VERSION "HINBNNNYNNNNNNNNNNNNNNNNNNNNNNNNNNNYYNNNNN/4>%%%/4/'%**4NNN///"

NS_ :

BS_:

BU_: Traffic Tester RCM FSC EPAS ECB DSC CGW

BO_ 2041 RCM_ISO_SCRAP_Tx: 8 RCM
 SG_ RCM_SCRAP_Diag_Sig_Tx : 7|64@0+ (1,0) [0|0] ""  Tester

BO_ 2033 RCM_ISO_SCRAP_Rx: 8 Tester
 SG_ RCM_SCRAP_Diag_Sig_Rx : 7|64@0+ (1,0) [0|0] ""  RCM

BO_ 2028 BSCM_Diag_Tx: 8 DSC
 SG_ BSCM_Diag_Tx : 7|64@0+ (1,0) [0|0] ""  Tester

BO_ 2020 BSCM_Diag_Rx: 8 Tester
 SG_ BSCM_Diag_Rx : 7|64@0+ (1,0) [0|0] ""  DSC

BO_ 2015 Functional_Diag_Request: 8 Tester
 SG_ OBD_II_Broadcast_Info : 7|64@0+ (1,0) [0|0] ""  RCM,EPAS

BO_ 1896 ABS_Diag_Tx: 8 ECB
 SG_ ABS_Diag_Sig_Tx : 7|64@0+ (1,0) [0|0] ""  Tester

BO_ 1888 ABS_Diag_Rx: 8 Tester
 SG_ ABS_Diag_Sig_Rx : 7|64@0+ (1,0) [0|0] ""  ECB

BO_ 1855 RCM_Diag_Tx: 8 RCM
 SG_ RCM_Diag_Sig_Tx : 7|64@0+ (1,0) [0|0] ""  Tester

BO_ 1848 EPAS_Diag_Tx: 8 EPAS
 SG_ EPAS_Diag_Sig_Tx : 7|64@0+ (1,0) [0|0] ""  Tester

BO_ 1847 RCM_Diag_Rx: 8 Tester
 SG_ RCM_Diag_Sig_Rx : 7|64@0+ (1,0) [0|0] ""  RCM

BO_ 1840 EPAS_Diag_Rx: 8 Tester
 SG_ EPAS_Diag_Sig_Rx : 7|64@0+ (1,0) [0|0] ""  EPAS

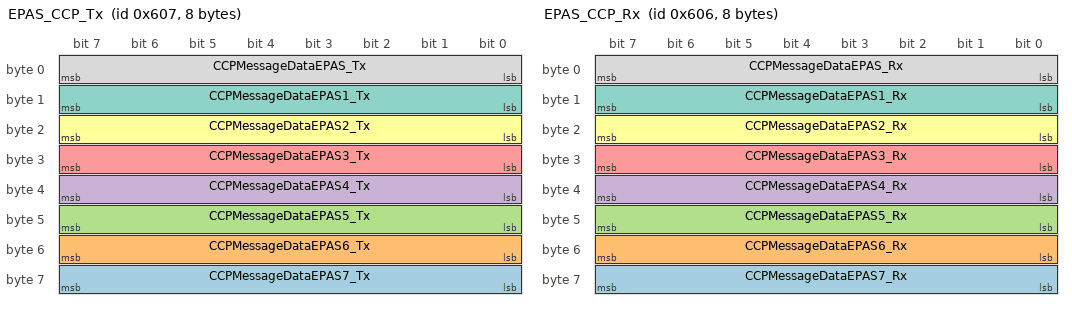
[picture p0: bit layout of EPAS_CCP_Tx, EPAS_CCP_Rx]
BO_ 1543 EPAS_CCP_Tx: 8 EPAS
 SG_ CCPMessageDataEPAS7_Tx : 63|8@0+ (1,0) [0|255] ""  Tester
 SG_ CCPMessageDataEPAS6_Tx : 55|8@0+ (1,0) [0|255] ""  Tester
 SG_ CCPMessageDataEPAS5_Tx : 47|8@0+ (1,0) [0|255] ""  Tester
 SG_ CCPMessageDataEPAS4_Tx : 39|8@0+ (1,0) [0|255] ""  Tester
 SG_ CCPMessageDataEPAS3_Tx : 31|8@0+ (1,0) [0|255] ""  Tester
 SG_ CCPMessageDataEPAS2_Tx : 23|8@0+ (1,0) [0|255] ""  Tester
 SG_ CCPMessageDataEPAS1_Tx : 15|8@0+ (1,0) [0|255] ""  Tester
 SG_ CCPMessageDataEPAS_Tx : 7|8@0+ (1,0) [0|255] ""  Tester

BO_ 1542 EPAS_CCP_Rx: 8 Tester
 SG_ CCPMessageDataEPAS7_Rx : 63|8@0+ (1,0) [0|255] ""  EPAS
 SG_ CCPMessageDataEPAS6_Rx : 55|8@0+ (1,0) [0|255] ""  EPAS
 SG_ CCPMessageDataEPAS5_Rx : 47|8@0+ (1,0) [0|255] ""  EPAS
 SG_ CCPMessageDataEPAS4_Rx : 39|8@0+ (1,0) [0|255] ""  EPAS
 SG_ CCPMessageDataEPAS3_Rx : 31|8@0+ (1,0) [0|255] ""  EPAS
 SG_ CCPMessageDataEPAS2_Rx : 23|8@0+ (1,0) [0|255] ""  EPAS
 SG_ CCPMessageDataEPAS1_Rx : 15|8@0+ (1,0) [0|255] ""  EPAS
 SG_ CCPMessageDataEPAS_Rx : 7|8@0+ (1,0) [0|255] ""  EPAS

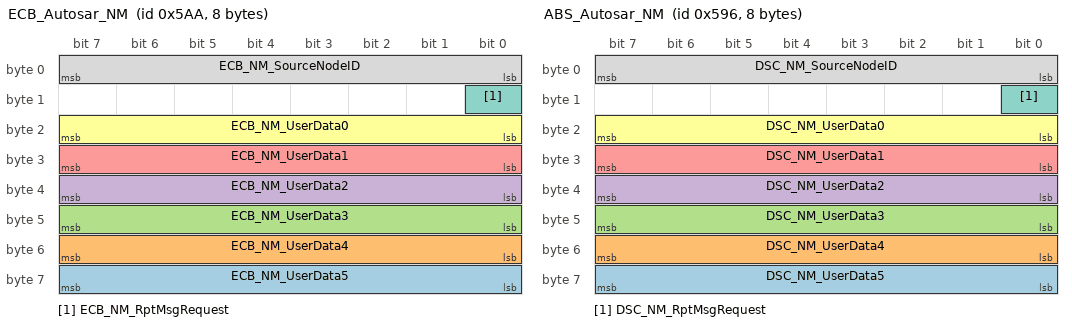
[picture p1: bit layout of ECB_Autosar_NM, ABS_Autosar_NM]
BO_ 1450 ECB_Autosar_NM: 8 ECB
 SG_ ECB_NM_UserData5 : 63|8@0+ (1,0) [0|255] "" Vector__XXX
 SG_ ECB_NM_UserData4 : 55|8@0+ (1,0) [0|255] "" Vector__XXX
 SG_ ECB_NM_UserData3 : 47|8@0+ (1,0) [0|255] "" Vector__XXX
 SG_ ECB_NM_UserData2 : 39|8@0+ (1,0) [0|255] "" Vector__XXX
 SG_ ECB_NM_UserData1 : 31|8@0+ (1,0) [0|255] "" Vector__XXX
 SG_ ECB_NM_UserData0 : 23|8@0+ (1,0) [0|255] "" Vector__XXX
 SG_ ECB_NM_RptMsgRequest : 8|1@0+ (1,0) [0|1] ""  CGW,DSC
 SG_ ECB_NM_SourceNodeID : 7|8@0+ (1,0) [0|255] ""  CGW,DSC

BO_ 1430 ABS_Autosar_NM: 8 DSC
 SG_ DSC_NM_UserData5 : 63|8@0+ (1,0) [0|255] "" Vector__XXX
 SG_ DSC_NM_UserData4 : 55|8@0+ (1,0) [0|255] "" Vector__XXX
 SG_ DSC_NM_UserData3 : 47|8@0+ (1,0) [0|255] "" Vector__XXX
 SG_ DSC_NM_UserData2 : 39|8@0+ (1,0) [0|255] "" Vector__XXX
 SG_ DSC_NM_UserData1 : 31|8@0+ (1,0) [0|255] "" Vector__XXX
 SG_ DSC_NM_UserData0 : 23|8@0+ (1,0) [0|255] "" Vector__XXX
 SG_ DSC_NM_RptMsgRequest : 8|1@0+ (1,0) [0|1] ""  CGW,ECB
 SG_ DSC_NM_SourceNodeID : 7|8@0+ (1,0) [0|255] ""  CGW,ECB

BO_ 1417 ENG1S60: 8 CGW
 SG_ SFTWNG : 19|3@0+ (1,0) [0|7] ""  RCM
 SG_ CDTHVANS : 12|1@0+ (1,0) [0|1] ""  RCM

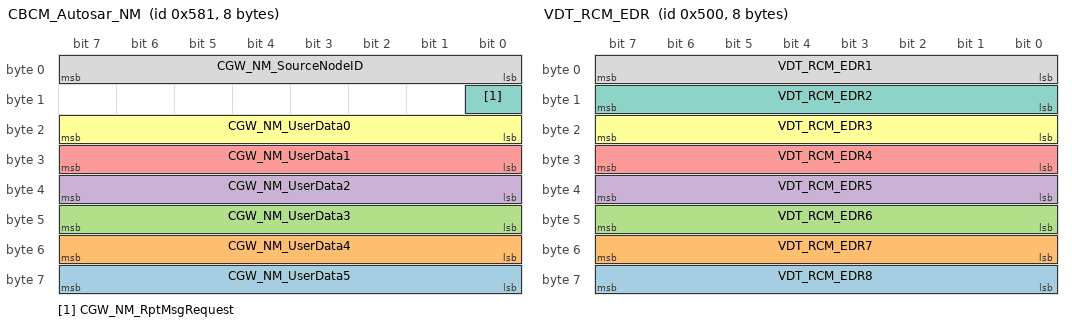
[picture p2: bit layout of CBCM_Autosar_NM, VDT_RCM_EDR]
BO_ 1409 CBCM_Autosar_NM: 8 CGW
 SG_ CGW_NM_UserData5 : 63|8@0+ (1,0) [0|255] "" Vector__XXX
 SG_ CGW_NM_UserData4 : 55|8@0+ (1,0) [0|255] "" Vector__XXX
 SG_ CGW_NM_UserData3 : 47|8@0+ (1,0) [0|255] "" Vector__XXX
 SG_ CGW_NM_UserData2 : 39|8@0+ (1,0) [0|255] "" Vector__XXX
 SG_ CGW_NM_UserData1 : 31|8@0+ (1,0) [0|255] "" Vector__XXX
 SG_ CGW_NM_UserData0 : 23|8@0+ (1,0) [0|255] "" Vector__XXX
 SG_ CGW_NM_RptMsgRequest : 8|1@0+ (1,0) [0|1] ""  DSC
 SG_ CGW_NM_SourceNodeID : 7|8@0+ (1,0) [0|255] ""  DSC

BO_ 1329 ECB_Bus_Status: 8 ECB
 SG_ DiagSupt_Status_ECB m1 : 62|1@0+ (1,0) [0|0] ""  CGW
 SG_ TrigPriority_ECB m1 : 54|8@0+ (1,0) [0|255] "HEX"  CGW
 SG_ TrigReq_ECB m1 : 55|1@0+ (1,0) [0|0] ""  CGW
 SG_ DTC3_Sts_ECB m1 : 47|8@0+ (1,0) [0|255] "HEX"  CGW
 SG_ DTC3_Nbr_ECB m1 : 23|24@0+ (1,0) [0|16777215] "HEX"  CGW
 SG_ DTC2_Sts_ECB m1 : 15|8@0+ (1,0) [0|255] "HEX"  CGW
 SG_ DTC2_Nbr_ECB m0 : 47|24@0+ (1,0) [0|16777215] "HEX"  CGW
 SG_ DTC1_Sts_ECB m0 : 39|8@0+ (1,0) [0|255] "HEX"  CGW
 SG_ DTC1_Nbr_ECB m0 : 15|24@0+ (1,0) [0|16777215] "HEX"  CGW
 SG_ DataNumber_ECB M : 7|8@0+ (1,0) [0|0] ""  CGW

BO_ 1325 RCM_Bus_Status: 8 RCM
 SG_ DiagSupt_Status_RCM m1 : 62|1@0+ (1,0) [0|0] ""  CGW
 SG_ TrigPriority_RCM m1 : 54|8@0+ (1,0) [0|255] "HEX"  CGW
 SG_ TrigReq_RCM m1 : 55|1@0+ (1,0) [0|0] ""  CGW
 SG_ DTC3_Sts_RCM m1 : 47|8@0+ (1,0) [0|255] "HEX"  CGW
 SG_ DTC3_Nbr_RCM m1 : 23|24@0+ (1,0) [0|16777215] "HEX"  CGW
 SG_ DTC2_Sts_RCM m1 : 15|8@0+ (1,0) [0|255] "HEX"  CGW
 SG_ DTC2_Nbr_RCM m0 : 47|24@0+ (1,0) [0|16777215] "HEX"  CGW
 SG_ DTC1_Sts_RCM m0 : 39|8@0+ (1,0) [0|255] "HEX"  CGW
 SG_ DTC1_Nbr_RCM m0 : 15|24@0+ (1,0) [0|16777215] "HEX"  CGW
 SG_ DataNumber_RCM M : 7|8@0+ (1,0) [0|0] ""  CGW

BO_ 1324 EPAS_Bus_Status: 8 EPAS
 SG_ DiagSupt_Status_EPAS m1 : 62|1@0+ (1,0) [0|0] ""  CGW
 SG_ TrigPriority_EPAS m1 : 54|8@0+ (1,0) [0|255] "HEX"  CGW
 SG_ TrigReq_EPAS m1 : 55|1@0+ (1,0) [0|0] ""  CGW
 SG_ DTC3_Sts_EPAS m1 : 47|8@0+ (1,0) [0|255] "HEX"  CGW
 SG_ DTC3_Nbr_EPAS m1 : 23|24@0+ (1,0) [0|16777215] "HEX"  CGW
 SG_ DTC2_Sts_EPAS m1 : 15|8@0+ (1,0) [0|255] "HEX"  CGW
 SG_ DTC2_Nbr_EPAS m0 : 47|24@0+ (1,0) [0|16777215] "HEX"  CGW
 SG_ DTC1_Sts_EPAS m0 : 39|8@0+ (1,0) [0|255] "HEX"  CGW
 SG_ DTC1_Nbr_EPAS m0 : 15|24@0+ (1,0) [0|16777215] "HEX"  CGW
 SG_ DataNumber_EPAS M : 7|8@0+ (1,0) [0|0] ""  CGW

BO_ 1307 DSC_Bus_Status: 8 DSC
 SG_ DiagSupt_Status_DSC m1 : 62|1@0+ (1,0) [0|0] ""  CGW
 SG_ TrigPriority_DSC m1 : 54|8@0+ (1,0) [0|255] "HEX"  CGW
 SG_ TrigReq_DSC m1 : 55|1@0+ (1,0) [0|0] ""  CGW
 SG_ DTC3_Sts_DSC m1 : 47|8@0+ (1,0) [0|255] "HEX"  CGW
 SG_ DTC3_Nbr_DSC m1 : 23|24@0+ (1,0) [0|16777215] "HEX"  CGW
 SG_ DTC2_Sts_DSC m1 : 15|8@0+ (1,0) [0|255] "HEX"  CGW
 SG_ DTC2_Nbr_DSC m0 : 47|24@0+ (1,0) [0|16777215] "HEX"  CGW
 SG_ DTC1_Sts_DSC m0 : 39|8@0+ (1,0) [0|255] "HEX"  CGW
 SG_ DTC1_Nbr_DSC m0 : 15|24@0+ (1,0) [0|16777215] "HEX"  CGW
 SG_ DataNumber_DSC M : 7|8@0+ (1,0) [0|0] ""  CGW

BO_ 1280 VDT_RCM_EDR: 8 RCM
 SG_ VDT_RCM_EDR8 : 63|8@0+ (1,0) [0|255] ""  CGW
 SG_ VDT_RCM_EDR7 : 55|8@0+ (1,0) [0|255] ""  CGW
 SG_ VDT_RCM_EDR6 : 47|8@0+ (1,0) [0|255] ""  CGW
 SG_ VDT_RCM_EDR5 : 39|8@0+ (1,0) [0|255] ""  CGW
 SG_ VDT_RCM_EDR4 : 31|8@0+ (1,0) [0|255] ""  CGW
 SG_ VDT_RCM_EDR3 : 23|8@0+ (1,0) [0|255] ""  CGW
 SG_ VDT_RCM_EDR2 : 15|8@0+ (1,0) [0|255] ""  CGW
 SG_ VDT_RCM_EDR1 : 7|8@0+ (1,0) [0|255] ""  CGW

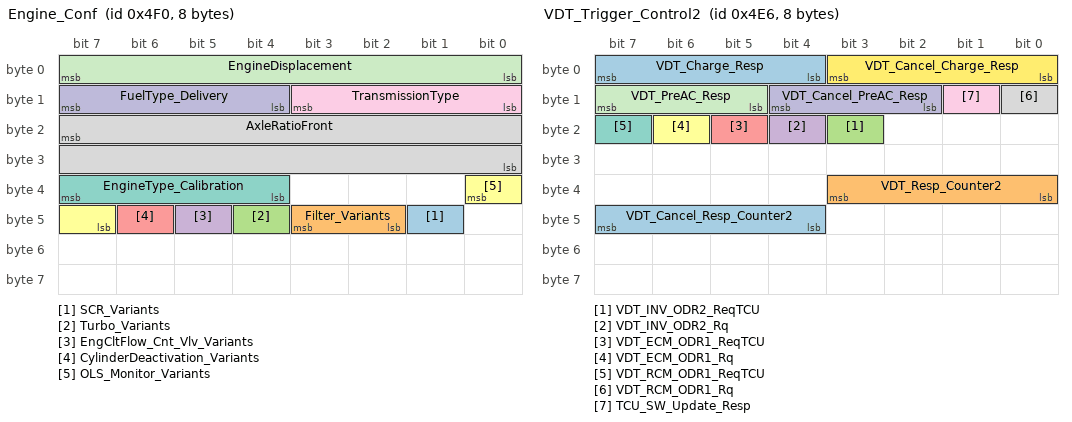
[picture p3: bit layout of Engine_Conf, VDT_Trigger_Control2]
BO_ 1264 Engine_Conf: 8 CGW
 SG_ SCR_Variants : 41|1@0+ (1,0) [0|0] "" Vector__XXX
 SG_ Filter_Variants : 43|2@0+ (1,0) [0|0] "" Vector__XXX
 SG_ Turbo_Variants : 44|1@0+ (1,0) [0|0] "" Vector__XXX
 SG_ EngCltFlow_Cnt_Vlv_Variants : 45|1@0+ (1,0) [0|0] "" Vector__XXX
 SG_ CylinderDeactivation_Variants : 46|1@0+ (1,0) [0|0] "" Vector__XXX
 SG_ OLS_Monitor_Variants : 32|2@0+ (1,0) [0|0] "" Vector__XXX
 SG_ EngineType_Calibration : 39|4@0+ (1,0) [0|0] "" Vector__XXX
 SG_ AxleRatioFront : 23|16@0+ (0.01,0) [0|15] "" Vector__XXX
 SG_ TransmissionType : 11|4@0+ (1,0) [0|0] ""  RCM
 SG_ FuelType_Delivery : 15|4@0+ (1,0) [0|0] "" Vector__XXX
 SG_ EngineDisplacement : 7|8@0+ (0.1,0) [0|25.5] "Litres" Vector__XXX

BO_ 1254 VDT_Trigger_Control2: 8 CGW
 SG_ VDT_Cancel_Resp_Counter2 : 47|4@0+ (1,0) [0|15] "" Vector__XXX
 SG_ VDT_Resp_Counter2 : 35|4@0+ (1,0) [0|15] "" Vector__XXX
 SG_ VDT_INV_ODR2_ReqTCU : 19|1@0+ (1,0) [0|0] "" Vector__XXX
 SG_ VDT_INV_ODR2_Rq : 20|1@0+ (1,0) [0|0] "" Vector__XXX
 SG_ VDT_ECM_ODR1_ReqTCU : 21|1@0+ (1,0) [0|0] "" Vector__XXX
 SG_ VDT_ECM_ODR1_Rq : 22|1@0+ (1,0) [0|0] "" Vector__XXX
 SG_ VDT_RCM_ODR1_ReqTCU : 23|1@0+ (1,0) [0|0] "" Vector__XXX
 SG_ VDT_RCM_ODR1_Rq : 8|1@0+ (1,0) [0|0] ""  RCM
 SG_ TCU_SW_Update_Resp : 9|1@0+ (1,0) [0|0] "" Vector__XXX
 SG_ VDT_Cancel_PreAC_Resp : 12|3@0+ (1,0) [0|0] "" Vector__XXX
 SG_ VDT_PreAC_Resp : 15|3@0+ (1,0) [0|0] "" Vector__XXX
 SG_ VDT_Cancel_Charge_Resp : 3|4@0+ (1,0) [0|0] "" Vector__XXX
 SG_ VDT_Charge_Resp : 7|4@0+ (1,0) [0|0] "" Vector__XXX

BO_ 1170 VCM_Customize_Status_01: 8 CGW
 SG_ CstmzStat_CTS_HighWay : 59|2@0+ (1,0) [0|0] "" Vector__XXX
 SG_ CstmzStat_FCTA_ONOFF : 61|2@0+ (1,0) [0|0] "" Vector__XXX
 SG_ CstmzStat_FCTA_Sens : 63|2@0+ (1,0) [0|0] "" Vector__XXX
 SG_ CstmzStat_TAP_ONOFF : 49|2@0+ (1,0) [0|0] "" Vector__XXX
 SG_ CstmzStat_ELK_ONOFF : 51|2@0+ (1,0) [0|0] "" Vector__XXX
 SG_ CstmzStat_RAEB_ONOFF : 53|2@0+ (1,0) [0|0] "" Vector__XXX
 SG_ CstmzStat_FAEB_Sens : 55|2@0+ (1,0) [0|0] "" Vector__XXX
 SG_ CstmzStat_FAEB_ONOFF : 41|2@0+ (1,0) [0|0] ""  RCM
 SG_ CstmzStat_CTB_ONOFF : 43|2@0+ (1,0) [0|0] "" Vector__XXX
 SG_ CstmzStat_LDP_ONOFF : 45|2@0+ (1,0) [0|0] "" Vector__XXX
 SG_ CstmzStat_DAS_ONOFF : 47|2@0+ (1,0) [0|0] "" Vector__XXX
 SG_ CstmzStat_LDP_RDP_Warn : 33|2@0+ (1,0) [0|0] "" Vector__XXX
 SG_ CstmzStat_BSM_Sens : 35|2@0+ (1,0) [0|0] "" Vector__XXX
 SG_ CstmzStat_BSM_ONOFF : 37|2@0+ (1,0) [0|0] "" Vector__XXX
 SG_ CstmzStat_LDW_ONOFF : 39|2@0+ (1,0) [0|0] "" Vector__XXX
 SG_ CstmzStat_RCTB_ONOFF : 25|2@0+ (1,0) [0|0] "" Vector__XXX
 SG_ CstmzStat_FCTB_Disp_ONOFF : 27|2@0+ (1,0) [0|0] "" Vector__XXX
 SG_ CstmzStat_FCTB_ONOFF : 29|2@0+ (1,0) [0|0] "" Vector__XXX
 SG_ CstmzStat_SpLmt_Warn_Thres : 16|3@0+ (1,0) [0|0] "" Vector__XXX
 SG_ CstmzStat_SpLmt_Warn : 18|2@0+ (1,0) [0|0] "" Vector__XXX
 SG_ CstmzStat_TSR_Warn_Thres : 21|3@0+ (1,0) [0|0] "" Vector__XXX
 SG_ CstmzStat_TSR_Warn : 23|2@0+ (1,0) [0|0] "" Vector__XXX
 SG_ CstmzStat_MRCC_Bz_ONOFF : 9|2@0+ (1,0) [0|0] "" Vector__XXX
 SG_ CstmzStat_TSR_Mode : 11|2@0+ (1,0) [0|0] "" Vector__XXX
 SG_ CstmzStat_MRCC_ASC_Mode : 13|2@0+ (1,0) [0|0] "" Vector__XXX
 SG_ CstmzStat_TJA_Mode : 15|2@0+ (1,0) [0|0] "" Vector__XXX
 SG_ Target_ID_VStat01 : 7|4@0+ (1,0) [0|15] "" Vector__XXX

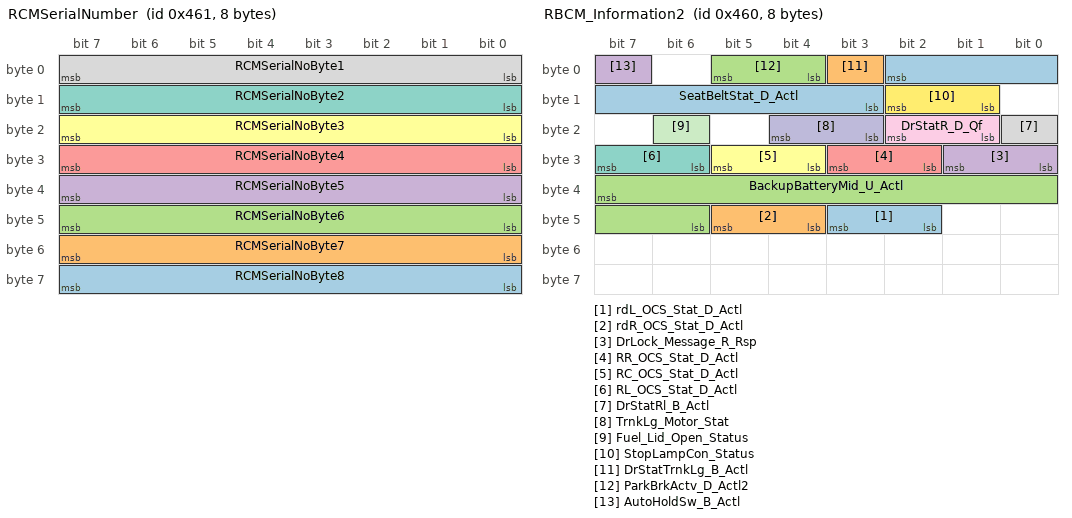
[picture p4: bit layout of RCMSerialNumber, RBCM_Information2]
BO_ 1121 RCMSerialNumber: 8 RCM
 SG_ RCMSerialNoByte8 : 63|8@0+ (1,0) [0|253] ""  CGW
 SG_ RCMSerialNoByte7 : 55|8@0+ (1,0) [0|253] ""  CGW
 SG_ RCMSerialNoByte6 : 47|8@0+ (1,0) [0|253] ""  CGW
 SG_ RCMSerialNoByte5 : 39|8@0+ (1,0) [0|253] ""  CGW
 SG_ RCMSerialNoByte4 : 31|8@0+ (1,0) [0|253] ""  CGW
 SG_ RCMSerialNoByte3 : 23|8@0+ (1,0) [0|253] ""  CGW
 SG_ RCMSerialNoByte2 : 15|8@0+ (1,0) [0|253] ""  CGW
 SG_ RCMSerialNoByte1 : 7|8@0+ (1,0) [0|253] ""  CGW

BO_ 1120 RBCM_Information2: 8 CGW
 SG_ rdL_OCS_Stat_D_Actl : 43|2@0+ (1,0) [0|0] "" Vector__XXX
 SG_ rdR_OCS_Stat_D_Actl : 45|2@0+ (1,0) [0|0] "" Vector__XXX
 SG_ BackupBatteryMid_U_Actl : 39|10@0+ (0.02,0) [0|20.44] "V" Vector__XXX
 SG_ DrLock_Message_R_Rsp : 25|2@0+ (1,0) [0|0] "" Vector__XXX
 SG_ RR_OCS_Stat_D_Actl : 27|2@0+ (1,0) [0|0] "" Vector__XXX
 SG_ RC_OCS_Stat_D_Actl : 29|2@0+ (1,0) [0|0] "" Vector__XXX
 SG_ RL_OCS_Stat_D_Actl : 31|2@0+ (1,0) [0|0] "" Vector__XXX
 SG_ DrStatRl_B_Actl : 16|1@0+ (1,0) [0|0] "" Vector__XXX
 SG_ DrStatR_D_Qf : 18|2@0+ (1,0) [0|0] "" Vector__XXX
 SG_ TrnkLg_Motor_Stat : 20|2@0+ (1,0) [0|0] "" Vector__XXX
 SG_ Fuel_Lid_Open_Status : 22|1@0+ (1,0) [0|0] "" Vector__XXX
 SG_ StopLampCon_Status : 10|2@0+ (1,0) [0|0] ""  DSC,ECB
 SG_ SeatBeltStat_D_Actl : 2|8@0+ (1,0) [0|255] ""  RCM
 SG_ DrStatTrnkLg_B_Actl : 3|1@0+ (1,0) [0|0] "" Vector__XXX
 SG_ ParkBrkActv_D_Actl2 : 5|2@0+ (1,0) [0|0] ""  DSC
 SG_ AutoHoldSw_B_Actl : 7|1@0+ (1,0) [0|0] ""  DSC

BO_ 1106 ADAS_HMI_Information12: 8 CGW
 SG_ CBDA_target_lh : 57|2@0+ (1,0) [0|0] "" Vector__XXX
 SG_ CBDA_target_rh : 59|2@0+ (1,0) [0|0] "" Vector__XXX
 SG_ CBDA_EV_failure : 60|1@0+ (1,0) [0|0] "" Vector__XXX
 SG_ CBDA_EV_tmp_failure : 61|1@0+ (1,0) [0|0] "" Vector__XXX
 SG_ CBDA_EV_fallback : 62|1@0+ (1,0) [0|0] "" Vector__XXX
 SG_ CBDA_fallback : 63|1@0+ (1,0) [0|0] "" Vector__XXX
 SG_ CBDA_state : 51|4@0+ (1,0) [0|0] "" Vector__XXX
 SG_ LDW_lane_lh : 55|2@0+ (1,0) [0|0] ""  RCM
 SG_ LDW_lane_rh : 41|2@0+ (1,0) [0|0] ""  RCM
 SG_ LDW_EV_failure : 42|1@0+ (1,0) [0|0] "" Vector__XXX
 SG_ LDW_EV_tmp_failure : 43|1@0+ (1,0) [0|0] "" Vector__XXX
 SG_ LDW_EV_warning_rh : 44|1@0+ (1,0) [0|0] "" Vector__XXX
 SG_ LDW_EV_warning_lh : 45|1@0+ (1,0) [0|0] "" Vector__XXX
 SG_ LDW_fallback : 46|1@0+ (1,0) [0|0] "" Vector__XXX
 SG_ LDW_state : 34|4@0+ (1,0) [0|0] ""  RCM
 SG_ OCP_opp_lh : 39|2@0+ (1,0) [0|0] "" Vector__XXX
 SG_ OCP_opp_rh : 25|2@0+ (1,0) [0|0] "" Vector__XXX
 SG_ OCP_lane_lh : 27|2@0+ (1,0) [0|0] "" Vector__XXX
 SG_ OCP_lane_rh : 29|2@0+ (1,0) [0|0] "" Vector__XXX
 SG_ OCP_EV_failure : 30|1@0+ (1,0) [0|0] "" Vector__XXX
 SG_ OCP_EV_tmp_failure : 31|1@0+ (1,0) [0|0] "" Vector__XXX
 SG_ OCP_alarm : 16|1@0+ (1,0) [0|0] "" Vector__XXX
 SG_ OCP_fallback : 17|1@0+ (1,0) [0|0] "" Vector__XXX
 SG_ OCP_state : 21|4@0+ (1,0) [0|0] ""  RCM
 SG_ BSP_alarm : 8|1@0+ (1,0) [0|0] "" Vector__XXX
 SG_ BSP_target_lh : 10|2@0+ (1,0) [0|0] "" Vector__XXX
 SG_ BSP_target_rh : 12|2@0+ (1,0) [0|0] "" Vector__XXX
 SG_ BSP_lane_lh : 14|2@0+ (1,0) [0|0] "" Vector__XXX
 SG_ BSP_lane_rh : 0|2@0+ (1,0) [0|0] "" Vector__XXX
 SG_ BSP_EV_failure : 1|1@0+ (1,0) [0|0] "" Vector__XXX
 SG_ BSP_EV_tmp_failure : 2|1@0+ (1,0) [0|0] "" Vector__XXX
 SG_ BSP_fallback : 3|1@0+ (1,0) [0|0] "" Vector__XXX
 SG_ BSP_state : 7|4@0+ (1,0) [0|0] ""  RCM

BO_ 1099 ADAS_HMI_Information5: 8 CGW
 SG_ REDKEY_EV_on : 56|1@0+ (1,0) [0|0] "" Vector__XXX
 SG_ REDKEY_state : 60|4@0+ (1,0) [0|0] "" Vector__XXX
 SG_ ISA_EV_failure : 33|1@0+ (1,0) [0|0] "" Vector__XXX
 SG_ ISA_EV_fallback : 34|1@0+ (1,0) [0|0] "" Vector__XXX
 SG_ ISA_EV_kickdown : 35|1@0+ (1,0) [0|0] "" Vector__XXX
 SG_ ISA_EV_reject : 38|1@0+ (1,0) [0|0] "" Vector__XXX
 SG_ ISA_EV_spd_autoset : 39|1@0+ (1,0) [0|0] "" Vector__XXX
 SG_ ISA_overspeed : 25|2@0+ (1,0) [0|0] "" Vector__XXX
 SG_ ISA_sign : 27|2@0+ (1,0) [0|0] "" Vector__XXX
 SG_ ISA_state : 31|4@0+ (1,0) [0|0] ""  DSC
 SG_ ISA_fallback : 17|2@0+ (1,0) [0|0] "" Vector__XXX
 SG_ ASC_EV_failure : 15|1@0+ (1,0) [0|0] "" Vector__XXX
 SG_ ASC_EV_fallback : 0|1@0+ (1,0) [0|0] "" Vector__XXX
 SG_ ASC_EV_suspended : 1|1@0+ (1,0) [0|0] "" Vector__XXX
 SG_ ASC_EV_reject : 2|1@0+ (1,0) [0|0] "" Vector__XXX
 SG_ ASC_EV_accept : 3|1@0+ (1,0) [0|0] "" Vector__XXX
 SG_ ASC_state : 7|4@0+ (1,0) [0|0] ""  DSC,RCM

BO_ 1098 ADAS_HMI_Information4: 8 CGW
 SG_ LKA_target : 60|3@0+ (1,0) [0|0] "" Vector__XXX
 SG_ LKA_EV_dassw_reject : 61|1@0+ (1,0) [0|0] "" Vector__XXX
 SG_ LKA_EV_failure : 62|1@0+ (1,0) [0|0] "" Vector__XXX
 SG_ LKA_EV_tmp_failure : 63|1@0+ (1,0) [0|0] "" Vector__XXX
 SG_ LKA_EV_fallback : 48|1@0+ (1,0) [0|0] "" Vector__XXX
 SG_ LKA_EV_suspended : 49|1@0+ (1,0) [0|0] "" Vector__XXX
 SG_ LKA_handsfree : 52|3@0+ (1,0) [0|0] "" Vector__XXX
 SG_ LKA_EV_reject : 53|1@0+ (1,0) [0|0] "" Vector__XXX
 SG_ LKA_control_limit_rh : 54|1@0+ (1,0) [0|0] "" Vector__XXX
 SG_ LKA_control_limit_lh : 55|1@0+ (1,0) [0|0] "" Vector__XXX
 SG_ LKA_fallback : 41|1@0+ (1,0) [0|0] "" Vector__XXX
 SG_ LKA_EV_inactive_handsfree : 42|1@0+ (1,0) [0|0] "" Vector__XXX
 SG_ LKA_EV_inactive_handson : 43|1@0+ (1,0) [0|0] "" Vector__XXX
 SG_ LKA_state : 47|4@0+ (1,0) [0|0] ""  RCM
 SG_ ACC_target_distance : 35|4@0+ (1,0) [0|0] "" Vector__XXX
 SG_ ACC_set_distance : 38|3@0+ (1,0) [0|0] "" Vector__XXX
 SG_ ACC_set_velocity : 30|8@0+ (1,0) [0|250] "Unitless" Vector__XXX
 SG_ ACC_EV_dassw_reject : 31|1@0+ (1,0) [0|0] "" Vector__XXX
 SG_ ACC_EV_set_dist : 16|1@0+ (1,0) [0|0] "" Vector__XXX
 SG_ ACC_EV_failure : 17|1@0+ (1,0) [0|0] "" Vector__XXX
 SG_ ACC_EV_tmp_failure : 18|1@0+ (1,0) [0|0] "" Vector__XXX
 SG_ ACC_EV_fallback2 : 19|1@0+ (1,0) [0|0] "" Vector__XXX
 SG_ ACC_EV_fallback1 : 20|1@0+ (1,0) [0|0] "" Vector__XXX
 SG_ ACC_EV_suspended : 21|1@0+ (1,0) [0|0] "" Vector__XXX
 SG_ ACC_EV_start : 22|1@0+ (1,0) [0|0] "" Vector__XXX
 SG_ ACC_shift_position : 8|2@0+ (1,0) [0|0] "" Vector__XXX
 SG_ ACC_warning : 9|1@0+ (1,0) [0|0] "" Vector__XXX
 SG_ ACC_EV_reject : 10|1@0+ (1,0) [0|0] "" Vector__XXX
 SG_ ACC_EV_accept : 11|1@0+ (1,0) [0|0] "" Vector__XXX
 SG_ ACC_fallback : 13|2@0+ (1,0) [0|0] "" Vector__XXX
 SG_ ACC_target : 15|2@0+ (1,0) [0|0] "" Vector__XXX
 SG_ ACC_stop : 0|1@0+ (1,0) [0|0] "" Vector__XXX
 SG_ ACC_sign : 3|3@0+ (1,0) [0|0] "" Vector__XXX
 SG_ ACC_state : 7|4@0+ (1,0) [0|0] ""  DSC,RCM

BO_ 1096 ADAS_HMI_Information2: 8 CGW
 SG_ LDP_alarm : 62|1@0+ (1,0) [0|0] "" Vector__XXX
 SG_ LDP_fallback : 48|1@0+ (1,0) [0|0] "" Vector__XXX
 SG_ LDP_EV_failure : 49|1@0+ (1,0) [0|0] "" Vector__XXX
 SG_ LDP_EV_tmp_failure : 50|1@0+ (1,0) [0|0] "" Vector__XXX
 SG_ LDP_EV_warning_rh : 53|1@0+ (1,0) [0|0] "" Vector__XXX
 SG_ LDP_EV_warning_lh : 54|1@0+ (1,0) [0|0] "" Vector__XXX
 SG_ LDP_lane_lh : 40|2@0+ (1,0) [0|0] "" Vector__XXX
 SG_ LDP_lane_rh : 42|2@0+ (1,0) [0|0] "" Vector__XXX
 SG_ LDP_state : 46|4@0+ (1,0) [0|0] ""  RCM
 SG_ BSM_EV_failure : 32|1@0+ (1,0) [0|0] "" Vector__XXX
 SG_ BSM_EV_tmp_failure : 33|1@0+ (1,0) [0|0] "" Vector__XXX
 SG_ BSM_EV_warning_rh : 37|1@0+ (1,0) [0|0] "" Vector__XXX
 SG_ BSM_EV_warning_lh : 38|1@0+ (1,0) [0|0] "" Vector__XXX
 SG_ BSM_fallback : 39|1@0+ (1,0) [0|0] "" Vector__XXX
 SG_ BSM_target_lh : 25|2@0+ (1,0) [0|0] "" Vector__XXX
 SG_ BSM_target_rh : 27|2@0+ (1,0) [0|0] "" Vector__XXX
 SG_ BSM_state : 31|4@0+ (1,0) [0|0] "" Vector__XXX
 SG_ RDP_alarm : 23|1@0+ (1,0) [0|0] "" Vector__XXX
 SG_ RDP_fallback : 9|1@0+ (1,0) [0|0] "" Vector__XXX
 SG_ RDP_EV_failure : 10|1@0+ (1,0) [0|0] "" Vector__XXX
 SG_ RDP_EV_tmp_failure : 11|1@0+ (1,0) [0|0] "" Vector__XXX
 SG_ RDP_roadedge_lh : 1|2@0+ (1,0) [0|0] "" Vector__XXX
 SG_ RDP_roadedge_rh : 3|2@0+ (1,0) [0|0] "" Vector__XXX
 SG_ RDP_state : 7|4@0+ (1,0) [0|0] ""  RCM

BO_ 1095 ADAS_HMI_Information1: 8 CGW
 SG_ ID447_No_Cs : 63|8@0+ (1,0) [0|255] "" Vector__XXX
 SG_ ID447_No_Cnt : 51|4@0+ (1,0) [0|15] "" Vector__XXX
 SG_ CTB_target_lh : 54|2@0+ (1,0) [0|0] "" Vector__XXX
 SG_ CTB_target_rh : 40|2@0+ (1,0) [0|0] "" Vector__XXX
 SG_ CTB_EV_failure : 41|1@0+ (1,0) [0|0] "" Vector__XXX
 SG_ CTB_EV_tmp_failure : 42|1@0+ (1,0) [0|0] "" Vector__XXX
 SG_ CTB_EV_fallback : 43|1@0+ (1,0) [0|0] "" Vector__XXX
 SG_ CTB_EV_notification : 44|1@0+ (1,0) [0|0] "" Vector__XXX
 SG_ CTB_EV_warning : 45|1@0+ (1,0) [0|0] "" Vector__XXX
 SG_ CTB_EV_off : 46|1@0+ (1,0) [0|0] "" Vector__XXX
 SG_ CTB_fallback : 32|2@0+ (1,0) [0|0] "" Vector__XXX
 SG_ CTB_state : 36|4@0+ (1,0) [0|0] "" Vector__XXX
 SG_ FCTA_target_lh : 24|2@0+ (1,0) [0|0] "" Vector__XXX
 SG_ FCTA_target_rh : 26|2@0+ (1,0) [0|0] "" Vector__XXX
 SG_ FCTA_EV_failure : 27|1@0+ (1,0) [0|0] "" Vector__XXX
 SG_ FCTA_EV_tmp_failure : 28|1@0+ (1,0) [0|0] "" Vector__XXX
 SG_ FCTA_EV_fallback : 29|1@0+ (1,0) [0|0] "" Vector__XXX
 SG_ FCTA_EV_warning2_rh : 30|1@0+ (1,0) [0|0] "" Vector__XXX
 SG_ FCTA_EV_warning2_lh : 31|1@0+ (1,0) [0|0] "" Vector__XXX
 SG_ FCTA_fallback : 16|1@0+ (1,0) [0|0] "" Vector__XXX
 SG_ FCTA_state : 20|4@0+ (1,0) [0|0] "" Vector__XXX
 SG_ PTC_EV_off : 23|1@0+ (1,0) [0|0] "" Vector__XXX
 SG_ PTC_EV_notification : 8|1@0+ (1,0) [0|0] "" Vector__XXX
 SG_ PTC_fallback : 10|2@0+ (1,0) [0|0] "" Vector__XXX
 SG_ PTC_state : 14|4@0+ (1,0) [0|0] "" Vector__XXX
 SG_ AEB_EV_notification : 0|1@0+ (1,0) [0|0] ""  RCM
 SG_ AEB_EV_off : 1|1@0+ (1,0) [0|0] ""  RCM
 SG_ AEB_fallback : 3|2@0+ (1,0) [0|0] ""  RCM
 SG_ AEB_state : 7|4@0+ (1,0) [0|0] ""  RCM

BO_ 1088 Door_D_Message: 8 CGW
 SG_ DOORDMSG_No_Cs : 63|8@0+ (1,0) [0|255] "" Vector__XXX
 SG_ DOORDMSG_No_Cnt : 51|4@0+ (1,0) [0|15] "" Vector__XXX
 SG_ Move_AutoDposMirror_Res : 53|2@0+ (1,0) [0|0] "" Vector__XXX
 SG_ BackupBatteryOut_Drv_U_Act : 47|10@0+ (0.02,0) [0|20.44] "V" Vector__XXX
 SG_ MirrorLED1_status : 32|1@0+ (1,0) [0|0] "" Vector__XXX
 SG_ DrLock_Message_D_Rsp : 34|2@0+ (1,0) [0|0] "" Vector__XXX
 SG_ DrivingPositionRequest : 36|2@0+ (1,0) [0|0] "" Vector__XXX
 SG_ Mirror_AjustSelSW_Status : 38|2@0+ (1,0) [0|0] "" Vector__XXX
 SG_ MirrorFoldRequest : 24|2@0+ (1,0) [0|0] "" Vector__XXX
 SG_ MirrorAdjustRequest : 27|3@0+ (1,0) [0|0] "" Vector__XXX
 SG_ MirrorAdjst_Manual_Status : 28|1@0+ (1,0) [0|0] "" Vector__XXX
 SG_ MirrorAdjst_Status : 29|1@0+ (1,0) [0|0] "" Vector__XXX
 SG_ Erase_MirrorMem_Res : 31|2@0+ (1,0) [0|0] "" Vector__XXX
 SG_ Recall_MirrorMem_Res : 17|2@0+ (1,0) [0|0] "" Vector__XXX
 SG_ Record_MirrorMem_Res : 19|2@0+ (1,0) [0|0] "" Vector__XXX
 SG_ PW_Move_R : 22|3@0+ (1,0) [0|0] "" Vector__XXX
 SG_ PW_Move_P : 9|3@0+ (1,0) [0|0] "" Vector__XXX
 SG_ PWcut_D_Actl : 11|2@0+ (1,0) [0|0] "" Vector__XXX
 SG_ DrvDLMotorDriveStat : 15|4@0+ (1,0) [0|0] "" Vector__XXX
 SG_ Ctrl_DLSw_Drv_Stat : 1|2@0+ (1,0) [0|0] "" Vector__XXX
 SG_ LockLinkSwDrv_D_Actl : 3|2@0+ (1,0) [0|0] "" Vector__XXX
 SG_ DrStatDrv_D_Qf : 6|2@0+ (1,0) [0|0] ""  DSC
 SG_ DrStatDrv_B_Actl : 7|1@0+ (1,0) [0|0] ""  DSC

BO_ 1081 LocateTime_Info: 8 CGW
 SG_ GMT_Second_ByGPS m3 : 55|8@0+ (1,0) [0|60] "Second" Vector__XXX
 SG_ GMT_Minutes_ByGPS m3 : 47|8@0+ (1,0) [0|60] "Minute" Vector__XXX
 SG_ GMT_Hour_ByGPS m3 : 39|8@0+ (1,0) [0|24] "Hour" Vector__XXX
 SG_ GMT_Date_ByGPS m3 : 31|8@0+ (1,0) [1|31] "day" Vector__XXX
 SG_ GMT_Month_ByGPS m3 : 23|8@0+ (1,0) [1|12] "month" Vector__XXX
 SG_ GMT_Year_ByGPS m3 : 15|8@0+ (1,2018) [2018|2272] "year" Vector__XXX
 SG_ HorizonByGPS m2 : 15|32@0+ (0.01,-10000) [-10000|10000] "meter" Vector__XXX
 SG_ Curnt_Second_ByGPS m1 : 63|8@0+ (1,0) [0|60] "Second"  RCM
 SG_ Curnt_Minutes_ByGPS m1 : 55|8@0+ (1,0) [0|60] "Minute"  RCM
 SG_ Curnt_Hour_ByGPS m1 : 47|8@0+ (1,0) [0|24] "Hour"  RCM
 SG_ LongitudeByGPS m1 : 15|32@0+ (1E-007,-180) [-180|180] "degree" Vector__XXX
 SG_ Curnt_Date_ByGPS m0 : 63|8@0+ (1,0) [1|31] "day"  RCM
 SG_ Curnt_Month_ByGPS m0 : 55|8@0+ (1,0) [1|12] "month"  RCM
 SG_ Curnt_Year_ByGPS m0 : 47|8@0+ (1,2018) [2018|2272] "year"  RCM
 SG_ LatitudeByGPS m0 : 15|32@0+ (1E-007,-90) [-90|90] "degree" Vector__XXX
 SG_ LocateTime_Info_Data_Number M : 7|8@0+ (1,0) [0|0] ""  RCM

BO_ 1078 Hvac_Control_Information2: 8 CGW
 SG_ SteerHeatIndic_D_Req : 57|2@0+ (1,0) [0|0] "" Vector__XXX
 SG_ SteerHeat_Elm_Enable : 52|2@0+ (1,0) [0|0] "" Vector__XXX
 SG_ SeatHeat_Elm_Enable : 54|2@0+ (1,0) [0|0] "" Vector__XXX
 SG_ Charge_Mode_Enabled_SW : 40|2@0+ (1,0) [0|0] "" Vector__XXX
 SG_ Drive_Mode_Enabled_Switch : 42|2@0+ (1,0) [0|0] "" Vector__XXX
 SG_ atcControlStatus : 45|3@0+ (1,0) [0|0] "" Vector__XXX
 SG_ SeatVentIndicFr_D_Req : 32|3@0+ (1,0) [0|0] "" Vector__XXX
 SG_ SeatVentIndicFl_D_Req : 35|3@0+ (1,0) [0|0] "" Vector__XXX
 SG_ SeatHeatIndicFr_D_Req : 38|3@0+ (1,0) [0|0] "" Vector__XXX
 SG_ SeatHeatIndicFl_D_Req : 25|3@0+ (1,0) [0|0] "" Vector__XXX
 SG_ atcACmodeDisp : 28|3@0+ (1,0) [0|0] "" Vector__XXX
 SG_ atcAImodeDisp : 16|4@0+ (1,0) [0|0] "" Vector__XXX
 SG_ atcADmodeDisp : 20|4@0+ (1,0) [0|0] "" Vector__XXX
 SG_ atcBlwLvlDisp : 8|4@0+ (1,0) [0|0] "" Vector__XXX
 SG_ HvacEngStopCtrl_D_Actl : 10|2@0+ (1,0) [0|0] "" Vector__XXX
 SG_ BlowerSpeed : 1|4@0+ (1,0) [0|0] "" Vector__XXX
 SG_ HvacEngStopInputFail_D_Rq : 4|3@0+ (1,0) [0|0] "" Vector__XXX
 SG_ HvacAirCond_B_Rq : 5|1@0+ (1,0) [0|0] "" Vector__XXX
 SG_ HvacEngStopDis_B_Rq_exceptTEva : 6|1@0+ (1,0) [0|0] "" Vector__XXX
 SG_ HvacEngStopDis_B_Rq : 7|1@0+ (1,0) [0|0] "" Vector__XXX

BO_ 1077 TPMS_Control: 8 CGW
 SG_ RR_TPrs_Correct m5 : 39|8@0+ (1.373,0) [0|347.369] "kPa" Vector__XXX
 SG_ RL_TPrs_Correct m5 : 31|8@0+ (1.373,0) [0|347.369] "kPa" Vector__XXX
 SG_ FR_TPrs_Correct m5 : 23|8@0+ (1.373,0) [0|347.369] "kPa" Vector__XXX
 SG_ FL_TPrs_Correct m5 : 15|8@0+ (1.373,0) [0|347.369] "kPa" Vector__XXX
 SG_ MntOilLvl_AtFlg m4 : 56|1@0+ (1,0) [0|0] "" Vector__XXX
 SG_ TPrs_Disp_Minute m4 : 47|8@0+ (1,0) [0|59] "minute" Vector__XXX
 SG_ TPrs_Disp_Hour m4 : 39|8@0+ (1,0) [0|23] "hour" Vector__XXX
 SG_ TPrs_Disp_Date m4 : 31|8@0+ (1,0) [0|31] "day" Vector__XXX
 SG_ TPrs_Disp_Month m4 : 23|8@0+ (1,0) [0|12] "month" Vector__XXX
 SG_ TPrs_Disp_Year m4 : 15|8@0+ (1,2018) [2018|2273] "year" Vector__XXX
 SG_ TPrs_MntSet_Date m3 : 63|8@0+ (1,0) [0|255] "day" Vector__XXX
 SG_ TPrs_MntSet_Month m3 : 55|8@0+ (1,0) [0|255] "month" Vector__XXX
 SG_ TPrs_MntSet_Year m3 : 47|8@0+ (1,2018) [2018|2273] "year" Vector__XXX
 SG_ RR_TPrs_DispKG m3 : 39|8@0+ (0.1,0) [0|3.5] "kg/cm^2" Vector__XXX
 SG_ RL_TPrs_DispKG m3 : 31|8@0+ (0.1,0) [0|3.5] "kg/cm^2" Vector__XXX
 SG_ FR_TPrs_DispKG m3 : 23|8@0+ (0.1,0) [0|3.5] "kg/cm^2" Vector__XXX
 SG_ FL_TPrs_DispKG m3 : 15|8@0+ (0.1,0) [0|3.5] "kg/cm^2" Vector__XXX
 SG_ TPrs_RemRegDist m2 : 47|16@0+ (1,0) [0|65535] "km" Vector__XXX
 SG_ RR_TPrs_DispPS m2 : 39|8@0+ (1,0) [0|50] "PSI" Vector__XXX
 SG_ RL_TPrs_DispPS m2 : 31|8@0+ (1,0) [0|50] "PSI" Vector__XXX
 SG_ FR_TPrs_DispPS m2 : 23|8@0+ (1,0) [0|50] "PSI" Vector__XXX
 SG_ FL_TPrs_DispPS m2 : 15|8@0+ (1,0) [0|50] "PSI" Vector__XXX
 SG_ Sds_TotSD_Avl_D_Actl m1 : 63|8@0+ (0.1,0) [0|25.5] "" Vector__XXX
 SG_ MntSet_Dist m1 : 47|16@0+ (1,0) [0|65535] "" Vector__XXX
 SG_ RR_TPrs_DispBR m1 : 39|8@0+ (0.1,0) [0|3.5] "bar" Vector__XXX
 SG_ RL_TPrs_DispBR m1 : 31|8@0+ (0.1,0) [0|3.5] "bar" Vector__XXX
 SG_ FR_TPrs_DispBR m1 : 23|8@0+ (0.1,0) [0|3.5] "bar" Vector__XXX
 SG_ FL_TPrs_DispBR m1 : 15|8@0+ (0.1,0) [0|3.5] "bar" Vector__XXX
 SG_ MntTyre_AtFlg m0 : 58|1@0+ (1,0) [0|0] "" Vector__XXX
 SG_ RR_TPrs_DispKP m0 : 50|8@0+ (10,0) [0|350] "kPa" Vector__XXX
 SG_ RL_TPrs_DispKP m0 : 42|8@0+ (10,0) [0|350] "kPa" Vector__XXX
 SG_ FR_TPrs_DispKP m0 : 34|8@0+ (10,0) [0|350] "kPa" Vector__XXX
 SG_ FL_TPrs_DispKP m0 : 26|8@0+ (10,0) [0|350] "kPa" Vector__XXX
 SG_ ID_TPMS3_No_cnt m0 : 30|4@0+ (1,0) [0|15] "" Vector__XXX
 SG_ RR_TyrePressWarn m0 : 16|2@0+ (1,0) [0|0] "" Vector__XXX
 SG_ RL_TyrePressWarn m0 : 18|2@0+ (1,0) [0|0] "" Vector__XXX
 SG_ FR_TyrePressWarn m0 : 20|2@0+ (1,0) [0|0] "" Vector__XXX
 SG_ FL_TyrePressWarn m0 : 22|2@0+ (1,0) [0|0] "" Vector__XXX
 SG_ TPMS_SystemFlt m0 : 9|3@0+ (1,0) [0|0] "" Vector__XXX
 SG_ TPMS_Status m0 : 11|2@0+ (1,0) [0|0] ""  RCM
 SG_ RunflatWarnLamp_B_Rq m0 : 12|1@0+ (1,0) [0|0] "" Vector__XXX
 SG_ TPMSCtlLamp_D_Rq m0 : 15|2@0+ (1,0) [0|0] ""  RCM
 SG_ Data_Number M : 7|8@0+ (1,0) [0|0] ""  RCM

BO_ 1068 DCM_Message: 8 CGW
 SG_ TCU_ComFail_MsgType : 57|2@0+ (1,0) [0|0] "" Vector__XXX
 SG_ TCU_Service_Flag : 59|2@0+ (1,0) [0|0] "" Vector__XXX
 SG_ TCU_ComStatus_Notification : 61|2@0+ (1,0) [0|0] "" Vector__XXX
 SG_ TCU_SW_Update_Req : 62|1@0+ (1,0) [0|0] "" Vector__XXX
 SG_ VDT_BECM_ODR2_ResTCU : 48|2@0+ (1,0) [0|0] "" Vector__XXX
 SG_ Audio_mute_request_result : 50|2@0+ (1,0) [0|0] "" Vector__XXX
 SG_ Crash_output_relay_result : 51|1@0+ (1,0) [0|0] "" Vector__XXX
 SG_ Fialure_reason : 54|3@0+ (1,0) [0|0] "" Vector__XXX
 SG_ Voice_Communication_result : 55|1@0+ (1,0) [0|0] "" Vector__XXX
 SG_ Data_Transmission_result : 40|1@0+ (1,0) [0|0] "" Vector__XXX
 SG_ Call_Trigger_Type : 43|3@0+ (1,0) [0|0] "" Vector__XXX
 SG_ Recording_Trigger : 44|1@0+ (1,0) [0|0] "" Vector__XXX
 SG_ VDT_Recall_Counter : 32|4@0+ (1,0) [0|15] "" Vector__XXX
 SG_ VDT_Recall_Number : 16|16@0+ (1,0) [0|65535] "" Vector__XXX
 SG_ VDT_Recall_Req : 20|4@0+ (1,0) [0|0] "" Vector__XXX
 SG_ TCU_ComFail_B_Actl : 21|1@0+ (1,0) [0|0] ""  RCM
 SG_ VDT_BCM_Std3_ResTCU : 23|2@0+ (1,0) [0|0] "" Vector__XXX
 SG_ VDT_VCM_ODR2_ResTCU : 9|2@0+ (1,0) [0|0] "" Vector__XXX
 SG_ VDT_TCM_ODR2_ResTCU : 11|2@0+ (1,0) [0|0] "" Vector__XXX
 SG_ VDT_PCM_ODR2_ResTCU : 13|2@0+ (1,0) [0|0] "" Vector__XXX
 SG_ VDT_BCM_Std2_ResTCU : 15|2@0+ (1,0) [0|0] "" Vector__XXX
 SG_ VDT_VCM_ODR1_ResTCU : 1|2@0+ (1,0) [0|0] "" Vector__XXX
 SG_ VDT_PCM_ODR1_ResTCU : 3|2@0+ (1,0) [0|0] "" Vector__XXX
 SG_ VDT_BCM_Std1_ResTCU : 5|2@0+ (1,0) [0|0] "" Vector__XXX
 SG_ CallMute_B_Actl : 7|2@0+ (1,0) [0|0] ""  RCM

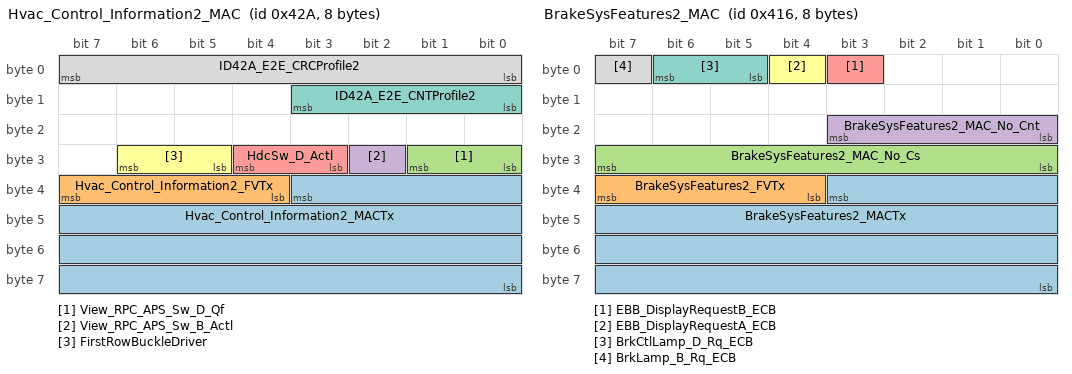
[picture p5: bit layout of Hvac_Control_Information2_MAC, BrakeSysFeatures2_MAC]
BO_ 1066 Hvac_Control_Information2_MAC: 8 CGW
 SG_ Hvac_Control_Information2_MACTx : 35|28@0+ (1,0) [0|268435455] ""  DSC,RCM
 SG_ Hvac_Control_Information2_FVTx : 39|4@0+ (1,0) [0|15] ""  DSC,RCM
 SG_ View_RPC_APS_Sw_D_Qf : 25|2@0+ (1,0) [0|0] "" Vector__XXX
 SG_ View_RPC_APS_Sw_B_Actl : 26|1@0+ (1,0) [0|0] "" Vector__XXX
 SG_ HdcSw_D_Actl : 28|2@0+ (1,0) [0|0] ""  DSC
 SG_ FirstRowBuckleDriver : 30|2@0+ (1,0) [0|0] ""  DSC,RCM
 SG_ ID42A_E2E_CNTProfile2 : 11|4@0+ (1,0) [0|15] ""  DSC
 SG_ ID42A_E2E_CRCProfile2 : 7|8@0+ (1,0) [0|255] ""  DSC

BO_ 1046 BrakeSysFeatures2_MAC: 8 ECB
 SG_ BrakeSysFeatures2_MACTx : 35|28@0+ (1,0) [0|268435455] ""  CGW
 SG_ BrakeSysFeatures2_FVTx : 39|4@0+ (1,0) [0|15] ""  CGW
 SG_ BrakeSysFeatures2_MAC_No_Cs : 31|8@0+ (1,0) [0|255] ""  CGW
 SG_ BrakeSysFeatures2_MAC_No_Cnt : 19|4@0+ (1,0) [0|15] ""  CGW
 SG_ EBB_DisplayRequestB_ECB : 3|1@0+ (1,0) [0|0] ""  CGW
 SG_ EBB_DisplayRequestA_ECB : 4|1@0+ (1,0) [0|0] ""  CGW
 SG_ BrkCtlLamp_D_Rq_ECB : 6|2@0+ (1,0) [0|0] ""  CGW
 SG_ BrkLamp_B_Rq_ECB : 7|1@0+ (1,0) [0|0] ""  CGW

BO_ 1045 BrakeSysFeatures: 8 DSC
 SG_ BrakeSysFeatures_No_Cs : 63|8@0+ (1,0) [0|255] ""  CGW,RCM
 SG_ BrakeSysFeatures_No_Cnt : 51|4@0+ (1,0) [0|15] ""  CGW,RCM
 SG_ Hdc_DisplayRequest_1 : 42|4@0+ (1,0) [0|0] ""  CGW
 SG_ EPB_TrqRequire : 43|1@0+ (1,0) [0|0] ""  CGW
 SG_ EPB_IGoff_Apply_Inhibit : 44|1@0+ (1,0) [0|0] ""  CGW
 SG_ RGN_StpLmp_Fail_Flag : 45|1@0+ (1,0) [0|0] ""  CGW
 SG_ LDA_B_Falt : 46|1@0+ (1,0) [0|0] ""  CGW
 SG_ BrkFluidLvl_D_Actl : 32|2@0+ (1,0) [0|0] ""  CGW
 SG_ DSC_OnOff_status : 33|1@0+ (1,0) [0|0] ""  CGW,RCM
 SG_ TCS_ENG_FAILD : 34|1@0+ (1,0) [0|0] ""  CGW,RCM
 SG_ TCS_BRK_FAILD : 35|1@0+ (1,0) [0|0] ""  CGW,RCM
 SG_ Dsc_B_Falt : 36|1@0+ (1,0) [0|0] ""  CGW,RCM
 SG_ EPB_Status : 39|3@0+ (1,0) [0|0] ""  CGW,RCM
 SG_ EPB_SwitchPosition : 25|2@0+ (1,0) [0|0] ""  CGW
 SG_ EPB_EnableExternalApply_TCM : 26|1@0+ (1,0) [0|0] ""  CGW
 SG_ EPB_EnableDecelRequest : 27|1@0+ (1,0) [0|0] ""  CGW
 SG_ EPB_EnableExternalApply_VCM : 28|1@0+ (1,0) [0|0] ""  CGW
 SG_ Hdc_ActLamp_D_Rq : 30|2@0+ (1,0) [0|0] ""  CGW
 SG_ Hdc_Trgt_Veh_V : 19|5@0+ (1,0) [2|30] "Unitless"  CGW
 SG_ OffSwitch_Info : 21|2@0+ (1,0) [0|0] ""  CGW,RCM
 SG_ AutoHoldStdbyLamp_D_Rq : 23|2@0+ (1,0) [0|0] ""  CGW
 SG_ EPB_IGoff_Apply_Buzzer : 8|1@0+ (1,0) [0|0] ""  CGW
 SG_ EBB_DisplayRequestB : 9|1@0+ (1,0) [0|0] ""  CGW
 SG_ EBB_DisplayRequestA : 10|1@0+ (1,0) [0|0] ""  CGW
 SG_ EPB_DisplayRequest5 : 11|1@0+ (1,0) [0|0] ""  CGW
 SG_ EPB_DisplayRequest4 : 12|1@0+ (1,0) [0|0] ""  CGW
 SG_ EPB_DisplayRequest3 : 13|1@0+ (1,0) [0|0] ""  CGW
 SG_ EPB_DisplayRequest2 : 14|1@0+ (1,0) [0|0] ""  CGW
 SG_ EPB_DisplayRequest1 : 15|1@0+ (1,0) [0|0] ""  CGW
 SG_ HydraulicHoldDis_B_Rq4 : 0|1@0+ (1,0) [0|0] ""  CGW
 SG_ HydraulicHoldDis_B_Rq3 : 1|1@0+ (1,0) [0|0] ""  CGW
 SG_ HydraulicHoldDis_B_Rq2 : 2|1@0+ (1,0) [0|0] ""  CGW
 SG_ HydraulicHoldDis_B_Rq1 : 3|1@0+ (1,0) [0|0] ""  CGW
 SG_ HydraulicHoldActLamp_D_Rq : 4|1@0+ (1,0) [0|0] ""  CGW
 SG_ DrvSlipCtlGuid_D_Rq : 5|1@0+ (1,0) [0|0] ""  CGW
 SG_ DrvAntiLckGuid_D_Rq : 6|1@0+ (1,0) [0|0] ""  CGW
 SG_ DrvEBDGuid_D_Rq : 7|1@0+ (1,0) [0|0] ""  CGW

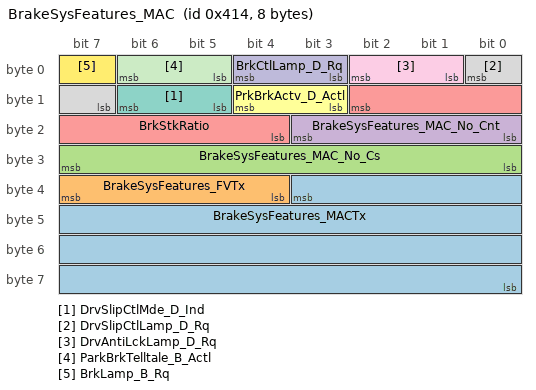
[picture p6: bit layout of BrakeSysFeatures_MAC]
BO_ 1044 BrakeSysFeatures_MAC: 8 DSC
 SG_ BrakeSysFeatures_MACTx : 35|28@0+ (1,0) [0|268435455] ""  CGW,RCM
 SG_ BrakeSysFeatures_FVTx : 39|4@0+ (1,0) [0|15] ""  CGW,RCM
 SG_ BrakeSysFeatures_MAC_No_Cs : 31|8@0+ (1,0) [0|255] ""  CGW,RCM
 SG_ BrakeSysFeatures_MAC_No_Cnt : 19|4@0+ (1,0) [0|15] ""  CGW,RCM
 SG_ BrkStkRatio : 10|7@0+ (1,0) [0|126] "%"  CGW,RCM
 SG_ PrkBrkActv_D_Actl : 12|2@0+ (1,0) [0|0] ""  CGW
 SG_ DrvSlipCtlMde_D_Ind : 14|2@0+ (1,0) [0|0] ""  CGW
 SG_ DrvSlipCtlLamp_D_Rq : 0|2@0+ (1,0) [0|0] ""  CGW
 SG_ DrvAntiLckLamp_D_Rq : 2|2@0+ (1,0) [0|0] ""  CGW
 SG_ BrkCtlLamp_D_Rq : 4|2@0+ (1,0) [0|0] ""  CGW
 SG_ ParkBrkTelltale_B_Actl : 6|2@0+ (1,0) [0|0] ""  CGW
 SG_ BrkLamp_B_Rq : 7|1@0+ (1,0) [0|0] ""  CGW,RCM

BO_ 1034 GCC_Config_Mgmt: 8 CGW
 SG_ Central_CRC m224 : 55|16@0+ (1,0) [0|65534] ""  DSC,ECB
 SG_ CDID_Total_Number m224 : 47|8@0+ (1,0) [0|254] ""  DSC,ECB
 SG_ Reserved_E0_2 m224 : 31|16@0+ (1,0) [0|65534] "" Vector__XXX
 SG_ Reserved_E0_1 m224 : 15|16@0+ (1,0) [0|65534] "" Vector__XXX
 SG_ Reserved_95_7 m149 : 63|8@0+ (1,0) [0|254] "" Vector__XXX
 SG_ Reserved_95_6 m149 : 55|8@0+ (1,0) [0|254] "" Vector__XXX
 SG_ Reserved_95_5 m149 : 47|8@0+ (1,0) [0|254] "" Vector__XXX
 SG_ Reserved_95_4 m149 : 39|8@0+ (1,0) [0|254] "" Vector__XXX
 SG_ Reserved_95_3 m149 : 31|8@0+ (1,0) [0|254] "" Vector__XXX
 SG_ Reserved_95_2 m149 : 23|8@0+ (1,0) [0|254] "" Vector__XXX
 SG_ Reserved_95_1 m149 : 15|8@0+ (1,0) [0|254] "" Vector__XXX
 SG_ Reserved_94_7 m148 : 63|8@0+ (1,0) [0|254] "" Vector__XXX
 SG_ Reserved_94_6 m148 : 55|8@0+ (1,0) [0|254] "" Vector__XXX
 SG_ Reserved_94_5 m148 : 47|8@0+ (1,0) [0|254] "" Vector__XXX
 SG_ Reserved_94_4 m148 : 39|8@0+ (1,0) [0|254] "" Vector__XXX
 SG_ Reserved_94_3 m148 : 31|8@0+ (1,0) [0|254] "" Vector__XXX
 SG_ Reserved_94_2 m148 : 23|8@0+ (1,0) [0|254] "" Vector__XXX
 SG_ Reserved_94_1 m148 : 15|8@0+ (1,0) [0|254] "" Vector__XXX
 SG_ Reserved_93_7 m147 : 63|8@0+ (1,0) [0|254] "" Vector__XXX
 SG_ Reserved_93_6 m147 : 55|8@0+ (1,0) [0|254] "" Vector__XXX
 SG_ Reserved_93_5 m147 : 47|8@0+ (1,0) [0|254] "" Vector__XXX
 SG_ Reserved_93_4 m147 : 39|8@0+ (1,0) [0|254] "" Vector__XXX
 SG_ Reserved_93_3 m147 : 31|8@0+ (1,0) [0|254] "" Vector__XXX
 SG_ Reserved_93_2 m147 : 23|8@0+ (1,0) [0|254] "" Vector__XXX
 SG_ Reserved_93_1 m147 : 15|8@0+ (1,0) [0|254] "" Vector__XXX
 SG_ Reserved_92_7 m146 : 63|8@0+ (1,0) [0|254] "" Vector__XXX
 SG_ Reserved_92_6 m146 : 55|8@0+ (1,0) [0|254] "" Vector__XXX
 SG_ Reserved_92_5 m146 : 47|8@0+ (1,0) [0|254] "" Vector__XXX
 SG_ Reserved_92_4 m146 : 39|8@0+ (1,0) [0|254] "" Vector__XXX
 SG_ Reserved_92_3 m146 : 31|8@0+ (1,0) [0|254] "" Vector__XXX
 SG_ Reserved_92_2 m146 : 23|8@0+ (1,0) [0|254] "" Vector__XXX
 SG_ Reserved_92_1 m146 : 15|8@0+ (1,0) [0|254] "" Vector__XXX
 SG_ Reserved_91_7 m145 : 63|8@0+ (1,0) [0|254] "" Vector__XXX
 SG_ Reserved_91_6 m145 : 55|8@0+ (1,0) [0|254] "" Vector__XXX
 SG_ Reserved_91_5 m145 : 47|8@0+ (1,0) [0|254] "" Vector__XXX
 SG_ Reserved_91_4 m145 : 39|8@0+ (1,0) [0|254] "" Vector__XXX
 SG_ Reserved_91_3 m145 : 31|8@0+ (1,0) [0|254] "" Vector__XXX
 SG_ Reserved_91_2 m145 : 23|8@0+ (1,0) [0|254] "" Vector__XXX
 SG_ Reserved_91_1 m145 : 15|8@0+ (1,0) [0|254] "" Vector__XXX
 SG_ Reserved_90_7 m144 : 63|8@0+ (1,0) [0|254] "" Vector__XXX
 SG_ Reserved_90_6 m144 : 55|8@0+ (1,0) [0|254] "" Vector__XXX
 SG_ Reserved_90_5 m144 : 47|8@0+ (1,0) [0|254] "" Vector__XXX
 SG_ Reserved_90_4 m144 : 39|8@0+ (1,0) [0|254] "" Vector__XXX
 SG_ Reserved_90_3 m144 : 31|8@0+ (1,0) [0|254] "" Vector__XXX
 SG_ Reserved_90_2 m144 : 23|8@0+ (1,0) [0|254] "" Vector__XXX
 SG_ Reserved_90_1 m144 : 15|8@0+ (1,0) [0|254] "" Vector__XXX
 SG_ Reserved_82_8 m130 : 63|8@0+ (1,0) [0|254] "" Vector__XXX
 SG_ Reserved_82_7 m130 : 55|8@0+ (1,0) [0|254] "" Vector__XXX
 SG_ ASE_SYSTEM m130 : 43|4@0+ (1,0) [0|14] "" Vector__XXX
 SG_ WIRELESS_CHARGE m130 : 47|4@0+ (1,0) [0|14] "" Vector__XXX
 SG_ FBUMPER_ASSY_TYPE m130 : 35|4@0+ (1,0) [0|14] "" Vector__XXX
 SG_ FBUMPER_SHAPE_TYPE m130 : 39|4@0+ (1,0) [0|14] "" Vector__XXX
 SG_ EMERGENCY_DRIVER_ASSIST m130 : 27|4@0+ (1,0) [0|14] ""  EPAS
 SG_ VMC_COMMUNICATION_TYPE m130 : 31|4@0+ (1,0) [0|14] "" Vector__XXX
 SG_ VMC_POSITION m130 : 17|2@0+ (1,0) [0|2] "" Vector__XXX
 SG_ Reserved_82_3 m130 : 19|2@0+ (1,0) [0|2] "" Vector__XXX
 SG_ INTERSECTION_BRAKE_SUPP m130 : 23|4@0+ (1,0) [0|14] "" Vector__XXX
 SG_ PERSONALIZE_SYSTEM m130 : 11|4@0+ (1,0) [0|14] "" Vector__XXX
 SG_ TAP m130 : 15|4@0+ (1,0) [0|14] "" Vector__XXX
 SG_ Reserved_80_5 m128 : 63|8@0+ (1,0) [0|254] "" Vector__XXX
 SG_ Number_Of_Cylinders m128 : 51|4@0+ (1,0) [0|14] "" Vector__XXX
 SG_ TURBO_ENGINE m128 : 55|4@0+ (1,0) [0|14] ""  DSC,ECB
 SG_ CYLINDER_DEACTIVATION m128 : 43|4@0+ (1,0) [0|14] ""  DSC,ECB
 SG_ UPGRADE_ENGINE m128 : 47|4@0+ (1,0) [0|14] ""  DSC,ECB
 SG_ ENGINE_TYPE m128 : 39|8@0+ (1,0) [0|254] ""  DSC,ECB
 SG_ Reserved_80_3 m128 : 31|8@0+ (1,0) [0|254] "" Vector__XXX
 SG_ Reserved_80_2 m128 : 19|4@0+ (1,0) [0|14] "" Vector__XXX
 SG_ AUX_POWER_UNIT m128 : 23|4@0+ (1,0) [0|14] "" Vector__XXX
 SG_ Reserved_80_1 m128 : 11|4@0+ (1,0) [0|14] "" Vector__XXX
 SG_ XEV_TYPE m128 : 15|4@0+ (1,0) [0|14] ""  DSC,EPAS,ECB
 SG_ Reserved_72_3 m114 : 55|16@0+ (1,0) [0|65535] "" Vector__XXX
 SG_ Reserved_72_4 m114 : 41|2@0+ (1,0) [0|2] "" Vector__XXX
 SG_ REMOTE_ENGINE_START_OPT m114 : 43|2@0+ (1,0) [0|2] "" Vector__XXX
 SG_ DOWN_LIGHT m114 : 45|2@0+ (1,0) [0|2] "" Vector__XXX
 SG_ KEYLESS_WINDOW_CONTROL m114 : 47|2@0+ (1,0) [0|2] "" Vector__XXX
 SG_ KEY_LESS_COMPT m114 : 33|2@0+ (1,0) [0|2] "" Vector__XXX
 SG_ SMART_KEYLESS m114 : 35|2@0+ (1,0) [0|2] "" Vector__XXX
 SG_ KEY_LESS_ENTRY m114 : 39|4@0+ (1,0) [0|14] "" Vector__XXX
 SG_ Reserved_72_2 m114 : 31|8@0+ (1,0) [0|254] "" Vector__XXX
 SG_ REMINDER_CONTROL_SPEC m114 : 23|8@0+ (1,0) [0|254] "" Vector__XXX
 SG_ SEAT_BELT_WARNING_SYSTEM m114 : 11|4@0+ (1,0) [0|14] "" Vector__XXX
 SG_ OCCUPANT_SENSING_SYSTEM m114 : 15|4@0+ (1,0) [0|14] "" Vector__XXX
 SG_ Reserved_70_4 m112 : 63|8@0+ (1,0) [0|254] "" Vector__XXX
 SG_ R_SEAT_NO2_TYPE m112 : 51|4@0+ (1,0) [0|14] "" Vector__XXX
 SG_ R_SEAT_NO1_TYPE m112 : 55|4@0+ (1,0) [0|14] "" Vector__XXX
 SG_ EXTERIOR_ALERT_TYPE m112 : 43|4@0+ (1,0) [0|14] "" Vector__XXX
 SG_ CPD_CONTROL_TYPE m112 : 47|4@0+ (1,0) [0|14] "" Vector__XXX
 SG_ Reserved_70_3 m112 : 33|2@0+ (1,0) [0|2] "" Vector__XXX
 SG_ F_SEAT_VENTILATION m112 : 35|2@0+ (1,0) [0|2] "" Vector__XXX
 SG_ F_SEAT_TYPE m112 : 39|4@0+ (1,0) [0|14] "" Vector__XXX
 SG_ Reserved_70_2 m112 : 25|2@0+ (1,0) [0|2] "" Vector__XXX
 SG_ R_SEAT_WARMER m112 : 27|2@0+ (1,0) [0|2] "" Vector__XXX
 SG_ F_SEAT_WARMER m112 : 31|4@0+ (1,0) [0|14] "" Vector__XXX
 SG_ Reserved_70_1 m112 : 19|4@0+ (1,0) [0|14] "" Vector__XXX
 SG_ F_SEAT_LIFT_MECHANISM m112 : 23|4@0+ (1,0) [0|14] "" Vector__XXX
 SG_ SEAT_MATERIAL m112 : 15|8@0+ (1,0) [0|254] "" Vector__XXX
 SG_ Reserved_63_1 m99 : 63|8@0+ (1,0) [0|254] "" Vector__XXX
 SG_ Vehicle_Height m99 : 47|16@0+ (1,0) [0|65534] "" Vector__XXX
 SG_ Vehicle_Width m99 : 31|16@0+ (1,0) [0|65534] "" Vector__XXX
 SG_ Vehicle_Length m99 : 15|16@0+ (1,0) [0|65534] "" Vector__XXX
 SG_ Reserved_62_2 m98 : 57|2@0+ (1,0) [0|2] "" Vector__XXX
 SG_ TOUCH_PANEL m98 : 59|2@0+ (1,0) [0|2] "" Vector__XXX
 SG_ DISPLAY_SIZE m98 : 63|4@0+ (1,0) [0|14] "" Vector__XXX
 SG_ HD_Radio m98 : 49|2@0+ (1,0) [0|2] "" Vector__XXX
 SG_ TELEMATICS_COM_UNIT m98 : 51|2@0+ (1,0) [0|2] "" Vector__XXX
 SG_ B_CALL m98 : 43|8@0+ (1,0) [0|254] "" Vector__XXX
 SG_ CMU_Spec m98 : 47|4@0+ (1,0) [0|14] "" Vector__XXX
 SG_ Number_Of_Seat_Rows m98 : 33|2@0+ (1,0) [0|2] "" Vector__XXX
 SG_ Tuner_AM_Range m98 : 35|2@0+ (1,0) [0|2] "" Vector__XXX
 SG_ Pandora m98 : 37|2@0+ (1,0) [0|2] "" Vector__XXX
 SG_ Mobile_911 m98 : 39|2@0+ (1,0) [0|2] "" Vector__XXX
 SG_ HDMI m98 : 25|2@0+ (1,0) [0|2] "" Vector__XXX
 SG_ LW m98 : 27|2@0+ (1,0) [0|2] "" Vector__XXX
 SG_ Limit_Of_DAB_Range m98 : 31|4@0+ (1,0) [0|14] "" Vector__XXX
 SG_ ELK_CUSTOMIZE_TYPE m98 : 17|2@0+ (1,0) [0|2] "" Vector__XXX
 SG_ Microphone m98 : 19|2@0+ (1,0) [0|2] "" Vector__XXX
 SG_ DAA_Default m98 : 21|2@0+ (1,0) [0|2] "" Vector__XXX
 SG_ Carplay m98 : 23|2@0+ (1,0) [0|2] "" Vector__XXX
 SG_ Android_Auto m98 : 9|2@0+ (1,0) [0|2] "" Vector__XXX
 SG_ Wi_Fi_Frequency m98 : 11|2@0+ (1,0) [0|2] "" Vector__XXX
 SG_ Commander_Touchpad m98 : 13|2@0+ (1,0) [0|2] "" Vector__XXX
 SG_ TPEG m98 : 15|2@0+ (1,0) [0|2] "" Vector__XXX
 SG_ Reserved_60_1 m96 : 47|24@0+ (1,0) [0|16777214] "" Vector__XXX
 SG_ EMERGENCY_CALL m96 : 35|4@0+ (1,0) [0|14] "" Vector__XXX
 SG_ SATELITE_SPEC m96 : 39|4@0+ (1,0) [0|14] "" Vector__XXX
 SG_ NAVI_MAP_DATA m96 : 27|4@0+ (1,0) [0|14] "" Vector__XXX
 SG_ CD_Ripping m96 : 29|2@0+ (1,0) [0|2] "" Vector__XXX
 SG_ TV_TUNER m96 : 31|2@0+ (1,0) [0|2] "" Vector__XXX
 SG_ SPEAKER_TYPE m96 : 19|4@0+ (1,0) [0|14] "" Vector__XXX
 SG_ DVD m96 : 21|2@0+ (1,0) [0|2] "" Vector__XXX
 SG_ CD m96 : 23|2@0+ (1,0) [0|2] "" Vector__XXX
 SG_ FREQUENCY m96 : 11|4@0+ (1,0) [0|14] "" Vector__XXX
 SG_ RDS m96 : 13|2@0+ (1,0) [0|2] "" Vector__XXX
 SG_ DAB m96 : 15|2@0+ (1,0) [0|2] "" Vector__XXX
 SG_ Reserved_52_6 m82 : 63|8@0+ (1,0) [0|254] "" Vector__XXX
 SG_ AT_SHIFT_SW m82 : 51|4@0+ (1,0) [0|14] "" Vector__XXX
 SG_ ELECTRIC_SHIFT m82 : 55|4@0+ (1,0) [0|14] "" Vector__XXX
 SG_ Reserved_52_5 m82 : 41|2@0+ (1,0) [0|2] "" Vector__XXX
 SG_ STG_WHEEL_WARMER m82 : 43|2@0+ (1,0) [0|2] "" Vector__XXX
 SG_ TILT_STG m82 : 47|4@0+ (1,0) [0|14] "" Vector__XXX
 SG_ Reserved_52_4 m82 : 39|8@0+ (1,0) [0|254] "" Vector__XXX
 SG_ DRIVE_SELECTION_MODE m82 : 27|4@0+ (1,0) [0|14] "" Vector__XXX
 SG_ Reserved_52_3 m82 : 29|2@0+ (1,0) [0|2] "" Vector__XXX
 SG_ DRIVE_SELECTION m82 : 31|2@0+ (1,0) [0|2] "" Vector__XXX
 SG_ I_DM m82 : 17|2@0+ (1,0) [0|2] "" Vector__XXX
 SG_ Reserved_52_2 m82 : 19|2@0+ (1,0) [0|2] "" Vector__XXX
 SG_ OVER_HEAD_CONSOLE m82 : 23|4@0+ (1,0) [0|14] "" Vector__XXX
 SG_ AT_INTERLOCK_UNLOCK_SYS m82 : 11|4@0+ (1,0) [0|14] "" Vector__XXX
 SG_ BURGLAR_ALARM_SYSTEM m82 : 15|4@0+ (1,0) [0|14] "" Vector__XXX
 SG_ Reserved_50_3 m80 : 47|24@0+ (1,0) [0|16777214] "" Vector__XXX
 SG_ TSR_GSR_TYPE m80 : 35|4@0+ (1,0) [0|14] "" Vector__XXX
 SG_ SPEED_METER m80 : 39|4@0+ (1,0) [0|14] "" Vector__XXX
 SG_ FUEL_CONSUMPTION_UNIT m80 : 27|4@0+ (1,0) [0|14] "" Vector__XXX
 SG_ TRIP_COMPUTER m80 : 31|4@0+ (1,0) [0|14] "" Vector__XXX
 SG_ HEAD_UP_DISPLAY m80 : 17|2@0+ (1,0) [0|2] "" Vector__XXX
 SG_ WARNING_BUZZER_120KMH m80 : 19|2@0+ (1,0) [0|2] "" Vector__XXX
 SG_ TURN_SIGNAL_SWITCH m80 : 21|2@0+ (1,0) [0|2] "" Vector__XXX
 SG_ Reserved_50_1 m80 : 23|2@0+ (1,0) [0|2] "" Vector__XXX
 SG_ MULTI_DOT_DISPLAY m80 : 9|2@0+ (1,0) [0|2] "" Vector__XXX
 SG_ Reserved_50_4 m80 : 11|2@0+ (1,0) [0|2] "" Vector__XXX
 SG_ IND_STD_OF_SPEED_METER m80 : 15|4@0+ (1,0) [0|14] "" Vector__XXX
 SG_ Reserved_40_4 m64 : 55|16@0+ (1,0) [0|65535] "" Vector__XXX
 SG_ F_EX_MIRROR_AUTO_FOLD m64 : 41|2@0+ (1,0) [0|2] "" Vector__XXX
 SG_ F_EXT_MIRROR_ADJ_MEMORY m64 : 43|2@0+ (1,0) [0|2] "" Vector__XXX
 SG_ F_EXT_MIRROR_HEATER m64 : 45|2@0+ (1,0) [0|2] "" Vector__XXX
 SG_ F_EX_MIRROR_POWER_FOLD m64 : 47|2@0+ (1,0) [0|2] "" Vector__XXX
 SG_ Reserved_40_3 m64 : 19|20@0+ (1,0) [0|1048574] "" Vector__XXX
 SG_ ONE_TOUCH_SYSTEM m64 : 23|4@0+ (1,0) [0|14] "" Vector__XXX
 SG_ Reserved_40_2 m64 : 9|2@0+ (1,0) [0|2] "" Vector__XXX
 SG_ WASHER_LEVEL_LAMP m64 : 11|2@0+ (1,0) [0|2] "" Vector__XXX
 SG_ F_WIPER_INTERMITTENT m64 : 15|4@0+ (1,0) [0|14] "" Vector__XXX
 SG_ Reserved_30_6 m48 : 63|8@0+ (1,0) [0|254] "" Vector__XXX
 SG_ AUTO_DOOR_LOCK m48 : 51|4@0+ (1,0) [0|14] "" Vector__XXX
 SG_ Reserved_30_5 m48 : 53|2@0+ (1,0) [0|2] "" Vector__XXX
 SG_ SUPER_LOCK_SYSTEM m48 : 55|2@0+ (1,0) [0|2] "" Vector__XXX
 SG_ POWER_DOOR_LOCK_SW m48 : 43|4@0+ (1,0) [0|14] "" Vector__XXX
 SG_ POWER_DOOR_LOCK m48 : 47|4@0+ (1,0) [0|14] "" Vector__XXX
 SG_ Reserved_30_4 m48 : 39|8@0+ (1,0) [0|254] "" Vector__XXX
 SG_ Reserved_30_3 m48 : 29|6@0+ (1,0) [0|62] "" Vector__XXX
 SG_ POWER_BACK_DOOR m48 : 31|2@0+ (1,0) [0|2] "" Vector__XXX
 SG_ Reserved_30_2 m48 : 23|8@0+ (1,0) [0|254] "" Vector__XXX
 SG_ Reserved_30_1 m48 : 11|4@0+ (1,0) [0|14] "" Vector__XXX
 SG_ TRUNK_LID_OPENER m48 : 15|4@0+ (1,0) [0|14] "" Vector__XXX
 SG_ Reserved_25_4 m37 : 47|24@0+ (1,0) [0|16777214] "" Vector__XXX
 SG_ DEFAULT_ONE_TOUCH_TURN m37 : 33|2@0+ (1,0) [0|2] "" Vector__XXX
 SG_ ESS m37 : 35|2@0+ (1,0) [0|2] "" Vector__XXX
 SG_ R_FOG_LAMP m37 : 37|2@0+ (1,0) [0|2] "" Vector__XXX
 SG_ F_FOG_LAMP m37 : 39|2@0+ (1,0) [0|2] "" Vector__XXX
 SG_ Reserved_25_3 m37 : 27|4@0+ (1,0) [0|14] "" Vector__XXX
 SG_ PASSIVE_COLLISION_SIGNAL m37 : 31|4@0+ (1,0) [0|14] ""  DSC,ECB
 SG_ F_AND_R_SIDE_MARKER_US m37 : 17|2@0+ (1,0) [0|2] "" Vector__XXX
 SG_ AUTO_HEAD_LAMP_ON_OFF m37 : 19|2@0+ (1,0) [0|2] "" Vector__XXX
 SG_ RUNNING_LAMP_CUSTOMIZE m37 : 23|4@0+ (1,0) [0|14] "" Vector__XXX
 SG_ F_COMBI_SIGNATURE_ILLUMI m37 : 9|2@0+ (1,0) [0|2] "" Vector__XXX
 SG_ HEAD_LAMP_CLEANER m37 : 11|2@0+ (1,0) [0|2] "" Vector__XXX
 SG_ Headlamp_Control m37 : 15|4@0+ (1,0) [0|14] "" Vector__XXX
 SG_ Reserved_20_3 m32 : 55|16@0+ (1,0) [0|65535] "" Vector__XXX
 SG_ AC_Refrigerant_Gas m32 : 43|4@0+ (1,0) [0|14] "" Vector__XXX
 SG_ AC_Compressor m32 : 47|4@0+ (1,0) [0|14] "" Vector__XXX
 SG_ Reserved_20_2 m32 : 31|16@0+ (1,0) [0|65535] "" Vector__XXX
 SG_ Reserved_20_1 m32 : 17|2@0+ (1,0) [0|2] "" Vector__XXX
 SG_ PreAirCon_OperatingTime m32 : 21|4@0+ (1,0) [0|14] "" Vector__XXX
 SG_ R_VENT_COOLER m32 : 23|2@0+ (1,0) [0|2] "" Vector__XXX
 SG_ HUMIDITY_SENSOR m32 : 9|2@0+ (1,0) [0|2] "" Vector__XXX
 SG_ PTC_HEATER m32 : 11|2@0+ (1,0) [0|2] "" Vector__XXX
 SG_ F_AIR_CONDITIONER m32 : 15|4@0+ (1,0) [0|14] "" Vector__XXX
 SG_ Reserved_16_3 m22 : 47|24@0+ (1,0) [0|16777214] "" Vector__XXX
 SG_ Reserved_16_2 m22 : 35|4@0+ (1,0) [0|14] "" Vector__XXX
 SG_ OCCUPANT_MONITOR_SYSTEM m22 : 37|2@0+ (1,0) [0|2] "" Vector__XXX
 SG_ FRONT_SIDE_RADAR m22 : 39|2@0+ (1,0) [0|2] "" Vector__XXX
 SG_ TJA_TYPE m22 : 27|4@0+ (1,0) [0|14] ""  EPAS
 SG_ VIEW_MONITOR_CAMERA m22 : 31|4@0+ (1,0) [0|14] "" Vector__XXX
 SG_ FRONT_REAR_SIDE_SONAR m22 : 19|4@0+ (1,0) [0|14] "" Vector__XXX
 SG_ DRIVER_MONITOR m22 : 21|2@0+ (1,0) [0|2] "" Vector__XXX
 SG_ FRONT_CROSS_TRAFFIC_ALERT m22 : 23|2@0+ (1,0) [0|2] "" Vector__XXX
 SG_ INTERSECTION_BRAKE_TYPE m22 : 11|4@0+ (1,0) [0|14] "" Vector__XXX
 SG_ BLIND_SPOT_PREVENTION m22 : 13|2@0+ (1,0) [0|2] ""  EPAS
 SG_ Reserved_16_1 m22 : 15|2@0+ (1,0) [0|2] "" Vector__XXX
 SG_ Reserved_15_3 m21 : 47|24@0+ (1,0) [0|16777214] "" Vector__XXX
 SG_ SBS_VRU_TYPE m21 : 35|4@0+ (1,0) [0|14] "" Vector__XXX
 SG_ ADAS_REGULATION_TYPE m21 : 39|4@0+ (1,0) [0|14] "" Vector__XXX
 SG_ REMOTE_PARKING m21 : 25|2@0+ (1,0) [0|2] ""  EPAS
 SG_ AUTO_PARKING m21 : 27|2@0+ (1,0) [0|2] ""  EPAS
 SG_ ACCELERATION_RESTRAINT m21 : 31|4@0+ (1,0) [0|14] "" Vector__XXX
 SG_ REAR_SONAR m21 : 19|4@0+ (1,0) [0|14] "" Vector__XXX
 SG_ FRONT_SONAR m21 : 23|4@0+ (1,0) [0|14] "" Vector__XXX
 SG_ PARKING_SENSOR m21 : 11|4@0+ (1,0) [0|14] "" Vector__XXX
 SG_ REAR_DIRECTION_BASE_SAFETY m21 : 15|4@0+ (1,0) [0|14] "" Vector__XXX
 SG_ Reserved_14_2 m20 : 59|4@0+ (1,0) [0|14] "" Vector__XXX
 SG_ SBS_TARGET_TYPE m20 : 63|4@0+ (1,0) [0|14] "" Vector__XXX
 SG_ IACC_TYPE m20 : 51|4@0+ (1,0) [0|14] "" Vector__XXX
 SG_ HEAD_ON m20 : 55|4@0+ (1,0) [0|14] "" Vector__XXX
 SG_ LAS_TYPE m20 : 43|4@0+ (1,0) [0|14] "" Vector__XXX
 SG_ MRCC_TYPE m20 : 47|4@0+ (1,0) [0|14] "" Vector__XXX
 SG_ Reserved_14_1 m20 : 33|2@0+ (1,0) [0|2] "" Vector__XXX
 SG_ BLIND_SPOT_MONITORING m20 : 35|2@0+ (1,0) [0|2] "" Vector__XXX
 SG_ REAR_SIDE_RADAR m20 : 37|2@0+ (1,0) [0|2] "" Vector__XXX
 SG_ FRONT_RADAR m20 : 39|2@0+ (1,0) [0|2] "" Vector__XXX
 SG_ ADJUSTABLE_SPEED_LIMITER m20 : 27|4@0+ (1,0) [0|14] "" Vector__XXX
 SG_ AUTO_CRUISER m20 : 31|4@0+ (1,0) [0|14] "" Vector__XXX
 SG_ DAS_TYPE m20 : 19|4@0+ (1,0) [0|14] "" Vector__XXX
 SG_ DRIVER_ATTENTION_ALERT m20 : 21|2@0+ (1,0) [0|2] "" Vector__XXX
 SG_ TRAFFIC_SIGN_RECOGNITION m20 : 23|2@0+ (1,0) [0|2] "" Vector__XXX
 SG_ FRONT_DIRECTION_BASE_SAFETY m20 : 11|4@0+ (1,0) [0|14] ""  DSC,EPAS,ECB
 SG_ HIGH_BEAM_CONTROL m20 : 13|2@0+ (1,0) [0|2] "" Vector__XXX
 SG_ FORWARD_SENSING_CAMERA m20 : 15|2@0+ (1,0) [0|2] "" Vector__XXX
 SG_ Reserved_13_3 m19 : 47|24@0+ (1,0) [0|16777214] "" Vector__XXX
 SG_ Reserved_13_2 m19 : 39|8@0+ (1,0) [0|254] "" Vector__XXX
 SG_ Reserved_13_1 m19 : 27|4@0+ (1,0) [0|14] "" Vector__XXX
 SG_ F_TIRE_SIZE m19 : 31|4@0+ (1,0) [0|14] "" Vector__XXX
 SG_ Tire_Circumference m19 : 15|16@0+ (1,0) [0|65535] ""  DSC,ECB
 SG_ Reserved_12_3 m18 : 55|16@0+ (1,0) [0|65535] "" Vector__XXX
 SG_ EPS_Assist_Map m18 : 47|8@0+ (1,0) [0|254] ""  EPAS
 SG_ Reserved_12_2 m18 : 31|16@0+ (1,0) [0|65535] "" Vector__XXX
 SG_ Booster_Failure_Support m18 : 17|2@0+ (1,0) [0|2] ""  DSC,ECB
 SG_ DYC m18 : 19|2@0+ (1,0) [0|2] ""  DSC,ECB
 SG_ Brake_Pad_Material m18 : 23|4@0+ (1,0) [0|14] ""  DSC,ECB
 SG_ Rear_Brake_Size m18 : 11|4@0+ (1,0) [0|14] ""  DSC,ECB
 SG_ Front_Brake_Size m18 : 15|4@0+ (1,0) [0|14] ""  DSC,ECB
 SG_ Reserved_11_4 m17 : 55|16@0+ (1,0) [0|65535] "" Vector__XXX
 SG_ Reserved_11_3 m17 : 43|4@0+ (1,0) [0|14] "" Vector__XXX
 SG_ TIRE_PRESSURE_MONITOR_S m17 : 47|4@0+ (1,0) [0|14] "" Vector__XXX
 SG_ Reserved_11_2 m17 : 31|16@0+ (1,0) [0|65535] "" Vector__XXX
 SG_ BATTERY_HEATER m17 : 19|4@0+ (1,0) [0|14] "" Vector__XXX
 SG_ Reserved_11_1 m17 : 21|2@0+ (1,0) [0|2] "" Vector__XXX
 SG_ TSA m17 : 23|2@0+ (1,0) [0|2] "" Vector__XXX
 SG_ AUTO_HOLD m17 : 9|2@0+ (1,0) [0|2] ""  DSC,ECB
 SG_ EPB m17 : 11|2@0+ (1,0) [0|2] "" Vector__XXX
 SG_ Brake_Control m17 : 15|4@0+ (1,0) [0|14] "" Vector__XXX
 SG_ Reserved_10_2 m16 : 43|20@0+ (1,0) [0|1048574] "" Vector__XXX
 SG_ CLOSED_FUEL_TANK_SYSTEM m16 : 47|4@0+ (1,0) [0|14] "" Vector__XXX
 SG_ BEV_MAINTENANCE_LIMIT m16 : 39|8@0+ (1,0) [0|254] "" Vector__XXX
 SG_ Reserved_10_1 m16 : 19|12@0+ (1,0) [0|4094] "" Vector__XXX
 SG_ E_OIL_MAINTENANCE_LIMIT m16 : 23|4@0+ (1,0) [0|14] "" Vector__XXX
 SG_ REGENERATION_TYPE m16 : 11|4@0+ (1,0) [0|14] "" Vector__XXX
 SG_ I_STOP_TYPE m16 : 15|4@0+ (1,0) [0|14] ""  DSC,ECB
 SG_ Reserved_06_2 m6 : 55|16@0+ (1,0) [0|65535] "" Vector__XXX
 SG_ DEVELOPMENT_FUEL m6 : 43|4@0+ (1,0) [0|14] "" Vector__XXX
 SG_ PLANT m6 : 47|4@0+ (1,0) [0|14] "" Vector__XXX
 SG_ Reserved_06_1 m6 : 33|2@0+ (1,0) [0|2] "" Vector__XXX
 SG_ Steering_Position m6 : 35|2@0+ (1,0) [0|2] ""  RCM
 SG_ ROOF m6 : 39|4@0+ (1,0) [0|14] "" Vector__XXX
 SG_ TRANSMISSION m6 : 25|2@0+ (1,0) [0|2] ""  DSC,ECB
 SG_ DRIVE m6 : 27|2@0+ (1,0) [0|2] ""  DSC,ECB
 SG_ ENGINE m6 : 31|4@0+ (1,0) [0|14] ""  DSC,ECB
 SG_ BODY m6 : 19|4@0+ (1,0) [0|14] "" Vector__XXX
 SG_ BRAND m6 : 23|4@0+ (1,0) [0|14] "" Vector__XXX
 SG_ MARKET m6 : 15|8@0+ (1,0) [0|254] "" Vector__XXX
 SG_ Reserved_05_1 m5 : 47|24@0+ (1,0) [0|16777214] "" Vector__XXX
 SG_ Project_Code_4th m5 : 39|8@0+ (1,0) [0|254] "" Vector__XXX
 SG_ Project_Code_3rd m5 : 31|8@0+ (1,0) [0|254] "" Vector__XXX
 SG_ Project_Code_2nd m5 : 23|8@0+ (1,0) [0|254] "" Vector__XXX
 SG_ Project_Code_1st m5 : 15|8@0+ (1,0) [0|254] "" Vector__XXX
 SG_ Outer_Color_3 m4 : 63|8@0+ (1,0) [0|254] "" Vector__XXX
 SG_ Outer_Color_2 m4 : 55|8@0+ (1,0) [0|254] "" Vector__XXX
 SG_ Outer_Color_1 m4 : 47|8@0+ (1,0) [0|254] "" Vector__XXX
 SG_ Unit_Serial_Number m4 : 39|8@0+ (1,0) [0|254] "" Vector__XXX
 SG_ Unit_Destination m4 : 31|8@0+ (1,0) [0|254] ""  DSC,ECB
 SG_ Unit_Series m4 : 23|8@0+ (1,0) [0|254] "" Vector__XXX
 SG_ Unit_Car_Line m4 : 15|8@0+ (1,0) [0|254] "" Vector__XXX
 SG_ VIN_Character_21 m3 : 63|8@0+ (1,0) [0|254] "" Vector__XXX
 SG_ VIN_Character_20 m3 : 55|8@0+ (1,0) [0|254] "" Vector__XXX
 SG_ VIN_Character_19 m3 : 47|8@0+ (1,0) [0|254] "" Vector__XXX
 SG_ VIN_Character_18 m3 : 39|8@0+ (1,0) [0|254] "" Vector__XXX
 SG_ VIN_Character_17 m3 : 31|8@0+ (1,0) [0|254] "" Vector__XXX
 SG_ VIN_Character_16 m3 : 23|8@0+ (1,0) [0|254] "" Vector__XXX
 SG_ VIN_Character_15 m3 : 15|8@0+ (1,0) [0|254] "" Vector__XXX
 SG_ VIN_Character_14 m2 : 63|8@0+ (1,0) [0|254] "" Vector__XXX
 SG_ VIN_Character_13 m2 : 55|8@0+ (1,0) [0|254] "" Vector__XXX
 SG_ VIN_Character_12 m2 : 47|8@0+ (1,0) [0|254] "" Vector__XXX
 SG_ VIN_Character_11 m2 : 39|8@0+ (1,0) [0|254] "" Vector__XXX
 SG_ VIN_Character_10 m2 : 31|8@0+ (1,0) [0|254] "" Vector__XXX
 SG_ VIN_Character_09 m2 : 23|8@0+ (1,0) [0|254] "" Vector__XXX
 SG_ VIN_Character_08 m2 : 15|8@0+ (1,0) [0|254] "" Vector__XXX
 SG_ VIN_Character_07 m1 : 63|8@0+ (1,0) [0|254] "" Vector__XXX
 SG_ VIN_Character_06 m1 : 55|8@0+ (1,0) [0|254] "" Vector__XXX
 SG_ VIN_Character_05 m1 : 47|8@0+ (1,0) [0|254] "" Vector__XXX
 SG_ VIN_Character_04 m1 : 39|8@0+ (1,0) [0|254] "" Vector__XXX
 SG_ VIN_Character_03 m1 : 31|8@0+ (1,0) [0|254] "" Vector__XXX
 SG_ VIN_Character_02 m1 : 23|8@0+ (1,0) [0|254] "" Vector__XXX
 SG_ VIN_Character_01 m1 : 15|8@0+ (1,0) [0|254] "" Vector__XXX
 SG_ EngRunTimer m243 : 55|16@0+ (1,0) [0|65535] ""  DSC,RCM,EPAS,ECB
 SG_ BrakePedal m243 : 47|8@0+ (1,0) [0|255] ""  DSC,RCM,EPAS,ECB
 SG_ Reserved_F3_1 m243 : 39|8@0+ (1,0) [0|255] "" Vector__XXX
 SG_ VehicleSpeed_signal m243 : 31|8@0+ (1,0) [0|255] ""  DSC,RCM,EPAS,ECB
 SG_ EngineRotationSpeed m243 : 15|16@0+ (1,0) [0|65535] ""  DSC,RCM,EPAS,ECB
 SG_ EngClnt m242 : 63|8@0+ (1,0) [0|255] ""  DSC,RCM,EPAS,ECB
 SG_ Reserved_F2_2 m242 : 55|8@0+ (1,0) [0|255] "" Vector__XXX
 SG_ AccelPedalPosition m242 : 47|8@0+ (1,0) [0|255] ""  DSC,RCM,EPAS,ECB
 SG_ Reserved_F2_1 m242 : 39|8@0+ (1,0) [0|255] "" Vector__XXX
 SG_ SOC m242 : 31|8@0+ (1,0) [0|255] ""  DSC,RCM,EPAS,ECB
 SG_ IG_OnTimer m242 : 15|16@0+ (1,0) [0|65535] ""  DSC,RCM,EPAS,ECB
 SG_ ShiftPosition m241 : 63|8@0+ (1,0) [0|255] ""  DSC,RCM,EPAS,ECB
 SG_ PwMdeExtern_D_Actl m241 : 55|8@0+ (1,0) [0|255] ""  DSC,RCM,EPAS,ECB
 SG_ Out_car_temperature m241 : 47|8@0+ (1,0) [0|255] ""  DSC,RCM,EPAS,ECB
 SG_ MECU_supply_voltage m241 : 39|8@0+ (1,0) [0|255] ""  DSC,RCM,EPAS,ECB
 SG_ Total_Distance m241 : 15|24@0+ (1,0) [0|16777215] ""  DSC,RCM,EPAS,ECB
 SG_ SOC2_SS m240 : 63|8@0+ (1,0) [0|255] ""  DSC,RCM,EPAS,ECB
 SG_ MotorRPM_SS m240 : 47|16@0+ (1,0) [0|65535] ""  DSC,RCM,EPAS,ECB
 SG_ Global_Real_Time m240 : 15|32@0+ (1,0) [0|4294967295] ""  DSC,RCM,EPAS,ECB
 SG_ GCC_CfgParam M : 7|8@0+ (1,0) [0|0] ""  DSC,RCM,EPAS,ECB

BA_DEF_  "BusType" STRING ;
BA_DEF_ BU_  "DiagNode" ENUM  "No","Yes";
BA_DEF_ BO_  "SCP_FreshnessValueTxLength" INT 0 512;
BA_DEF_ BO_  "SCP_FreshnessValueLength" INT 0 512;
BA_DEF_ BO_  "SCP_DataId" INT 0 65535;
BA_DEF_ BO_  "SCP_AuthInfoTxLength" INT 0 512;
BA_DEF_ BO_  "SC_Message" ENUM  "No","Yes";
BA_DEF_ BO_  "CANFD_BRS" ENUM  "0","1";
BA_DEF_ BO_  "VFrameFormat" ENUM  "StandardCAN","ExtendedCAN","reserved","reserved","reserved","reserved","reserved","reserved","reserved","reserved","reserved","reserved","reserved","reserved","StandardCAN_FD","ExtendedCAN_FD";
BA_DEF_ BO_  "DiagRequest" ENUM  "No","Yes";
BA_DEF_ BO_  "DiagResponse" ENUM  "No","Yes";
BA_DEF_ BO_  "DiagState" ENUM  "No","Yes";
BA_DEF_ BO_  "DiagConnection" INT 0 65535;
BA_DEF_ BU_  "EOL_SB_Flash" ENUM  "No","Yes";
BA_DEF_ BU_  "GatewayECU" ENUM  "No","Yes";
BA_DEF_ BO_  "GenMsgCycleTime" INT 0 10000;
BA_DEF_ BO_  "GenMsgCycleTimeFast" INT 0 100000;
BA_DEF_ BO_  "GenMsgDelayTime" INT 0 1000;
BA_DEF_ BO_  "GenMsgILSupport" ENUM  "No","Yes";
BA_DEF_ BO_  "GenMsgNrOfRepetition" INT 0 100;
BA_DEF_ BO_  "GenMsgSendType" ENUM  "FixedPeriodic","Event","EnabledPeriodic","NotUsed","NotUsed","EventPeriodic","NotUsed","NotUsed","NoMsgSendType";
BA_DEF_ SG_  "GenSigSendType" ENUM  "Cyclic","OnWrite","OnWriteWithRepetition","OnChange","OnChangeWithRepetition","IfActive","IfActiveWithRepetition","NoSigSendType";
BA_DEF_ SG_  "GenSigStartValue" FLOAT 0 100000000000;
BA_DEF_ SG_  "GenSigTimeoutTime_RCM" INT 0 100000;
BA_DEF_ SG_  "GenSigTimeoutTime_FSC" INT 0 100000;
BA_DEF_ SG_  "GenSigTimeoutTime_EPAS" INT 0 100000;
BA_DEF_ SG_  "GenSigTimeoutTime_ECB" INT 0 100000;
BA_DEF_ SG_  "GenSigTimeoutTime_DSC" INT 0 100000;
BA_DEF_ SG_  "GenSigTimeoutTime_CGW" INT 0 100000;
BA_DEF_ BU_  "ILUsed" ENUM  "No","Yes";
BA_DEF_  "Manufacturer" STRING ;
BA_DEF_ BO_  "NetworkInitialization" ENUM  "No","Yes";
BA_DEF_ BU_  "NetworkType" ENUM  "Powertrain","Bodybus","Infotainment";
BA_DEF_  "NmBaseAddress" HEX 0 1280;
BA_DEF_ BU_  "NmCAN" INT 1 2;
BA_DEF_  "NmMessageCount" INT 0 128;
BA_DEF_  "NmType" STRING ;
BA_DEF_ BU_  "NodeLayerModules" STRING ;
BA_DEF_ BU_  "PowerType" ENUM  "Ignition Switched","Secondary Switched","Sleep";
BA_DEF_ BU_  "TransceiverType" ENUM  "Unknown","TJA1050","TJA1040","TJA1041","82C250","TLE6250","MC33989","CS251";
BA_DEF_ BU_  "Version_Ccl" STRING ;
BA_DEF_ BU_  "Version_Diag_CANdesc" STRING ;
BA_DEF_ BU_  "Version_DrvCan" STRING ;
BA_DEF_ BU_  "Version_GW_ILGateway" STRING ;
BA_DEF_ BU_  "Version_IL_NI_Ford" STRING ;
BA_DEF_ BU_  "Version_IL_Vector" STRING ;
BA_DEF_ BU_  "Version_NM_DirOsek" STRING ;
BA_DEF_ BU_  "Version_NM_Junior" STRING ;
BA_DEF_ BU_  "Version_Tp_Iso15765" STRING ;
BA_DEF_  "VersionDay" INT 0 31;
BA_DEF_  "VersionMonth" INT 0 12;
BA_DEF_  "VersionNumber" INT 0 100;
BA_DEF_  "VersionYear" INT 2000 2100;
BA_DEF_ SG_  "GenSigEnvVarType" ENUM  "int","float","undef";
BA_DEF_ BU_  "NmAsrNode" ENUM  "No","Yes";
BA_DEF_  "NmAsrTimeoutTime" INT 1 65535;
BA_DEF_  "NmAsrWaitBusSleepTime" INT 0 65535;
BA_DEF_  "NmAsrRepeatMessageTime" INT 0 65535;
BA_DEF_ BO_  "NmAsrMessage" ENUM  "No","Yes";
BA_DEF_  "NmAsrMessageCount" INT 1 256;
BA_DEF_  "NmAsrBaseAddress" HEX 0 2047;
BA_DEF_ BU_  "NmAsrNodeIdentifier" HEX 0 255;
BA_DEF_  "NmAsrCanMsgCycleTime" INT 1 65535;
BA_DEF_ BU_  "NmAsrCanMsgReducedTime" INT 1 65535;
BA_DEF_ BO_  "GenMsgTxConditionIg1On" ENUM  "No","Yes";
BA_DEF_ BO_  "GenMsgTxConditionPlusBOn" ENUM  "No","Yes";
BA_DEF_ SG_  "GenSigSuprvResp_CGW" ENUM  "None","Notify","Substitute","NotifySubstitute";
BA_DEF_ SG_  "GenSigSuprvRespSubValue_CGW" INT 0 10000000000;
BA_DEF_ SG_  "GenSigInvalidValue" INT 0 10000000000;
BA_DEF_ BU_  "CANoeNodTxTimingIgnitionSwitched" ENUM  "AccOn","IG1On","IG2On","NoNodTxTiming";
BA_DEF_ BO_  "CANoeMsgTxTimingIgnitionSwitched" ENUM  "AccOn","IG1On","IG2On","NoMsgTxTiming";
BA_DEF_  "NM_Active" ENUM  "Active","NotActive";
BA_DEF_REL_ BU_SG_REL_  "SC_Verification" ENUM  "No","Yes";
BA_DEF_DEF_  "BusType" "CAN";
BA_DEF_DEF_  "DiagNode" "Yes";
BA_DEF_DEF_REL_ "SC_Verification" "Yes";
BA_DEF_DEF_  "SCP_FreshnessValueTxLength" 4;
BA_DEF_DEF_  "SCP_FreshnessValueLength" 48;
BA_DEF_DEF_  "SCP_DataId" 0;
BA_DEF_DEF_  "SCP_AuthInfoTxLength" 28;
BA_DEF_DEF_  "SC_Message" "No";
BA_DEF_DEF_  "CANFD_BRS" "1";
BA_DEF_DEF_  "VFrameFormat" "ExtendedCAN_FD";
BA_DEF_DEF_  "DiagRequest" "No";
BA_DEF_DEF_  "DiagResponse" "No";
BA_DEF_DEF_  "DiagState" "No";
BA_DEF_DEF_  "DiagConnection" 0;
BA_DEF_DEF_  "EOL_SB_Flash" "Yes";
BA_DEF_DEF_  "GatewayECU" "No";
BA_DEF_DEF_  "GenMsgCycleTime" 0;
BA_DEF_DEF_  "GenMsgCycleTimeFast" 0;
BA_DEF_DEF_  "GenMsgDelayTime" 20;
BA_DEF_DEF_  "GenMsgILSupport" "Yes";
BA_DEF_DEF_  "GenMsgNrOfRepetition" 0;
BA_DEF_DEF_  "GenMsgSendType" "NoMsgSendType";
BA_DEF_DEF_  "GenSigSendType" "NoSigSendType";
BA_DEF_DEF_  "GenSigStartValue" 0;
BA_DEF_DEF_  "GenSigTimeoutTime_RCM" 5000;
BA_DEF_DEF_  "GenSigTimeoutTime_FSC" 5000;
BA_DEF_DEF_  "GenSigTimeoutTime_EPAS" 5000;
BA_DEF_DEF_  "GenSigTimeoutTime_ECB" 5000;
BA_DEF_DEF_  "GenSigTimeoutTime_DSC" 5000;
BA_DEF_DEF_  "GenSigTimeoutTime_CGW" 5000;
BA_DEF_DEF_  "ILUsed" "No";
BA_DEF_DEF_  "Manufacturer" "Ford";
BA_DEF_DEF_  "NetworkInitialization" "No";
BA_DEF_DEF_  "NetworkType" "Powertrain";
BA_DEF_DEF_  "NmBaseAddress" 1280;
BA_DEF_DEF_  "NmCAN" 1;
BA_DEF_DEF_  "NmMessageCount" 128;
BA_DEF_DEF_  "NmType" "Ford-OSEK";
BA_DEF_DEF_  "NodeLayerModules" "";
BA_DEF_DEF_  "PowerType" "Ignition Switched";
BA_DEF_DEF_  "TransceiverType" "Unknown";
BA_DEF_DEF_  "Version_Ccl" "00.00.00";
BA_DEF_DEF_  "Version_Diag_CANdesc" "00.00.00";
BA_DEF_DEF_  "Version_DrvCan" "00.00.00";
BA_DEF_DEF_  "Version_GW_ILGateway" "00.00.00";
BA_DEF_DEF_  "Version_IL_NI_Ford" "00.00.00";
BA_DEF_DEF_  "Version_IL_Vector" "00.00.00";
BA_DEF_DEF_  "Version_NM_DirOsek" "00.00.00";
BA_DEF_DEF_  "Version_NM_Junior" "00.00.00";
BA_DEF_DEF_  "Version_Tp_Iso15765" "00.00.00";
BA_DEF_DEF_  "VersionDay" 1;
BA_DEF_DEF_  "VersionMonth" 1;
BA_DEF_DEF_  "VersionNumber" 1;
BA_DEF_DEF_  "VersionYear" 2005;
BA_DEF_DEF_  "GenSigEnvVarType" "undef";
BA_DEF_DEF_  "NmAsrNode" "No";
BA_DEF_DEF_  "NmAsrTimeoutTime" 1000;
BA_DEF_DEF_  "NmAsrWaitBusSleepTime" 750;
BA_DEF_DEF_  "NmAsrRepeatMessageTime" 400;
BA_DEF_DEF_  "NmAsrMessage" "No";
BA_DEF_DEF_  "NmAsrMessageCount" 128;
BA_DEF_DEF_  "NmAsrBaseAddress" 1408;
BA_DEF_DEF_  "NmAsrNodeIdentifier" 0;
BA_DEF_DEF_  "NmAsrCanMsgCycleTime" 100;
BA_DEF_DEF_  "NmAsrCanMsgReducedTime" 50;
BA_DEF_DEF_  "GenMsgTxConditionIg1On" "No";
BA_DEF_DEF_  "GenMsgTxConditionPlusBOn" "No";
BA_DEF_DEF_  "GenSigSuprvResp_CGW" "None";
BA_DEF_DEF_  "GenSigSuprvRespSubValue_CGW" 0;
BA_DEF_DEF_  "GenSigInvalidValue" 0;
BA_DEF_DEF_  "CANoeNodTxTimingIgnitionSwitched" "NoNodTxTiming";
BA_DEF_DEF_  "CANoeMsgTxTimingIgnitionSwitched" "NoMsgTxTiming";
BA_DEF_DEF_  "NM_Active" "NotActive";
BA_ "NmAsrCanMsgCycleTime" 1000;
BA_ "NmAsrRepeatMessageTime" 5000;
BA_ "NmAsrWaitBusSleepTime" 1500;
BA_ "NmAsrTimeoutTime" 3000;
BA_ "NmType" "NmAsr";
BA_ "VersionYear" 2023;
BA_ "VersionDay" 25;
BA_ "VersionNumber" 0;
BA_ "DiagNode" BU_ Traffic 0;
BA_ "NodeLayerModules" BU_ Tester "osek_tp.dll";
BA_ "CANoeNodTxTimingIgnitionSwitched" BU_ Tester 1;
BA_ "ILUsed" BU_ RCM 1;
BA_ "CANoeNodTxTimingIgnitionSwitched" BU_ RCM 1;
BA_ "DiagNode" BU_ FSC 0;
BA_ "CANoeNodTxTimingIgnitionSwitched" BU_ FSC 1;
BA_ "CANoeNodTxTimingIgnitionSwitched" BU_ EPAS 1;
BA_ "PowerType" BU_ ECB 2;
BA_ "NodeLayerModules" BU_ ECB "AsrNm30.dll";
BA_ "NmAsrNode" BU_ ECB 1;
BA_ "NmAsrCanMsgReducedTime" BU_ ECB 1000;
BA_ "NmAsrNodeIdentifier" BU_ ECB 42;
BA_ "PowerType" BU_ DSC 2;
BA_ "NodeLayerModules" BU_ DSC "AsrNm30.dll";
BA_ "NmAsrNode" BU_ DSC 1;
BA_ "NmAsrCanMsgReducedTime" BU_ DSC 1000;
BA_ "NmAsrNodeIdentifier" BU_ DSC 22;
BA_ "PowerType" BU_ CGW 2;
BA_ "GatewayECU" BU_ CGW 1;
BA_ "DiagNode" BU_ CGW 0;
BA_ "NodeLayerModules" BU_ CGW "AsrNm30.dll";
BA_ "NmAsrNode" BU_ CGW 1;
BA_ "NmAsrCanMsgReducedTime" BU_ CGW 1000;
BA_ "NmAsrNodeIdentifier" BU_ CGW 1;
BA_ "CANFD_BRS" BO_ 2041 0;
BA_ "VFrameFormat" BO_ 2041 0;
BA_ "GenMsgSendType" BO_ 2041 1;
BA_ "CANFD_BRS" BO_ 2033 0;
BA_ "VFrameFormat" BO_ 2033 0;
BA_ "GenMsgSendType" BO_ 2033 1;
BA_ "CANFD_BRS" BO_ 2028 0;
BA_ "VFrameFormat" BO_ 2028 0;
BA_ "GenMsgDelayTime" BO_ 2028 0;
BA_ "GenMsgILSupport" BO_ 2028 0;
BA_ "DiagConnection" BO_ 2028 57572;
BA_ "DiagResponse" BO_ 2028 1;
BA_ "GenMsgSendType" BO_ 2028 1;
BA_ "CANFD_BRS" BO_ 2020 0;
BA_ "VFrameFormat" BO_ 2020 0;
BA_ "GenMsgILSupport" BO_ 2020 0;
BA_ "DiagConnection" BO_ 2020 57572;
BA_ "DiagRequest" BO_ 2020 1;
BA_ "GenMsgSendType" BO_ 2020 1;
BA_ "CANFD_BRS" BO_ 2015 0;
BA_ "VFrameFormat" BO_ 2015 0;
BA_ "GenMsgILSupport" BO_ 2015 0;
BA_ "DiagConnection" BO_ 2015 57344;
BA_ "DiagState" BO_ 2015 1;
BA_ "GenMsgSendType" BO_ 2015 1;
BA_ "CANFD_BRS" BO_ 1896 0;
BA_ "VFrameFormat" BO_ 1896 0;
BA_ "GenMsgDelayTime" BO_ 1896 0;
BA_ "GenMsgILSupport" BO_ 1896 0;
BA_ "DiagConnection" BO_ 1896 57440;
BA_ "DiagResponse" BO_ 1896 1;
BA_ "GenMsgSendType" BO_ 1896 1;
BA_ "CANFD_BRS" BO_ 1888 0;
BA_ "VFrameFormat" BO_ 1888 0;
BA_ "GenMsgILSupport" BO_ 1888 0;
BA_ "DiagConnection" BO_ 1888 57440;
BA_ "DiagRequest" BO_ 1888 1;
BA_ "GenMsgSendType" BO_ 1888 1;
BA_ "CANFD_BRS" BO_ 1855 0;
BA_ "VFrameFormat" BO_ 1855 0;
BA_ "GenMsgDelayTime" BO_ 1855 0;
BA_ "GenMsgILSupport" BO_ 1855 0;
BA_ "DiagConnection" BO_ 1855 57399;
BA_ "DiagResponse" BO_ 1855 1;
BA_ "GenMsgSendType" BO_ 1855 1;
BA_ "CANFD_BRS" BO_ 1848 0;
BA_ "VFrameFormat" BO_ 1848 0;
BA_ "GenMsgDelayTime" BO_ 1848 0;
BA_ "GenMsgILSupport" BO_ 1848 0;
BA_ "DiagConnection" BO_ 1848 57392;
BA_ "DiagResponse" BO_ 1848 1;
BA_ "GenMsgSendType" BO_ 1848 1;
BA_ "CANFD_BRS" BO_ 1847 0;
BA_ "VFrameFormat" BO_ 1847 0;
BA_ "GenMsgILSupport" BO_ 1847 0;
BA_ "DiagConnection" BO_ 1847 57399;
BA_ "DiagRequest" BO_ 1847 1;
BA_ "GenMsgSendType" BO_ 1847 1;
BA_ "CANFD_BRS" BO_ 1840 0;
BA_ "VFrameFormat" BO_ 1840 0;
BA_ "GenMsgILSupport" BO_ 1840 0;
BA_ "DiagConnection" BO_ 1840 57392;
BA_ "DiagRequest" BO_ 1840 1;
BA_ "GenMsgSendType" BO_ 1840 1;
BA_ "CANFD_BRS" BO_ 1543 0;
BA_ "VFrameFormat" BO_ 1543 0;
BA_ "GenMsgILSupport" BO_ 1543 0;
BA_ "GenMsgSendType" BO_ 1543 1;
BA_ "CANFD_BRS" BO_ 1542 0;
BA_ "VFrameFormat" BO_ 1542 0;
BA_ "GenMsgILSupport" BO_ 1542 0;
BA_ "GenMsgSendType" BO_ 1542 1;
BA_ "CANFD_BRS" BO_ 1450 0;
BA_ "VFrameFormat" BO_ 1450 0;
BA_ "GenMsgILSupport" BO_ 1450 0;
BA_ "NmAsrMessage" BO_ 1450 1;
BA_ "GenMsgSendType" BO_ 1450 1;
BA_ "CANFD_BRS" BO_ 1430 0;
BA_ "VFrameFormat" BO_ 1430 0;
BA_ "GenMsgILSupport" BO_ 1430 0;
BA_ "NmAsrMessage" BO_ 1430 1;
BA_ "GenMsgSendType" BO_ 1430 1;
BA_ "GenMsgTxConditionIg1On" BO_ 1417 1;
BA_ "CANFD_BRS" BO_ 1417 0;
BA_ "VFrameFormat" BO_ 1417 0;
BA_ "GenMsgCycleTime" BO_ 1417 1000;
BA_ "GenMsgSendType" BO_ 1417 5;
BA_ "CANFD_BRS" BO_ 1409 0;
BA_ "VFrameFormat" BO_ 1409 0;
BA_ "GenMsgILSupport" BO_ 1409 0;
BA_ "NmAsrMessage" BO_ 1409 1;
BA_ "GenMsgSendType" BO_ 1409 1;
BA_ "GenMsgTxConditionPlusBOn" BO_ 1329 1;
BA_ "CANFD_BRS" BO_ 1329 0;
BA_ "VFrameFormat" BO_ 1329 0;
BA_ "GenMsgCycleTime" BO_ 1329 500;
BA_ "GenMsgSendType" BO_ 1329 0;
BA_ "GenMsgTxConditionIg1On" BO_ 1325 1;
BA_ "CANFD_BRS" BO_ 1325 0;
BA_ "VFrameFormat" BO_ 1325 0;
BA_ "GenMsgCycleTime" BO_ 1325 500;
BA_ "GenMsgSendType" BO_ 1325 0;
BA_ "GenMsgTxConditionIg1On" BO_ 1324 1;
BA_ "CANFD_BRS" BO_ 1324 0;
BA_ "VFrameFormat" BO_ 1324 0;
BA_ "GenMsgCycleTime" BO_ 1324 500;
BA_ "GenMsgSendType" BO_ 1324 0;
BA_ "GenMsgTxConditionPlusBOn" BO_ 1307 1;
BA_ "CANFD_BRS" BO_ 1307 0;
BA_ "VFrameFormat" BO_ 1307 0;
BA_ "GenMsgCycleTime" BO_ 1307 500;
BA_ "GenMsgSendType" BO_ 1307 0;
BA_ "GenMsgTxConditionIg1On" BO_ 1280 1;
BA_ "CANFD_BRS" BO_ 1280 0;
BA_ "VFrameFormat" BO_ 1280 0;
BA_ "GenMsgSendType" BO_ 1280 1;
BA_ "GenMsgTxConditionIg1On" BO_ 1264 1;
BA_ "CANFD_BRS" BO_ 1264 0;
BA_ "VFrameFormat" BO_ 1264 0;
BA_ "NetworkInitialization" BO_ 1264 1;
BA_ "GenMsgCycleTime" BO_ 1264 1000;
BA_ "GenMsgSendType" BO_ 1264 0;
BA_ "GenMsgTxConditionPlusBOn" BO_ 1254 1;
BA_ "CANFD_BRS" BO_ 1254 0;
BA_ "VFrameFormat" BO_ 1254 0;
BA_ "GenMsgCycleTime" BO_ 1254 1000;
BA_ "GenMsgSendType" BO_ 1254 5;
BA_ "GenMsgTxConditionPlusBOn" BO_ 1170 1;
BA_ "CANFD_BRS" BO_ 1170 0;
BA_ "VFrameFormat" BO_ 1170 0;
BA_ "GenMsgCycleTime" BO_ 1170 500;
BA_ "GenMsgSendType" BO_ 1170 5;
BA_ "GenMsgTxConditionIg1On" BO_ 1121 1;
BA_ "CANFD_BRS" BO_ 1121 0;
BA_ "VFrameFormat" BO_ 1121 0;
BA_ "GenMsgCycleTime" BO_ 1121 1000;
BA_ "GenMsgSendType" BO_ 1121 0;
BA_ "GenMsgTxConditionPlusBOn" BO_ 1120 1;
BA_ "CANFD_BRS" BO_ 1120 0;
BA_ "VFrameFormat" BO_ 1120 0;
BA_ "GenMsgNrOfRepetition" BO_ 1120 5;
BA_ "GenMsgCycleTimeFast" BO_ 1120 50;
BA_ "GenMsgCycleTime" BO_ 1120 500;
BA_ "GenMsgSendType" BO_ 1120 5;
BA_ "GenMsgTxConditionPlusBOn" BO_ 1106 1;
BA_ "CANFD_BRS" BO_ 1106 0;
BA_ "VFrameFormat" BO_ 1106 0;
BA_ "GenMsgCycleTime" BO_ 1106 100;
BA_ "GenMsgSendType" BO_ 1106 5;
BA_ "GenMsgTxConditionPlusBOn" BO_ 1099 1;
BA_ "CANFD_BRS" BO_ 1099 0;
BA_ "VFrameFormat" BO_ 1099 0;
BA_ "GenMsgCycleTime" BO_ 1099 100;
BA_ "GenMsgSendType" BO_ 1099 5;
BA_ "GenMsgTxConditionPlusBOn" BO_ 1098 1;
BA_ "CANFD_BRS" BO_ 1098 0;
BA_ "VFrameFormat" BO_ 1098 0;
BA_ "GenMsgCycleTime" BO_ 1098 100;
BA_ "GenMsgSendType" BO_ 1098 5;
BA_ "GenMsgTxConditionPlusBOn" BO_ 1096 1;
BA_ "CANFD_BRS" BO_ 1096 0;
BA_ "VFrameFormat" BO_ 1096 0;
BA_ "GenMsgCycleTime" BO_ 1096 100;
BA_ "GenMsgSendType" BO_ 1096 5;
BA_ "GenMsgTxConditionPlusBOn" BO_ 1095 1;
BA_ "CANFD_BRS" BO_ 1095 0;
BA_ "VFrameFormat" BO_ 1095 0;
BA_ "GenMsgCycleTime" BO_ 1095 100;
BA_ "GenMsgSendType" BO_ 1095 5;
BA_ "GenMsgTxConditionPlusBOn" BO_ 1088 1;
BA_ "CANFD_BRS" BO_ 1088 0;
BA_ "VFrameFormat" BO_ 1088 0;
BA_ "GenMsgNrOfRepetition" BO_ 1088 5;
BA_ "GenMsgCycleTimeFast" BO_ 1088 50;
BA_ "GenMsgCycleTime" BO_ 1088 500;
BA_ "GenMsgSendType" BO_ 1088 5;
BA_ "GenMsgTxConditionPlusBOn" BO_ 1081 1;
BA_ "CANFD_BRS" BO_ 1081 0;
BA_ "VFrameFormat" BO_ 1081 0;
BA_ "GenMsgCycleTime" BO_ 1081 200;
BA_ "GenMsgSendType" BO_ 1081 0;
BA_ "GenMsgTxConditionPlusBOn" BO_ 1078 1;
BA_ "CANFD_BRS" BO_ 1078 0;
BA_ "VFrameFormat" BO_ 1078 0;
BA_ "GenMsgCycleTime" BO_ 1078 50;
BA_ "GenMsgSendType" BO_ 1078 5;
BA_ "GenMsgTxConditionPlusBOn" BO_ 1077 1;
BA_ "CANFD_BRS" BO_ 1077 0;
BA_ "VFrameFormat" BO_ 1077 0;
BA_ "GenMsgCycleTime" BO_ 1077 200;
BA_ "GenMsgSendType" BO_ 1077 0;
BA_ "GenMsgTxConditionPlusBOn" BO_ 1068 1;
BA_ "CANFD_BRS" BO_ 1068 0;
BA_ "VFrameFormat" BO_ 1068 0;
BA_ "GenMsgCycleTime" BO_ 1068 500;
BA_ "GenMsgSendType" BO_ 1068 5;
BA_ "GenMsgTxConditionPlusBOn" BO_ 1066 1;
BA_ "CANFD_BRS" BO_ 1066 0;
BA_ "VFrameFormat" BO_ 1066 0;
BA_ "SCP_DataId" BO_ 1066 1066;
BA_ "SC_Message" BO_ 1066 1;
BA_ "GenMsgSendType" BO_ 1066 1;
BA_ "GenMsgTxConditionPlusBOn" BO_ 1046 1;
BA_ "CANFD_BRS" BO_ 1046 0;
BA_ "VFrameFormat" BO_ 1046 0;
BA_ "GenMsgCycleTime" BO_ 1046 100;
BA_ "SCP_DataId" BO_ 1046 1046;
BA_ "SC_Message" BO_ 1046 1;
BA_ "GenMsgSendType" BO_ 1046 5;
BA_ "GenMsgTxConditionPlusBOn" BO_ 1045 1;
BA_ "CANFD_BRS" BO_ 1045 0;
BA_ "VFrameFormat" BO_ 1045 0;
BA_ "GenMsgCycleTime" BO_ 1045 100;
BA_ "GenMsgSendType" BO_ 1045 5;
BA_ "GenMsgTxConditionPlusBOn" BO_ 1044 1;
BA_ "CANFD_BRS" BO_ 1044 0;
BA_ "VFrameFormat" BO_ 1044 0;
BA_ "GenMsgCycleTime" BO_ 1044 100;
BA_ "SCP_DataId" BO_ 1044 1044;
BA_ "SC_Message" BO_ 1044 1;
BA_ "GenMsgSendType" BO_ 1044 5;
BA_ "GenMsgTxConditionPlusBOn" BO_ 1034 1;
BA_ "CANFD_BRS" BO_ 1034 0;
BA_ "VFrameFormat" BO_ 1034 0;
BA_ "GenMsgCycleTime" BO_ 1034 50;
BA_ "GenMsgSendType" BO_ 1034 0;
BA_ "GenSigSendType" SG_ 2041 RCM_SCRAP_Diag_Sig_Tx 3;
BA_ "GenSigSendType" SG_ 2033 RCM_SCRAP_Diag_Sig_Rx 3;
BA_ "GenSigSendType" SG_ 2028 BSCM_Diag_Tx 3;
BA_ "GenSigSendType" SG_ 2020 BSCM_Diag_Rx 3;
BA_ "GenSigSendType" SG_ 2015 OBD_II_Broadcast_Info 3;
BA_ "GenSigSendType" SG_ 1896 ABS_Diag_Sig_Tx 3;
BA_ "GenSigSendType" SG_ 1888 ABS_Diag_Sig_Rx 3;
BA_ "GenSigSendType" SG_ 1855 RCM_Diag_Sig_Tx 3;
BA_ "GenSigSendType" SG_ 1848 EPAS_Diag_Sig_Tx 3;
BA_ "GenSigSendType" SG_ 1847 RCM_Diag_Sig_Rx 3;
BA_ "GenSigSendType" SG_ 1840 EPAS_Diag_Sig_Rx 3;
BA_ "GenSigSendType" SG_ 1543 CCPMessageDataEPAS7_Tx 1;
BA_ "GenSigSendType" SG_ 1543 CCPMessageDataEPAS6_Tx 1;
BA_ "GenSigSendType" SG_ 1543 CCPMessageDataEPAS5_Tx 1;
BA_ "GenSigSendType" SG_ 1543 CCPMessageDataEPAS4_Tx 1;
BA_ "GenSigSendType" SG_ 1543 CCPMessageDataEPAS3_Tx 1;
BA_ "GenSigSendType" SG_ 1543 CCPMessageDataEPAS2_Tx 1;
BA_ "GenSigSendType" SG_ 1543 CCPMessageDataEPAS1_Tx 1;
BA_ "GenSigSendType" SG_ 1543 CCPMessageDataEPAS_Tx 1;
BA_ "GenSigSendType" SG_ 1542 CCPMessageDataEPAS7_Rx 1;
BA_ "GenSigSendType" SG_ 1542 CCPMessageDataEPAS6_Rx 1;
BA_ "GenSigSendType" SG_ 1542 CCPMessageDataEPAS5_Rx 1;
BA_ "GenSigSendType" SG_ 1542 CCPMessageDataEPAS4_Rx 1;
BA_ "GenSigSendType" SG_ 1542 CCPMessageDataEPAS3_Rx 1;
BA_ "GenSigSendType" SG_ 1542 CCPMessageDataEPAS2_Rx 1;
BA_ "GenSigSendType" SG_ 1542 CCPMessageDataEPAS1_Rx 1;
BA_ "GenSigSendType" SG_ 1542 CCPMessageDataEPAS_Rx 1;
BA_ "GenSigSendType" SG_ 1417 SFTWNG 3;
BA_ "GenSigSendType" SG_ 1280 VDT_RCM_EDR8 1;
BA_ "GenSigSendType" SG_ 1280 VDT_RCM_EDR7 1;
BA_ "GenSigSendType" SG_ 1280 VDT_RCM_EDR6 1;
BA_ "GenSigSendType" SG_ 1280 VDT_RCM_EDR5 1;
BA_ "GenSigSendType" SG_ 1280 VDT_RCM_EDR4 1;
BA_ "GenSigSendType" SG_ 1280 VDT_RCM_EDR3 1;
BA_ "GenSigSendType" SG_ 1280 VDT_RCM_EDR2 1;
BA_ "GenSigSendType" SG_ 1280 VDT_RCM_EDR1 1;
BA_ "GenSigInvalidValue" SG_ 1264 AxleRatioFront 65535;
BA_ "GenSigSendType" SG_ 1254 VDT_Cancel_Resp_Counter2 3;
BA_ "GenSigSendType" SG_ 1254 VDT_Resp_Counter2 3;
BA_ "GenSigSendType" SG_ 1254 VDT_INV_ODR2_ReqTCU 3;
BA_ "GenSigSendType" SG_ 1254 VDT_INV_ODR2_Rq 3;
BA_ "GenSigSendType" SG_ 1254 VDT_ECM_ODR1_ReqTCU 3;
BA_ "GenSigSendType" SG_ 1254 VDT_ECM_ODR1_Rq 3;
BA_ "GenSigSendType" SG_ 1254 VDT_RCM_ODR1_ReqTCU 3;
BA_ "GenSigSendType" SG_ 1254 VDT_RCM_ODR1_Rq 3;
BA_ "GenSigSendType" SG_ 1254 TCU_SW_Update_Resp 3;
BA_ "GenSigSendType" SG_ 1254 VDT_Cancel_PreAC_Resp 3;
BA_ "GenSigSendType" SG_ 1254 VDT_PreAC_Resp 3;
BA_ "GenSigSendType" SG_ 1254 VDT_Cancel_Charge_Resp 3;
BA_ "GenSigSendType" SG_ 1254 VDT_Charge_Resp 3;
BA_ "GenSigSendType" SG_ 1170 CstmzStat_CTS_HighWay 3;
BA_ "GenSigSendType" SG_ 1170 CstmzStat_FCTA_ONOFF 3;
BA_ "GenSigSendType" SG_ 1170 CstmzStat_FCTA_Sens 3;
BA_ "GenSigSendType" SG_ 1170 CstmzStat_TAP_ONOFF 3;
BA_ "GenSigSendType" SG_ 1170 CstmzStat_ELK_ONOFF 3;
BA_ "GenSigSendType" SG_ 1170 CstmzStat_RAEB_ONOFF 3;
BA_ "GenSigSendType" SG_ 1170 CstmzStat_FAEB_Sens 3;
BA_ "GenSigSendType" SG_ 1170 CstmzStat_FAEB_ONOFF 3;
BA_ "GenSigSendType" SG_ 1170 CstmzStat_CTB_ONOFF 3;
BA_ "GenSigSendType" SG_ 1170 CstmzStat_LDP_ONOFF 3;
BA_ "GenSigSendType" SG_ 1170 CstmzStat_DAS_ONOFF 3;
BA_ "GenSigSendType" SG_ 1170 CstmzStat_LDP_RDP_Warn 3;
BA_ "GenSigSendType" SG_ 1170 CstmzStat_BSM_Sens 3;
BA_ "GenSigSendType" SG_ 1170 CstmzStat_BSM_ONOFF 3;
BA_ "GenSigSendType" SG_ 1170 CstmzStat_LDW_ONOFF 3;
BA_ "GenSigSendType" SG_ 1170 CstmzStat_RCTB_ONOFF 3;
BA_ "GenSigSendType" SG_ 1170 CstmzStat_FCTB_Disp_ONOFF 3;
BA_ "GenSigSendType" SG_ 1170 CstmzStat_FCTB_ONOFF 3;
BA_ "GenSigSendType" SG_ 1170 CstmzStat_SpLmt_Warn_Thres 3;
BA_ "GenSigSendType" SG_ 1170 CstmzStat_SpLmt_Warn 3;
BA_ "GenSigSendType" SG_ 1170 CstmzStat_TSR_Warn_Thres 3;
BA_ "GenSigSendType" SG_ 1170 CstmzStat_TSR_Warn 3;
BA_ "GenSigSendType" SG_ 1170 CstmzStat_MRCC_Bz_ONOFF 3;
BA_ "GenSigSendType" SG_ 1170 CstmzStat_TSR_Mode 3;
BA_ "GenSigSendType" SG_ 1170 CstmzStat_MRCC_ASC_Mode 3;
BA_ "GenSigSendType" SG_ 1170 CstmzStat_TJA_Mode 3;
BA_ "GenSigSendType" SG_ 1170 Target_ID_VStat01 3;
BA_ "GenSigInvalidValue" SG_ 1120 BackupBatteryMid_U_Actl 1023;
BA_ "GenSigSendType" SG_ 1120 DrLock_Message_R_Rsp 4;
BA_ "GenSigSendType" SG_ 1120 DrStatRl_B_Actl 4;
BA_ "GenSigStartValue" SG_ 1120 DrStatR_D_Qf 1;
BA_ "GenSigSendType" SG_ 1120 DrStatR_D_Qf 4;
BA_ "GenSigSendType" SG_ 1120 TrnkLg_Motor_Stat 4;
BA_ "GenSigSendType" SG_ 1120 Fuel_Lid_Open_Status 4;
BA_ "GenSigSendType" SG_ 1120 StopLampCon_Status 4;
BA_ "GenSigStartValue" SG_ 1120 SeatBeltStat_D_Actl 128;
BA_ "GenSigSendType" SG_ 1120 DrStatTrnkLg_B_Actl 4;
BA_ "GenSigSendType" SG_ 1120 ParkBrkActv_D_Actl2 4;
BA_ "GenSigSendType" SG_ 1120 AutoHoldSw_B_Actl 4;
BA_ "GenSigSendType" SG_ 1106 CBDA_target_lh 3;
BA_ "GenSigSendType" SG_ 1106 CBDA_target_rh 3;
BA_ "GenSigSendType" SG_ 1106 CBDA_EV_failure 3;
BA_ "GenSigSendType" SG_ 1106 CBDA_EV_tmp_failure 3;
BA_ "GenSigSendType" SG_ 1106 CBDA_EV_fallback 3;
BA_ "GenSigSendType" SG_ 1106 CBDA_fallback 3;
BA_ "GenSigSendType" SG_ 1106 CBDA_state 3;
BA_ "GenSigSendType" SG_ 1106 LDW_lane_lh 3;
BA_ "GenSigSendType" SG_ 1106 LDW_lane_rh 3;
BA_ "GenSigSendType" SG_ 1106 LDW_EV_failure 3;
BA_ "GenSigSendType" SG_ 1106 LDW_EV_tmp_failure 3;
BA_ "GenSigSendType" SG_ 1106 LDW_EV_warning_rh 3;
BA_ "GenSigSendType" SG_ 1106 LDW_EV_warning_lh 3;
BA_ "GenSigSendType" SG_ 1106 LDW_fallback 3;
BA_ "GenSigSendType" SG_ 1106 LDW_state 3;
BA_ "GenSigSendType" SG_ 1106 OCP_opp_lh 3;
BA_ "GenSigSendType" SG_ 1106 OCP_opp_rh 3;
BA_ "GenSigSendType" SG_ 1106 OCP_lane_lh 3;
BA_ "GenSigSendType" SG_ 1106 OCP_lane_rh 3;
BA_ "GenSigSendType" SG_ 1106 OCP_EV_failure 3;
BA_ "GenSigSendType" SG_ 1106 OCP_EV_tmp_failure 3;
BA_ "GenSigSendType" SG_ 1106 OCP_alarm 3;
BA_ "GenSigSendType" SG_ 1106 OCP_fallback 3;
BA_ "GenSigSendType" SG_ 1106 OCP_state 3;
BA_ "GenSigSendType" SG_ 1106 BSP_alarm 3;
BA_ "GenSigSendType" SG_ 1106 BSP_target_lh 3;
BA_ "GenSigSendType" SG_ 1106 BSP_target_rh 3;
BA_ "GenSigSendType" SG_ 1106 BSP_lane_lh 3;
BA_ "GenSigSendType" SG_ 1106 BSP_lane_rh 3;
BA_ "GenSigSendType" SG_ 1106 BSP_EV_failure 3;
BA_ "GenSigSendType" SG_ 1106 BSP_EV_tmp_failure 3;
BA_ "GenSigSendType" SG_ 1106 BSP_fallback 3;
BA_ "GenSigSendType" SG_ 1106 BSP_state 3;
BA_ "GenSigSendType" SG_ 1099 REDKEY_EV_on 3;
BA_ "GenSigSendType" SG_ 1099 REDKEY_state 3;
BA_ "GenSigSendType" SG_ 1099 ISA_EV_failure 3;
BA_ "GenSigSendType" SG_ 1099 ISA_EV_fallback 3;
BA_ "GenSigSendType" SG_ 1099 ISA_EV_kickdown 3;
BA_ "GenSigSendType" SG_ 1099 ISA_EV_reject 3;
BA_ "GenSigSendType" SG_ 1099 ISA_EV_spd_autoset 3;
BA_ "GenSigSendType" SG_ 1099 ISA_sign 3;
BA_ "GenSigSendType" SG_ 1099 ISA_state 3;
BA_ "GenSigSendType" SG_ 1099 ISA_fallback 3;
BA_ "GenSigSendType" SG_ 1099 ASC_EV_failure 3;
BA_ "GenSigSendType" SG_ 1099 ASC_EV_suspended 3;
BA_ "GenSigSendType" SG_ 1099 ASC_EV_reject 3;
BA_ "GenSigSendType" SG_ 1099 ASC_EV_accept 3;
BA_ "GenSigSendType" SG_ 1099 ASC_state 3;
BA_ "GenSigSendType" SG_ 1098 LKA_target 3;
BA_ "GenSigSendType" SG_ 1098 LKA_EV_dassw_reject 3;
BA_ "GenSigSendType" SG_ 1098 LKA_EV_failure 3;
BA_ "GenSigSendType" SG_ 1098 LKA_EV_tmp_failure 3;
BA_ "GenSigSendType" SG_ 1098 LKA_EV_fallback 3;
BA_ "GenSigSendType" SG_ 1098 LKA_EV_suspended 3;
BA_ "GenSigSendType" SG_ 1098 LKA_handsfree 3;
BA_ "GenSigSendType" SG_ 1098 LKA_EV_reject 3;
BA_ "GenSigSendType" SG_ 1098 LKA_control_limit_rh 3;
BA_ "GenSigSendType" SG_ 1098 LKA_control_limit_lh 3;
BA_ "GenSigSendType" SG_ 1098 LKA_fallback 3;
BA_ "GenSigSendType" SG_ 1098 LKA_EV_inactive_handsfree 3;
BA_ "GenSigSendType" SG_ 1098 LKA_EV_inactive_handson 3;
BA_ "GenSigSendType" SG_ 1098 LKA_state 3;
BA_ "GenSigSendType" SG_ 1098 ACC_target_distance 3;
BA_ "GenSigSendType" SG_ 1098 ACC_set_distance 3;
BA_ "GenSigInvalidValue" SG_ 1098 ACC_set_velocity 255;
BA_ "GenSigSendType" SG_ 1098 ACC_set_velocity 3;
BA_ "GenSigSendType" SG_ 1098 ACC_EV_dassw_reject 3;
BA_ "GenSigSendType" SG_ 1098 ACC_EV_set_dist 3;
BA_ "GenSigSendType" SG_ 1098 ACC_EV_failure 3;
BA_ "GenSigSendType" SG_ 1098 ACC_EV_tmp_failure 3;
BA_ "GenSigSendType" SG_ 1098 ACC_EV_fallback2 3;
BA_ "GenSigSendType" SG_ 1098 ACC_EV_fallback1 3;
BA_ "GenSigSendType" SG_ 1098 ACC_EV_suspended 3;
BA_ "GenSigSendType" SG_ 1098 ACC_EV_start 3;
BA_ "GenSigSendType" SG_ 1098 ACC_shift_position 3;
BA_ "GenSigSendType" SG_ 1098 ACC_warning 3;
BA_ "GenSigSendType" SG_ 1098 ACC_EV_reject 3;
BA_ "GenSigSendType" SG_ 1098 ACC_EV_accept 3;
BA_ "GenSigSendType" SG_ 1098 ACC_fallback 3;
BA_ "GenSigSendType" SG_ 1098 ACC_target 3;
BA_ "GenSigSendType" SG_ 1098 ACC_stop 3;
BA_ "GenSigSendType" SG_ 1098 ACC_sign 3;
BA_ "GenSigSendType" SG_ 1098 ACC_state 3;
BA_ "GenSigSendType" SG_ 1096 LDP_alarm 3;
BA_ "GenSigSendType" SG_ 1096 LDP_fallback 3;
BA_ "GenSigSendType" SG_ 1096 LDP_EV_failure 3;
BA_ "GenSigSendType" SG_ 1096 LDP_EV_tmp_failure 3;
BA_ "GenSigSendType" SG_ 1096 LDP_EV_warning_rh 3;
BA_ "GenSigSendType" SG_ 1096 LDP_EV_warning_lh 3;
BA_ "GenSigSendType" SG_ 1096 LDP_lane_lh 3;
BA_ "GenSigSendType" SG_ 1096 LDP_lane_rh 3;
BA_ "GenSigSendType" SG_ 1096 LDP_state 3;
BA_ "GenSigSendType" SG_ 1096 BSM_EV_failure 3;
BA_ "GenSigSendType" SG_ 1096 BSM_EV_tmp_failure 3;
BA_ "GenSigSendType" SG_ 1096 BSM_EV_warning_rh 3;
BA_ "GenSigSendType" SG_ 1096 BSM_EV_warning_lh 3;
BA_ "GenSigSendType" SG_ 1096 BSM_fallback 3;
BA_ "GenSigSendType" SG_ 1096 BSM_target_lh 3;
BA_ "GenSigSendType" SG_ 1096 BSM_target_rh 3;
BA_ "GenSigSendType" SG_ 1096 BSM_state 3;
BA_ "GenSigSendType" SG_ 1096 RDP_alarm 3;
BA_ "GenSigSendType" SG_ 1096 RDP_fallback 3;
BA_ "GenSigSendType" SG_ 1096 RDP_EV_failure 3;
BA_ "GenSigSendType" SG_ 1096 RDP_EV_tmp_failure 3;
BA_ "GenSigSendType" SG_ 1096 RDP_roadedge_lh 3;
BA_ "GenSigSendType" SG_ 1096 RDP_roadedge_rh 3;
BA_ "GenSigSendType" SG_ 1096 RDP_state 3;
BA_ "GenSigSendType" SG_ 1095 ID447_No_Cs 3;
BA_ "GenSigSendType" SG_ 1095 ID447_No_Cnt 3;
BA_ "GenSigSendType" SG_ 1095 CTB_target_lh 3;
BA_ "GenSigSendType" SG_ 1095 CTB_target_rh 3;
BA_ "GenSigSendType" SG_ 1095 CTB_EV_failure 3;
BA_ "GenSigSendType" SG_ 1095 CTB_EV_tmp_failure 3;
BA_ "GenSigSendType" SG_ 1095 CTB_EV_fallback 3;
BA_ "GenSigSendType" SG_ 1095 CTB_EV_notification 3;
BA_ "GenSigSendType" SG_ 1095 CTB_EV_warning 3;
BA_ "GenSigSendType" SG_ 1095 CTB_EV_off 3;
BA_ "GenSigSendType" SG_ 1095 CTB_fallback 3;
BA_ "GenSigSendType" SG_ 1095 CTB_state 3;
BA_ "GenSigSendType" SG_ 1095 FCTA_target_lh 3;
BA_ "GenSigSendType" SG_ 1095 FCTA_target_rh 3;
BA_ "GenSigSendType" SG_ 1095 FCTA_EV_failure 3;
BA_ "GenSigSendType" SG_ 1095 FCTA_EV_tmp_failure 3;
BA_ "GenSigSendType" SG_ 1095 FCTA_EV_fallback 3;
BA_ "GenSigSendType" SG_ 1095 FCTA_EV_warning2_rh 3;
BA_ "GenSigSendType" SG_ 1095 FCTA_EV_warning2_lh 3;
BA_ "GenSigSendType" SG_ 1095 FCTA_fallback 3;
BA_ "GenSigSendType" SG_ 1095 FCTA_state 3;
BA_ "GenSigSendType" SG_ 1095 PTC_EV_off 3;
BA_ "GenSigSendType" SG_ 1095 PTC_EV_notification 3;
BA_ "GenSigSendType" SG_ 1095 PTC_fallback 3;
BA_ "GenSigSendType" SG_ 1095 PTC_state 3;
BA_ "GenSigSendType" SG_ 1095 AEB_EV_notification 3;
BA_ "GenSigSendType" SG_ 1095 AEB_EV_off 3;
BA_ "GenSigSendType" SG_ 1095 AEB_fallback 3;
BA_ "GenSigSendType" SG_ 1095 AEB_state 3;
BA_ "GenSigSendType" SG_ 1088 Move_AutoDposMirror_Res 4;
BA_ "GenSigInvalidValue" SG_ 1088 BackupBatteryOut_Drv_U_Act 1023;
BA_ "GenSigSendType" SG_ 1088 MirrorLED1_status 4;
BA_ "GenSigSendType" SG_ 1088 DrLock_Message_D_Rsp 4;
BA_ "GenSigSendType" SG_ 1088 DrivingPositionRequest 4;
BA_ "GenSigSendType" SG_ 1088 Mirror_AjustSelSW_Status 4;
BA_ "GenSigSendType" SG_ 1088 MirrorFoldRequest 4;
BA_ "GenSigSendType" SG_ 1088 MirrorAdjustRequest 4;
BA_ "GenSigSendType" SG_ 1088 MirrorAdjst_Manual_Status 4;
BA_ "GenSigSendType" SG_ 1088 MirrorAdjst_Status 4;
BA_ "GenSigSendType" SG_ 1088 Erase_MirrorMem_Res 4;
BA_ "GenSigSendType" SG_ 1088 Recall_MirrorMem_Res 4;
BA_ "GenSigSendType" SG_ 1088 Record_MirrorMem_Res 4;
BA_ "GenSigSendType" SG_ 1088 PW_Move_R 4;
BA_ "GenSigSendType" SG_ 1088 PW_Move_P 4;
BA_ "GenSigSendType" SG_ 1088 PWcut_D_Actl 4;
BA_ "GenSigSendType" SG_ 1088 DrvDLMotorDriveStat 4;
BA_ "GenSigSendType" SG_ 1088 Ctrl_DLSw_Drv_Stat 4;
BA_ "GenSigSendType" SG_ 1088 LockLinkSwDrv_D_Actl 4;
BA_ "GenSigStartValue" SG_ 1088 DrStatDrv_D_Qf 1;
BA_ "GenSigSendType" SG_ 1088 DrStatDrv_D_Qf 4;
BA_ "GenSigSendType" SG_ 1088 DrStatDrv_B_Actl 4;
BA_ "GenSigInvalidValue" SG_ 1081 GMT_Second_ByGPS 255;
BA_ "GenSigStartValue" SG_ 1081 GMT_Second_ByGPS 255;
BA_ "GenSigInvalidValue" SG_ 1081 GMT_Minutes_ByGPS 255;
BA_ "GenSigStartValue" SG_ 1081 GMT_Minutes_ByGPS 255;
BA_ "GenSigInvalidValue" SG_ 1081 GMT_Hour_ByGPS 255;
BA_ "GenSigStartValue" SG_ 1081 GMT_Hour_ByGPS 255;
BA_ "GenSigInvalidValue" SG_ 1081 GMT_Date_ByGPS 255;
BA_ "GenSigStartValue" SG_ 1081 GMT_Date_ByGPS 255;
BA_ "GenSigInvalidValue" SG_ 1081 GMT_Month_ByGPS 255;
BA_ "GenSigStartValue" SG_ 1081 GMT_Month_ByGPS 255;
BA_ "GenSigInvalidValue" SG_ 1081 GMT_Year_ByGPS 255;
BA_ "GenSigStartValue" SG_ 1081 GMT_Year_ByGPS 255;
BA_ "GenSigInvalidValue" SG_ 1081 HorizonByGPS 4294967295;
BA_ "GenSigStartValue" SG_ 1081 HorizonByGPS 4294967295;
BA_ "GenSigInvalidValue" SG_ 1081 Curnt_Second_ByGPS 255;
BA_ "GenSigStartValue" SG_ 1081 Curnt_Second_ByGPS 255;
BA_ "GenSigInvalidValue" SG_ 1081 Curnt_Minutes_ByGPS 255;
BA_ "GenSigStartValue" SG_ 1081 Curnt_Minutes_ByGPS 255;
BA_ "GenSigInvalidValue" SG_ 1081 Curnt_Hour_ByGPS 255;
BA_ "GenSigStartValue" SG_ 1081 Curnt_Hour_ByGPS 255;
BA_ "GenSigInvalidValue" SG_ 1081 LongitudeByGPS 4294967295;
BA_ "GenSigStartValue" SG_ 1081 LongitudeByGPS 4294967295;
BA_ "GenSigInvalidValue" SG_ 1081 Curnt_Date_ByGPS 255;
BA_ "GenSigStartValue" SG_ 1081 Curnt_Date_ByGPS 255;
BA_ "GenSigInvalidValue" SG_ 1081 Curnt_Month_ByGPS 255;
BA_ "GenSigStartValue" SG_ 1081 Curnt_Month_ByGPS 255;
BA_ "GenSigInvalidValue" SG_ 1081 Curnt_Year_ByGPS 255;
BA_ "GenSigStartValue" SG_ 1081 Curnt_Year_ByGPS 255;
BA_ "GenSigInvalidValue" SG_ 1081 LatitudeByGPS 4294967295;
BA_ "GenSigStartValue" SG_ 1081 LatitudeByGPS 4294967295;
BA_ "GenSigSendType" SG_ 1078 SteerHeatIndic_D_Req 3;
BA_ "GenSigSendType" SG_ 1078 SteerHeat_Elm_Enable 3;
BA_ "GenSigSendType" SG_ 1078 SeatHeat_Elm_Enable 3;
BA_ "GenSigSendType" SG_ 1078 Charge_Mode_Enabled_SW 3;
BA_ "GenSigSendType" SG_ 1078 Drive_Mode_Enabled_Switch 3;
BA_ "GenSigSendType" SG_ 1078 atcControlStatus 3;
BA_ "GenSigSendType" SG_ 1078 SeatVentIndicFr_D_Req 3;
BA_ "GenSigSendType" SG_ 1078 SeatVentIndicFl_D_Req 3;
BA_ "GenSigSendType" SG_ 1078 SeatHeatIndicFr_D_Req 3;
BA_ "GenSigSendType" SG_ 1078 SeatHeatIndicFl_D_Req 3;
BA_ "GenSigSendType" SG_ 1078 atcACmodeDisp 3;
BA_ "GenSigSendType" SG_ 1078 atcAImodeDisp 3;
BA_ "GenSigSendType" SG_ 1078 atcADmodeDisp 3;
BA_ "GenSigSendType" SG_ 1078 atcBlwLvlDisp 3;
BA_ "GenSigSendType" SG_ 1078 HvacEngStopCtrl_D_Actl 3;
BA_ "GenSigSendType" SG_ 1078 BlowerSpeed 3;
BA_ "GenSigSendType" SG_ 1078 HvacEngStopInputFail_D_Rq 3;
BA_ "GenSigSendType" SG_ 1078 HvacAirCond_B_Rq 3;
BA_ "GenSigSendType" SG_ 1078 HvacEngStopDis_B_Rq_exceptTEva 3;
BA_ "GenSigSendType" SG_ 1078 HvacEngStopDis_B_Rq 3;
BA_ "GenSigInvalidValue" SG_ 1077 RR_TPrs_Correct 255;
BA_ "GenSigInvalidValue" SG_ 1077 RL_TPrs_Correct 255;
BA_ "GenSigInvalidValue" SG_ 1077 FR_TPrs_Correct 255;
BA_ "GenSigInvalidValue" SG_ 1077 FL_TPrs_Correct 255;
BA_ "GenSigInvalidValue" SG_ 1077 RR_TPrs_DispKG 255;
BA_ "GenSigInvalidValue" SG_ 1077 RL_TPrs_DispKG 255;
BA_ "GenSigInvalidValue" SG_ 1077 FR_TPrs_DispKG 255;
BA_ "GenSigInvalidValue" SG_ 1077 FL_TPrs_DispKG 255;
BA_ "GenSigInvalidValue" SG_ 1077 RR_TPrs_DispPS 255;
BA_ "GenSigInvalidValue" SG_ 1077 RL_TPrs_DispPS 255;
BA_ "GenSigInvalidValue" SG_ 1077 FR_TPrs_DispPS 255;
BA_ "GenSigInvalidValue" SG_ 1077 FL_TPrs_DispPS 255;
BA_ "GenSigStartValue" SG_ 1077 MntSet_Dist 65535;
BA_ "GenSigInvalidValue" SG_ 1077 RR_TPrs_DispBR 255;
BA_ "GenSigInvalidValue" SG_ 1077 RL_TPrs_DispBR 255;
BA_ "GenSigInvalidValue" SG_ 1077 FR_TPrs_DispBR 255;
BA_ "GenSigInvalidValue" SG_ 1077 FL_TPrs_DispBR 255;
BA_ "GenSigStartValue" SG_ 1077 MntTyre_AtFlg 1;
BA_ "GenSigInvalidValue" SG_ 1077 RR_TPrs_DispKP 255;
BA_ "GenSigInvalidValue" SG_ 1077 RL_TPrs_DispKP 255;
BA_ "GenSigInvalidValue" SG_ 1077 FR_TPrs_DispKP 255;
BA_ "GenSigInvalidValue" SG_ 1077 FL_TPrs_DispKP 255;
BA_ "GenSigSendType" SG_ 1068 TCU_ComFail_MsgType 3;
BA_ "GenSigSendType" SG_ 1068 TCU_Service_Flag 3;
BA_ "GenSigSendType" SG_ 1068 TCU_ComStatus_Notification 3;
BA_ "GenSigSendType" SG_ 1068 TCU_SW_Update_Req 3;
BA_ "GenSigSendType" SG_ 1068 VDT_BECM_ODR2_ResTCU 3;
BA_ "GenSigSendType" SG_ 1068 Audio_mute_request_result 3;
BA_ "GenSigSendType" SG_ 1068 Crash_output_relay_result 3;
BA_ "GenSigSendType" SG_ 1068 Fialure_reason 3;
BA_ "GenSigSendType" SG_ 1068 Voice_Communication_result 3;
BA_ "GenSigSendType" SG_ 1068 Data_Transmission_result 3;
BA_ "GenSigSendType" SG_ 1068 Call_Trigger_Type 3;
BA_ "GenSigSendType" SG_ 1068 Recording_Trigger 3;
BA_ "GenSigSendType" SG_ 1068 VDT_Recall_Counter 1;
BA_ "GenSigSendType" SG_ 1068 VDT_Recall_Req 1;
BA_ "GenSigSendType" SG_ 1068 TCU_ComFail_B_Actl 3;
BA_ "GenSigSendType" SG_ 1068 VDT_BCM_Std3_ResTCU 3;
BA_ "GenSigSendType" SG_ 1068 VDT_VCM_ODR2_ResTCU 3;
BA_ "GenSigSendType" SG_ 1068 VDT_TCM_ODR2_ResTCU 3;
BA_ "GenSigSendType" SG_ 1068 VDT_PCM_ODR2_ResTCU 3;
BA_ "GenSigSendType" SG_ 1068 VDT_BCM_Std2_ResTCU 3;
BA_ "GenSigSendType" SG_ 1068 VDT_VCM_ODR1_ResTCU 3;
BA_ "GenSigSendType" SG_ 1068 VDT_PCM_ODR1_ResTCU 3;
BA_ "GenSigSendType" SG_ 1068 VDT_BCM_Std1_ResTCU 3;
BA_ "GenSigSendType" SG_ 1068 CallMute_B_Actl 1;
BA_ "GenSigSendType" SG_ 1066 Hvac_Control_Information2_MACTx 3;
BA_ "GenSigSendType" SG_ 1066 Hvac_Control_Information2_FVTx 3;
BA_ "GenSigStartValue" SG_ 1066 View_RPC_APS_Sw_D_Qf 2;
BA_ "GenSigSendType" SG_ 1066 View_RPC_APS_Sw_D_Qf 1;
BA_ "GenSigSendType" SG_ 1066 View_RPC_APS_Sw_B_Actl 1;
BA_ "GenSigSendType" SG_ 1066 HdcSw_D_Actl 1;
BA_ "GenSigStartValue" SG_ 1066 FirstRowBuckleDriver 1;
BA_ "GenSigSendType" SG_ 1066 FirstRowBuckleDriver 1;
BA_ "GenSigSendType" SG_ 1066 ID42A_E2E_CNTProfile2 1;
BA_ "GenSigSendType" SG_ 1066 ID42A_E2E_CRCProfile2 1;
BA_ "GenSigSendType" SG_ 1046 EBB_DisplayRequestB_ECB 3;
BA_ "GenSigSendType" SG_ 1046 EBB_DisplayRequestA_ECB 3;
BA_ "GenSigSendType" SG_ 1046 BrkCtlLamp_D_Rq_ECB 3;
BA_ "GenSigSendType" SG_ 1046 BrkLamp_B_Rq_ECB 3;
BA_ "GenSigSendType" SG_ 1045 Hdc_DisplayRequest_1 3;
BA_ "GenSigSendType" SG_ 1045 EPB_TrqRequire 3;
BA_ "GenSigSendType" SG_ 1045 EPB_IGoff_Apply_Inhibit 3;
BA_ "GenSigSendType" SG_ 1045 RGN_StpLmp_Fail_Flag 3;
BA_ "GenSigSendType" SG_ 1045 LDA_B_Falt 3;
BA_ "GenSigStartValue" SG_ 1045 BrkFluidLvl_D_Actl 3;
BA_ "GenSigSendType" SG_ 1045 BrkFluidLvl_D_Actl 3;
BA_ "GenSigSendType" SG_ 1045 DSC_OnOff_status 3;
BA_ "GenSigSendType" SG_ 1045 TCS_ENG_FAILD 3;
BA_ "GenSigSendType" SG_ 1045 TCS_BRK_FAILD 3;
BA_ "GenSigSendType" SG_ 1045 Dsc_B_Falt 3;
BA_ "GenSigSendType" SG_ 1045 EPB_Status 3;
BA_ "GenSigSendType" SG_ 1045 EPB_SwitchPosition 3;
BA_ "GenSigSendType" SG_ 1045 EPB_EnableExternalApply_TCM 3;
BA_ "GenSigSendType" SG_ 1045 EPB_EnableDecelRequest 3;
BA_ "GenSigSendType" SG_ 1045 EPB_EnableExternalApply_VCM 3;
BA_ "GenSigSendType" SG_ 1045 Hdc_ActLamp_D_Rq 3;
BA_ "GenSigInvalidValue" SG_ 1045 Hdc_Trgt_Veh_V 31;
BA_ "GenSigSendType" SG_ 1045 Hdc_Trgt_Veh_V 3;
BA_ "GenSigSendType" SG_ 1045 AutoHoldStdbyLamp_D_Rq 3;
BA_ "GenSigSendType" SG_ 1045 EPB_IGoff_Apply_Buzzer 3;
BA_ "GenSigSendType" SG_ 1045 EBB_DisplayRequestB 3;
BA_ "GenSigSendType" SG_ 1045 EBB_DisplayRequestA 3;
BA_ "GenSigSendType" SG_ 1045 EPB_DisplayRequest5 3;
BA_ "GenSigSendType" SG_ 1045 EPB_DisplayRequest4 3;
BA_ "GenSigSendType" SG_ 1045 EPB_DisplayRequest3 3;
BA_ "GenSigSendType" SG_ 1045 EPB_DisplayRequest2 3;
BA_ "GenSigSendType" SG_ 1045 EPB_DisplayRequest1 3;
BA_ "GenSigSendType" SG_ 1045 HydraulicHoldDis_B_Rq4 3;
BA_ "GenSigSendType" SG_ 1045 HydraulicHoldDis_B_Rq3 3;
BA_ "GenSigSendType" SG_ 1045 HydraulicHoldDis_B_Rq2 3;
BA_ "GenSigSendType" SG_ 1045 HydraulicHoldDis_B_Rq1 3;
BA_ "GenSigSendType" SG_ 1045 HydraulicHoldActLamp_D_Rq 3;
BA_ "GenSigSendType" SG_ 1045 DrvSlipCtlGuid_D_Rq 3;
BA_ "GenSigSendType" SG_ 1045 DrvAntiLckGuid_D_Rq 3;
BA_ "GenSigSendType" SG_ 1045 DrvEBDGuid_D_Rq 3;
BA_ "GenSigInvalidValue" SG_ 1044 BrkStkRatio 127;
BA_ "GenSigStartValue" SG_ 1044 PrkBrkActv_D_Actl 3;
BA_ "GenSigSendType" SG_ 1044 PrkBrkActv_D_Actl 3;
BA_ "GenSigSendType" SG_ 1044 DrvSlipCtlMde_D_Ind 3;
BA_ "GenSigSendType" SG_ 1044 DrvSlipCtlLamp_D_Rq 3;
BA_ "GenSigSendType" SG_ 1044 DrvAntiLckLamp_D_Rq 3;
BA_ "GenSigSendType" SG_ 1044 BrkCtlLamp_D_Rq 3;
BA_ "GenSigSendType" SG_ 1044 ParkBrkTelltale_B_Actl 3;
BA_ "GenSigSendType" SG_ 1044 BrkLamp_B_Rq 3;
BA_ "GenSigInvalidValue" SG_ 1034 Central_CRC 65535;
BA_ "GenSigStartValue" SG_ 1034 Central_CRC 65535;
BA_ "GenSigInvalidValue" SG_ 1034 CDID_Total_Number 255;
BA_ "GenSigStartValue" SG_ 1034 CDID_Total_Number 255;
BA_ "GenSigInvalidValue" SG_ 1034 Reserved_E0_2 65535;
BA_ "GenSigStartValue" SG_ 1034 Reserved_E0_2 65535;
BA_ "GenSigInvalidValue" SG_ 1034 Reserved_E0_1 65535;
BA_ "GenSigStartValue" SG_ 1034 Reserved_E0_1 65535;
BA_ "GenSigInvalidValue" SG_ 1034 Reserved_95_7 255;
BA_ "GenSigStartValue" SG_ 1034 Reserved_95_7 255;
BA_ "GenSigInvalidValue" SG_ 1034 Reserved_95_6 255;
BA_ "GenSigStartValue" SG_ 1034 Reserved_95_6 255;
BA_ "GenSigInvalidValue" SG_ 1034 Reserved_95_5 255;
BA_ "GenSigStartValue" SG_ 1034 Reserved_95_5 255;
BA_ "GenSigInvalidValue" SG_ 1034 Reserved_95_4 255;
BA_ "GenSigStartValue" SG_ 1034 Reserved_95_4 255;
BA_ "GenSigInvalidValue" SG_ 1034 Reserved_95_3 255;
BA_ "GenSigStartValue" SG_ 1034 Reserved_95_3 255;
BA_ "GenSigInvalidValue" SG_ 1034 Reserved_95_2 255;
BA_ "GenSigStartValue" SG_ 1034 Reserved_95_2 255;
BA_ "GenSigInvalidValue" SG_ 1034 Reserved_95_1 255;
BA_ "GenSigStartValue" SG_ 1034 Reserved_95_1 255;
BA_ "GenSigInvalidValue" SG_ 1034 Reserved_94_7 255;
BA_ "GenSigStartValue" SG_ 1034 Reserved_94_7 255;
BA_ "GenSigInvalidValue" SG_ 1034 Reserved_94_6 255;
BA_ "GenSigStartValue" SG_ 1034 Reserved_94_6 255;
BA_ "GenSigInvalidValue" SG_ 1034 Reserved_94_5 255;
BA_ "GenSigStartValue" SG_ 1034 Reserved_94_5 255;
BA_ "GenSigInvalidValue" SG_ 1034 Reserved_94_4 255;
BA_ "GenSigStartValue" SG_ 1034 Reserved_94_4 255;
BA_ "GenSigInvalidValue" SG_ 1034 Reserved_94_3 255;
BA_ "GenSigStartValue" SG_ 1034 Reserved_94_3 255;
BA_ "GenSigInvalidValue" SG_ 1034 Reserved_94_2 255;
BA_ "GenSigStartValue" SG_ 1034 Reserved_94_2 255;
BA_ "GenSigInvalidValue" SG_ 1034 Reserved_94_1 255;
BA_ "GenSigStartValue" SG_ 1034 Reserved_94_1 255;
BA_ "GenSigInvalidValue" SG_ 1034 Reserved_93_7 255;
BA_ "GenSigStartValue" SG_ 1034 Reserved_93_7 255;
BA_ "GenSigInvalidValue" SG_ 1034 Reserved_93_6 255;
BA_ "GenSigStartValue" SG_ 1034 Reserved_93_6 255;
BA_ "GenSigInvalidValue" SG_ 1034 Reserved_93_5 255;
BA_ "GenSigStartValue" SG_ 1034 Reserved_93_5 255;
BA_ "GenSigInvalidValue" SG_ 1034 Reserved_93_4 255;
BA_ "GenSigStartValue" SG_ 1034 Reserved_93_4 255;
BA_ "GenSigInvalidValue" SG_ 1034 Reserved_93_3 255;
BA_ "GenSigStartValue" SG_ 1034 Reserved_93_3 255;
BA_ "GenSigInvalidValue" SG_ 1034 Reserved_93_2 255;
BA_ "GenSigStartValue" SG_ 1034 Reserved_93_2 255;
BA_ "GenSigInvalidValue" SG_ 1034 Reserved_93_1 255;
BA_ "GenSigStartValue" SG_ 1034 Reserved_93_1 255;
BA_ "GenSigInvalidValue" SG_ 1034 Reserved_92_7 255;
BA_ "GenSigStartValue" SG_ 1034 Reserved_92_7 255;
BA_ "GenSigInvalidValue" SG_ 1034 Reserved_92_6 255;
BA_ "GenSigStartValue" SG_ 1034 Reserved_92_6 255;
BA_ "GenSigInvalidValue" SG_ 1034 Reserved_92_5 255;
BA_ "GenSigStartValue" SG_ 1034 Reserved_92_5 255;
BA_ "GenSigInvalidValue" SG_ 1034 Reserved_92_4 255;
BA_ "GenSigStartValue" SG_ 1034 Reserved_92_4 255;
BA_ "GenSigInvalidValue" SG_ 1034 Reserved_92_3 255;
BA_ "GenSigStartValue" SG_ 1034 Reserved_92_3 255;
BA_ "GenSigInvalidValue" SG_ 1034 Reserved_92_2 255;
BA_ "GenSigStartValue" SG_ 1034 Reserved_92_2 255;
BA_ "GenSigInvalidValue" SG_ 1034 Reserved_92_1 255;
BA_ "GenSigStartValue" SG_ 1034 Reserved_92_1 255;
BA_ "GenSigInvalidValue" SG_ 1034 Reserved_91_7 255;
BA_ "GenSigStartValue" SG_ 1034 Reserved_91_7 255;
BA_ "GenSigInvalidValue" SG_ 1034 Reserved_91_6 255;
BA_ "GenSigStartValue" SG_ 1034 Reserved_91_6 255;
BA_ "GenSigInvalidValue" SG_ 1034 Reserved_91_5 255;
BA_ "GenSigStartValue" SG_ 1034 Reserved_91_5 255;
BA_ "GenSigInvalidValue" SG_ 1034 Reserved_91_4 255;
BA_ "GenSigStartValue" SG_ 1034 Reserved_91_4 255;
BA_ "GenSigInvalidValue" SG_ 1034 Reserved_91_3 255;
BA_ "GenSigStartValue" SG_ 1034 Reserved_91_3 255;
BA_ "GenSigInvalidValue" SG_ 1034 Reserved_91_2 255;
BA_ "GenSigStartValue" SG_ 1034 Reserved_91_2 255;
BA_ "GenSigInvalidValue" SG_ 1034 Reserved_91_1 255;
BA_ "GenSigStartValue" SG_ 1034 Reserved_91_1 255;
BA_ "GenSigInvalidValue" SG_ 1034 Reserved_90_7 255;
BA_ "GenSigStartValue" SG_ 1034 Reserved_90_7 255;
BA_ "GenSigInvalidValue" SG_ 1034 Reserved_90_6 255;
BA_ "GenSigStartValue" SG_ 1034 Reserved_90_6 255;
BA_ "GenSigInvalidValue" SG_ 1034 Reserved_90_5 255;
BA_ "GenSigStartValue" SG_ 1034 Reserved_90_5 255;
BA_ "GenSigInvalidValue" SG_ 1034 Reserved_90_4 255;
BA_ "GenSigStartValue" SG_ 1034 Reserved_90_4 255;
BA_ "GenSigInvalidValue" SG_ 1034 Reserved_90_3 255;
BA_ "GenSigStartValue" SG_ 1034 Reserved_90_3 255;
BA_ "GenSigInvalidValue" SG_ 1034 Reserved_90_2 255;
BA_ "GenSigStartValue" SG_ 1034 Reserved_90_2 255;
BA_ "GenSigInvalidValue" SG_ 1034 Reserved_90_1 255;
BA_ "GenSigStartValue" SG_ 1034 Reserved_90_1 255;
BA_ "GenSigInvalidValue" SG_ 1034 Reserved_82_8 255;
BA_ "GenSigStartValue" SG_ 1034 Reserved_82_8 255;
BA_ "GenSigInvalidValue" SG_ 1034 Reserved_82_7 255;
BA_ "GenSigStartValue" SG_ 1034 Reserved_82_7 255;
BA_ "GenSigInvalidValue" SG_ 1034 ASE_SYSTEM 15;
BA_ "GenSigStartValue" SG_ 1034 ASE_SYSTEM 15;
BA_ "GenSigInvalidValue" SG_ 1034 WIRELESS_CHARGE 15;
BA_ "GenSigStartValue" SG_ 1034 WIRELESS_CHARGE 15;
BA_ "GenSigInvalidValue" SG_ 1034 FBUMPER_ASSY_TYPE 15;
BA_ "GenSigStartValue" SG_ 1034 FBUMPER_ASSY_TYPE 15;
BA_ "GenSigInvalidValue" SG_ 1034 FBUMPER_SHAPE_TYPE 15;
BA_ "GenSigStartValue" SG_ 1034 FBUMPER_SHAPE_TYPE 15;
BA_ "GenSigInvalidValue" SG_ 1034 EMERGENCY_DRIVER_ASSIST 15;
BA_ "GenSigStartValue" SG_ 1034 EMERGENCY_DRIVER_ASSIST 15;
BA_ "GenSigInvalidValue" SG_ 1034 VMC_COMMUNICATION_TYPE 15;
BA_ "GenSigStartValue" SG_ 1034 VMC_COMMUNICATION_TYPE 15;
BA_ "GenSigInvalidValue" SG_ 1034 VMC_POSITION 3;
BA_ "GenSigStartValue" SG_ 1034 VMC_POSITION 3;
BA_ "GenSigInvalidValue" SG_ 1034 Reserved_82_3 3;
BA_ "GenSigStartValue" SG_ 1034 Reserved_82_3 3;
BA_ "GenSigInvalidValue" SG_ 1034 INTERSECTION_BRAKE_SUPP 15;
BA_ "GenSigStartValue" SG_ 1034 INTERSECTION_BRAKE_SUPP 15;
BA_ "GenSigInvalidValue" SG_ 1034 PERSONALIZE_SYSTEM 15;
BA_ "GenSigStartValue" SG_ 1034 PERSONALIZE_SYSTEM 15;
BA_ "GenSigInvalidValue" SG_ 1034 TAP 15;
BA_ "GenSigStartValue" SG_ 1034 TAP 15;
BA_ "GenSigInvalidValue" SG_ 1034 Reserved_80_5 255;
BA_ "GenSigStartValue" SG_ 1034 Reserved_80_5 255;
BA_ "GenSigInvalidValue" SG_ 1034 Number_Of_Cylinders 15;
BA_ "GenSigStartValue" SG_ 1034 Number_Of_Cylinders 15;
BA_ "GenSigInvalidValue" SG_ 1034 TURBO_ENGINE 15;
BA_ "GenSigStartValue" SG_ 1034 TURBO_ENGINE 15;
BA_ "GenSigInvalidValue" SG_ 1034 CYLINDER_DEACTIVATION 15;
BA_ "GenSigStartValue" SG_ 1034 CYLINDER_DEACTIVATION 15;
BA_ "GenSigInvalidValue" SG_ 1034 UPGRADE_ENGINE 15;
BA_ "GenSigStartValue" SG_ 1034 UPGRADE_ENGINE 15;
BA_ "GenSigInvalidValue" SG_ 1034 ENGINE_TYPE 255;
BA_ "GenSigStartValue" SG_ 1034 ENGINE_TYPE 255;
BA_ "GenSigInvalidValue" SG_ 1034 Reserved_80_3 255;
BA_ "GenSigStartValue" SG_ 1034 Reserved_80_3 255;
BA_ "GenSigInvalidValue" SG_ 1034 Reserved_80_2 15;
BA_ "GenSigStartValue" SG_ 1034 Reserved_80_2 15;
BA_ "GenSigInvalidValue" SG_ 1034 AUX_POWER_UNIT 15;
BA_ "GenSigStartValue" SG_ 1034 AUX_POWER_UNIT 15;
BA_ "GenSigInvalidValue" SG_ 1034 Reserved_80_1 15;
BA_ "GenSigStartValue" SG_ 1034 Reserved_80_1 15;
BA_ "GenSigInvalidValue" SG_ 1034 XEV_TYPE 15;
BA_ "GenSigStartValue" SG_ 1034 XEV_TYPE 15;
BA_ "GenSigInvalidValue" SG_ 1034 Reserved_72_4 3;
BA_ "GenSigStartValue" SG_ 1034 Reserved_72_4 3;
BA_ "GenSigInvalidValue" SG_ 1034 REMOTE_ENGINE_START_OPT 3;
BA_ "GenSigStartValue" SG_ 1034 REMOTE_ENGINE_START_OPT 3;
BA_ "GenSigInvalidValue" SG_ 1034 DOWN_LIGHT 3;
BA_ "GenSigStartValue" SG_ 1034 DOWN_LIGHT 3;
BA_ "GenSigInvalidValue" SG_ 1034 KEYLESS_WINDOW_CONTROL 3;
BA_ "GenSigStartValue" SG_ 1034 KEYLESS_WINDOW_CONTROL 3;
BA_ "GenSigInvalidValue" SG_ 1034 KEY_LESS_COMPT 3;
BA_ "GenSigStartValue" SG_ 1034 KEY_LESS_COMPT 3;
BA_ "GenSigInvalidValue" SG_ 1034 SMART_KEYLESS 3;
BA_ "GenSigStartValue" SG_ 1034 SMART_KEYLESS 3;
BA_ "GenSigInvalidValue" SG_ 1034 KEY_LESS_ENTRY 15;
BA_ "GenSigStartValue" SG_ 1034 KEY_LESS_ENTRY 15;
BA_ "GenSigInvalidValue" SG_ 1034 Reserved_72_2 255;
BA_ "GenSigStartValue" SG_ 1034 Reserved_72_2 255;
BA_ "GenSigInvalidValue" SG_ 1034 REMINDER_CONTROL_SPEC 255;
BA_ "GenSigStartValue" SG_ 1034 REMINDER_CONTROL_SPEC 255;
BA_ "GenSigInvalidValue" SG_ 1034 SEAT_BELT_WARNING_SYSTEM 15;
BA_ "GenSigStartValue" SG_ 1034 SEAT_BELT_WARNING_SYSTEM 15;
BA_ "GenSigInvalidValue" SG_ 1034 OCCUPANT_SENSING_SYSTEM 15;
BA_ "GenSigStartValue" SG_ 1034 OCCUPANT_SENSING_SYSTEM 15;
BA_ "GenSigInvalidValue" SG_ 1034 Reserved_70_4 255;
BA_ "GenSigStartValue" SG_ 1034 Reserved_70_4 255;
BA_ "GenSigInvalidValue" SG_ 1034 R_SEAT_NO2_TYPE 15;
BA_ "GenSigStartValue" SG_ 1034 R_SEAT_NO2_TYPE 15;
BA_ "GenSigInvalidValue" SG_ 1034 R_SEAT_NO1_TYPE 15;
BA_ "GenSigStartValue" SG_ 1034 R_SEAT_NO1_TYPE 15;
BA_ "GenSigInvalidValue" SG_ 1034 EXTERIOR_ALERT_TYPE 15;
BA_ "GenSigStartValue" SG_ 1034 EXTERIOR_ALERT_TYPE 15;
BA_ "GenSigInvalidValue" SG_ 1034 CPD_CONTROL_TYPE 15;
BA_ "GenSigStartValue" SG_ 1034 CPD_CONTROL_TYPE 15;
BA_ "GenSigInvalidValue" SG_ 1034 Reserved_70_3 3;
BA_ "GenSigStartValue" SG_ 1034 Reserved_70_3 3;
BA_ "GenSigInvalidValue" SG_ 1034 F_SEAT_VENTILATION 3;
BA_ "GenSigStartValue" SG_ 1034 F_SEAT_VENTILATION 3;
BA_ "GenSigInvalidValue" SG_ 1034 F_SEAT_TYPE 15;
BA_ "GenSigStartValue" SG_ 1034 F_SEAT_TYPE 15;
BA_ "GenSigInvalidValue" SG_ 1034 Reserved_70_2 3;
BA_ "GenSigStartValue" SG_ 1034 Reserved_70_2 3;
BA_ "GenSigInvalidValue" SG_ 1034 R_SEAT_WARMER 3;
BA_ "GenSigStartValue" SG_ 1034 R_SEAT_WARMER 3;
BA_ "GenSigInvalidValue" SG_ 1034 F_SEAT_WARMER 15;
BA_ "GenSigStartValue" SG_ 1034 F_SEAT_WARMER 15;
BA_ "GenSigInvalidValue" SG_ 1034 Reserved_70_1 15;
BA_ "GenSigStartValue" SG_ 1034 Reserved_70_1 15;
BA_ "GenSigInvalidValue" SG_ 1034 F_SEAT_LIFT_MECHANISM 15;
BA_ "GenSigStartValue" SG_ 1034 F_SEAT_LIFT_MECHANISM 15;
BA_ "GenSigInvalidValue" SG_ 1034 SEAT_MATERIAL 255;
BA_ "GenSigStartValue" SG_ 1034 SEAT_MATERIAL 255;
BA_ "GenSigInvalidValue" SG_ 1034 Reserved_63_1 255;
BA_ "GenSigStartValue" SG_ 1034 Reserved_63_1 255;
BA_ "GenSigInvalidValue" SG_ 1034 Vehicle_Height 65535;
BA_ "GenSigStartValue" SG_ 1034 Vehicle_Height 65535;
BA_ "GenSigInvalidValue" SG_ 1034 Vehicle_Width 65535;
BA_ "GenSigStartValue" SG_ 1034 Vehicle_Width 65535;
BA_ "GenSigInvalidValue" SG_ 1034 Vehicle_Length 65535;
BA_ "GenSigStartValue" SG_ 1034 Vehicle_Length 65535;
BA_ "GenSigInvalidValue" SG_ 1034 Reserved_62_2 3;
BA_ "GenSigStartValue" SG_ 1034 Reserved_62_2 3;
BA_ "GenSigInvalidValue" SG_ 1034 TOUCH_PANEL 3;
BA_ "GenSigStartValue" SG_ 1034 TOUCH_PANEL 3;
BA_ "GenSigInvalidValue" SG_ 1034 DISPLAY_SIZE 15;
BA_ "GenSigStartValue" SG_ 1034 DISPLAY_SIZE 15;
BA_ "GenSigInvalidValue" SG_ 1034 HD_Radio 3;
BA_ "GenSigStartValue" SG_ 1034 HD_Radio 3;
BA_ "GenSigInvalidValue" SG_ 1034 TELEMATICS_COM_UNIT 3;
BA_ "GenSigStartValue" SG_ 1034 TELEMATICS_COM_UNIT 3;
BA_ "GenSigInvalidValue" SG_ 1034 B_CALL 255;
BA_ "GenSigStartValue" SG_ 1034 B_CALL 255;
BA_ "GenSigInvalidValue" SG_ 1034 CMU_Spec 15;
BA_ "GenSigStartValue" SG_ 1034 CMU_Spec 15;
BA_ "GenSigInvalidValue" SG_ 1034 Number_Of_Seat_Rows 3;
BA_ "GenSigStartValue" SG_ 1034 Number_Of_Seat_Rows 3;
BA_ "GenSigInvalidValue" SG_ 1034 Tuner_AM_Range 3;
BA_ "GenSigStartValue" SG_ 1034 Tuner_AM_Range 3;
BA_ "GenSigInvalidValue" SG_ 1034 Pandora 3;
BA_ "GenSigStartValue" SG_ 1034 Pandora 3;
BA_ "GenSigInvalidValue" SG_ 1034 Mobile_911 3;
BA_ "GenSigStartValue" SG_ 1034 Mobile_911 3;
BA_ "GenSigInvalidValue" SG_ 1034 HDMI 3;
BA_ "GenSigStartValue" SG_ 1034 HDMI 3;
BA_ "GenSigInvalidValue" SG_ 1034 LW 3;
BA_ "GenSigStartValue" SG_ 1034 LW 3;
BA_ "GenSigInvalidValue" SG_ 1034 Limit_Of_DAB_Range 15;
BA_ "GenSigStartValue" SG_ 1034 Limit_Of_DAB_Range 15;
BA_ "GenSigInvalidValue" SG_ 1034 ELK_CUSTOMIZE_TYPE 3;
BA_ "GenSigStartValue" SG_ 1034 ELK_CUSTOMIZE_TYPE 3;
BA_ "GenSigInvalidValue" SG_ 1034 Microphone 3;
BA_ "GenSigStartValue" SG_ 1034 Microphone 3;
BA_ "GenSigInvalidValue" SG_ 1034 DAA_Default 3;
BA_ "GenSigStartValue" SG_ 1034 DAA_Default 3;
BA_ "GenSigInvalidValue" SG_ 1034 Carplay 3;
BA_ "GenSigStartValue" SG_ 1034 Carplay 3;
BA_ "GenSigInvalidValue" SG_ 1034 Android_Auto 3;
BA_ "GenSigStartValue" SG_ 1034 Android_Auto 3;
BA_ "GenSigInvalidValue" SG_ 1034 Wi_Fi_Frequency 3;
BA_ "GenSigStartValue" SG_ 1034 Wi_Fi_Frequency 3;
BA_ "GenSigInvalidValue" SG_ 1034 Commander_Touchpad 3;
BA_ "GenSigStartValue" SG_ 1034 Commander_Touchpad 3;
BA_ "GenSigInvalidValue" SG_ 1034 TPEG 3;
BA_ "GenSigStartValue" SG_ 1034 TPEG 3;
BA_ "GenSigInvalidValue" SG_ 1034 Reserved_60_1 16777215;
BA_ "GenSigStartValue" SG_ 1034 Reserved_60_1 16777215;
BA_ "GenSigInvalidValue" SG_ 1034 EMERGENCY_CALL 15;
BA_ "GenSigStartValue" SG_ 1034 EMERGENCY_CALL 15;
BA_ "GenSigInvalidValue" SG_ 1034 SATELITE_SPEC 15;
BA_ "GenSigStartValue" SG_ 1034 SATELITE_SPEC 15;
BA_ "GenSigInvalidValue" SG_ 1034 NAVI_MAP_DATA 15;
BA_ "GenSigStartValue" SG_ 1034 NAVI_MAP_DATA 15;
BA_ "GenSigInvalidValue" SG_ 1034 CD_Ripping 3;
BA_ "GenSigStartValue" SG_ 1034 CD_Ripping 3;
BA_ "GenSigInvalidValue" SG_ 1034 TV_TUNER 3;
BA_ "GenSigStartValue" SG_ 1034 TV_TUNER 3;
BA_ "GenSigInvalidValue" SG_ 1034 SPEAKER_TYPE 15;
BA_ "GenSigStartValue" SG_ 1034 SPEAKER_TYPE 15;
BA_ "GenSigInvalidValue" SG_ 1034 DVD 3;
BA_ "GenSigStartValue" SG_ 1034 DVD 3;
BA_ "GenSigInvalidValue" SG_ 1034 CD 3;
BA_ "GenSigStartValue" SG_ 1034 CD 3;
BA_ "GenSigInvalidValue" SG_ 1034 FREQUENCY 15;
BA_ "GenSigStartValue" SG_ 1034 FREQUENCY 15;
BA_ "GenSigInvalidValue" SG_ 1034 RDS 3;
BA_ "GenSigStartValue" SG_ 1034 RDS 3;
BA_ "GenSigInvalidValue" SG_ 1034 DAB 3;
BA_ "GenSigStartValue" SG_ 1034 DAB 3;
BA_ "GenSigInvalidValue" SG_ 1034 Reserved_52_6 255;
BA_ "GenSigStartValue" SG_ 1034 Reserved_52_6 255;
BA_ "GenSigInvalidValue" SG_ 1034 AT_SHIFT_SW 15;
BA_ "GenSigStartValue" SG_ 1034 AT_SHIFT_SW 15;
BA_ "GenSigInvalidValue" SG_ 1034 ELECTRIC_SHIFT 15;
BA_ "GenSigStartValue" SG_ 1034 ELECTRIC_SHIFT 15;
BA_ "GenSigInvalidValue" SG_ 1034 Reserved_52_5 3;
BA_ "GenSigStartValue" SG_ 1034 Reserved_52_5 3;
BA_ "GenSigInvalidValue" SG_ 1034 STG_WHEEL_WARMER 3;
BA_ "GenSigStartValue" SG_ 1034 STG_WHEEL_WARMER 3;
BA_ "GenSigInvalidValue" SG_ 1034 TILT_STG 15;
BA_ "GenSigStartValue" SG_ 1034 TILT_STG 15;
BA_ "GenSigInvalidValue" SG_ 1034 Reserved_52_4 255;
BA_ "GenSigStartValue" SG_ 1034 Reserved_52_4 255;
BA_ "GenSigInvalidValue" SG_ 1034 DRIVE_SELECTION_MODE 15;
BA_ "GenSigStartValue" SG_ 1034 DRIVE_SELECTION_MODE 15;
BA_ "GenSigInvalidValue" SG_ 1034 Reserved_52_3 3;
BA_ "GenSigStartValue" SG_ 1034 Reserved_52_3 3;
BA_ "GenSigInvalidValue" SG_ 1034 DRIVE_SELECTION 3;
BA_ "GenSigStartValue" SG_ 1034 DRIVE_SELECTION 3;
BA_ "GenSigInvalidValue" SG_ 1034 I_DM 3;
BA_ "GenSigStartValue" SG_ 1034 I_DM 3;
BA_ "GenSigInvalidValue" SG_ 1034 Reserved_52_2 3;
BA_ "GenSigStartValue" SG_ 1034 Reserved_52_2 3;
BA_ "GenSigInvalidValue" SG_ 1034 OVER_HEAD_CONSOLE 15;
BA_ "GenSigStartValue" SG_ 1034 OVER_HEAD_CONSOLE 15;
BA_ "GenSigInvalidValue" SG_ 1034 AT_INTERLOCK_UNLOCK_SYS 15;
BA_ "GenSigStartValue" SG_ 1034 AT_INTERLOCK_UNLOCK_SYS 15;
BA_ "GenSigInvalidValue" SG_ 1034 BURGLAR_ALARM_SYSTEM 15;
BA_ "GenSigStartValue" SG_ 1034 BURGLAR_ALARM_SYSTEM 15;
BA_ "GenSigInvalidValue" SG_ 1034 Reserved_50_3 16777215;
BA_ "GenSigStartValue" SG_ 1034 Reserved_50_3 16777215;
BA_ "GenSigInvalidValue" SG_ 1034 TSR_GSR_TYPE 15;
BA_ "GenSigStartValue" SG_ 1034 TSR_GSR_TYPE 15;
BA_ "GenSigInvalidValue" SG_ 1034 SPEED_METER 15;
BA_ "GenSigStartValue" SG_ 1034 SPEED_METER 15;
BA_ "GenSigInvalidValue" SG_ 1034 FUEL_CONSUMPTION_UNIT 15;
BA_ "GenSigStartValue" SG_ 1034 FUEL_CONSUMPTION_UNIT 15;
BA_ "GenSigInvalidValue" SG_ 1034 TRIP_COMPUTER 15;
BA_ "GenSigStartValue" SG_ 1034 TRIP_COMPUTER 15;
BA_ "GenSigInvalidValue" SG_ 1034 HEAD_UP_DISPLAY 3;
BA_ "GenSigStartValue" SG_ 1034 HEAD_UP_DISPLAY 3;
BA_ "GenSigInvalidValue" SG_ 1034 WARNING_BUZZER_120KMH 3;
BA_ "GenSigStartValue" SG_ 1034 WARNING_BUZZER_120KMH 3;
BA_ "GenSigInvalidValue" SG_ 1034 TURN_SIGNAL_SWITCH 3;
BA_ "GenSigStartValue" SG_ 1034 TURN_SIGNAL_SWITCH 3;
BA_ "GenSigInvalidValue" SG_ 1034 Reserved_50_1 3;
BA_ "GenSigStartValue" SG_ 1034 Reserved_50_1 3;
BA_ "GenSigInvalidValue" SG_ 1034 MULTI_DOT_DISPLAY 3;
BA_ "GenSigStartValue" SG_ 1034 MULTI_DOT_DISPLAY 3;
BA_ "GenSigInvalidValue" SG_ 1034 Reserved_50_4 3;
BA_ "GenSigStartValue" SG_ 1034 Reserved_50_4 3;
BA_ "GenSigInvalidValue" SG_ 1034 IND_STD_OF_SPEED_METER 15;
BA_ "GenSigStartValue" SG_ 1034 IND_STD_OF_SPEED_METER 15;
BA_ "GenSigInvalidValue" SG_ 1034 F_EX_MIRROR_AUTO_FOLD 3;
BA_ "GenSigStartValue" SG_ 1034 F_EX_MIRROR_AUTO_FOLD 3;
BA_ "GenSigInvalidValue" SG_ 1034 F_EXT_MIRROR_ADJ_MEMORY 3;
BA_ "GenSigStartValue" SG_ 1034 F_EXT_MIRROR_ADJ_MEMORY 3;
BA_ "GenSigInvalidValue" SG_ 1034 F_EXT_MIRROR_HEATER 3;
BA_ "GenSigStartValue" SG_ 1034 F_EXT_MIRROR_HEATER 3;
BA_ "GenSigInvalidValue" SG_ 1034 F_EX_MIRROR_POWER_FOLD 3;
BA_ "GenSigStartValue" SG_ 1034 F_EX_MIRROR_POWER_FOLD 3;
BA_ "GenSigInvalidValue" SG_ 1034 Reserved_40_3 1048575;
BA_ "GenSigStartValue" SG_ 1034 Reserved_40_3 1048575;
BA_ "GenSigInvalidValue" SG_ 1034 ONE_TOUCH_SYSTEM 15;
BA_ "GenSigStartValue" SG_ 1034 ONE_TOUCH_SYSTEM 15;
BA_ "GenSigInvalidValue" SG_ 1034 Reserved_40_2 3;
BA_ "GenSigStartValue" SG_ 1034 Reserved_40_2 3;
BA_ "GenSigInvalidValue" SG_ 1034 WASHER_LEVEL_LAMP 3;
BA_ "GenSigStartValue" SG_ 1034 WASHER_LEVEL_LAMP 3;
BA_ "GenSigInvalidValue" SG_ 1034 F_WIPER_INTERMITTENT 15;
BA_ "GenSigStartValue" SG_ 1034 F_WIPER_INTERMITTENT 15;
BA_ "GenSigInvalidValue" SG_ 1034 Reserved_30_6 255;
BA_ "GenSigStartValue" SG_ 1034 Reserved_30_6 255;
BA_ "GenSigInvalidValue" SG_ 1034 AUTO_DOOR_LOCK 15;
BA_ "GenSigStartValue" SG_ 1034 AUTO_DOOR_LOCK 15;
BA_ "GenSigInvalidValue" SG_ 1034 Reserved_30_5 3;
BA_ "GenSigStartValue" SG_ 1034 Reserved_30_5 3;
BA_ "GenSigInvalidValue" SG_ 1034 SUPER_LOCK_SYSTEM 3;
BA_ "GenSigStartValue" SG_ 1034 SUPER_LOCK_SYSTEM 3;
BA_ "GenSigInvalidValue" SG_ 1034 POWER_DOOR_LOCK_SW 15;
BA_ "GenSigStartValue" SG_ 1034 POWER_DOOR_LOCK_SW 15;
BA_ "GenSigInvalidValue" SG_ 1034 POWER_DOOR_LOCK 15;
BA_ "GenSigStartValue" SG_ 1034 POWER_DOOR_LOCK 15;
BA_ "GenSigInvalidValue" SG_ 1034 Reserved_30_4 255;
BA_ "GenSigStartValue" SG_ 1034 Reserved_30_4 255;
BA_ "GenSigInvalidValue" SG_ 1034 Reserved_30_3 63;
BA_ "GenSigStartValue" SG_ 1034 Reserved_30_3 63;
BA_ "GenSigInvalidValue" SG_ 1034 POWER_BACK_DOOR 3;
BA_ "GenSigStartValue" SG_ 1034 POWER_BACK_DOOR 3;
BA_ "GenSigInvalidValue" SG_ 1034 Reserved_30_2 255;
BA_ "GenSigStartValue" SG_ 1034 Reserved_30_2 255;
BA_ "GenSigInvalidValue" SG_ 1034 Reserved_30_1 15;
BA_ "GenSigStartValue" SG_ 1034 Reserved_30_1 15;
BA_ "GenSigInvalidValue" SG_ 1034 TRUNK_LID_OPENER 15;
BA_ "GenSigStartValue" SG_ 1034 TRUNK_LID_OPENER 15;
BA_ "GenSigInvalidValue" SG_ 1034 Reserved_25_4 16777215;
BA_ "GenSigStartValue" SG_ 1034 Reserved_25_4 16777215;
BA_ "GenSigInvalidValue" SG_ 1034 DEFAULT_ONE_TOUCH_TURN 3;
BA_ "GenSigStartValue" SG_ 1034 DEFAULT_ONE_TOUCH_TURN 3;
BA_ "GenSigInvalidValue" SG_ 1034 ESS 3;
BA_ "GenSigStartValue" SG_ 1034 ESS 3;
BA_ "GenSigInvalidValue" SG_ 1034 R_FOG_LAMP 3;
BA_ "GenSigStartValue" SG_ 1034 R_FOG_LAMP 3;
BA_ "GenSigInvalidValue" SG_ 1034 F_FOG_LAMP 3;
BA_ "GenSigStartValue" SG_ 1034 F_FOG_LAMP 3;
BA_ "GenSigInvalidValue" SG_ 1034 Reserved_25_3 15;
BA_ "GenSigStartValue" SG_ 1034 Reserved_25_3 15;
BA_ "GenSigInvalidValue" SG_ 1034 PASSIVE_COLLISION_SIGNAL 15;
BA_ "GenSigStartValue" SG_ 1034 PASSIVE_COLLISION_SIGNAL 15;
BA_ "GenSigInvalidValue" SG_ 1034 F_AND_R_SIDE_MARKER_US 3;
BA_ "GenSigStartValue" SG_ 1034 F_AND_R_SIDE_MARKER_US 3;
BA_ "GenSigInvalidValue" SG_ 1034 AUTO_HEAD_LAMP_ON_OFF 3;
BA_ "GenSigStartValue" SG_ 1034 AUTO_HEAD_LAMP_ON_OFF 3;
BA_ "GenSigInvalidValue" SG_ 1034 RUNNING_LAMP_CUSTOMIZE 15;
BA_ "GenSigStartValue" SG_ 1034 RUNNING_LAMP_CUSTOMIZE 15;
BA_ "GenSigInvalidValue" SG_ 1034 F_COMBI_SIGNATURE_ILLUMI 3;
BA_ "GenSigStartValue" SG_ 1034 F_COMBI_SIGNATURE_ILLUMI 3;
BA_ "GenSigInvalidValue" SG_ 1034 HEAD_LAMP_CLEANER 3;
BA_ "GenSigStartValue" SG_ 1034 HEAD_LAMP_CLEANER 3;
BA_ "GenSigInvalidValue" SG_ 1034 Headlamp_Control 15;
BA_ "GenSigStartValue" SG_ 1034 Headlamp_Control 15;
BA_ "GenSigInvalidValue" SG_ 1034 AC_Refrigerant_Gas 15;
BA_ "GenSigStartValue" SG_ 1034 AC_Refrigerant_Gas 15;
BA_ "GenSigInvalidValue" SG_ 1034 AC_Compressor 15;
BA_ "GenSigStartValue" SG_ 1034 AC_Compressor 15;
BA_ "GenSigInvalidValue" SG_ 1034 Reserved_20_1 3;
BA_ "GenSigStartValue" SG_ 1034 Reserved_20_1 3;
BA_ "GenSigInvalidValue" SG_ 1034 PreAirCon_OperatingTime 15;
BA_ "GenSigStartValue" SG_ 1034 PreAirCon_OperatingTime 15;
BA_ "GenSigInvalidValue" SG_ 1034 R_VENT_COOLER 3;
BA_ "GenSigStartValue" SG_ 1034 R_VENT_COOLER 3;
BA_ "GenSigInvalidValue" SG_ 1034 HUMIDITY_SENSOR 3;
BA_ "GenSigStartValue" SG_ 1034 HUMIDITY_SENSOR 3;
BA_ "GenSigInvalidValue" SG_ 1034 PTC_HEATER 3;
BA_ "GenSigStartValue" SG_ 1034 PTC_HEATER 3;
BA_ "GenSigInvalidValue" SG_ 1034 F_AIR_CONDITIONER 15;
BA_ "GenSigStartValue" SG_ 1034 F_AIR_CONDITIONER 15;
BA_ "GenSigInvalidValue" SG_ 1034 Reserved_16_3 16777215;
BA_ "GenSigStartValue" SG_ 1034 Reserved_16_3 16777215;
BA_ "GenSigInvalidValue" SG_ 1034 Reserved_16_2 15;
BA_ "GenSigStartValue" SG_ 1034 Reserved_16_2 15;
BA_ "GenSigInvalidValue" SG_ 1034 OCCUPANT_MONITOR_SYSTEM 3;
BA_ "GenSigStartValue" SG_ 1034 OCCUPANT_MONITOR_SYSTEM 3;
BA_ "GenSigInvalidValue" SG_ 1034 FRONT_SIDE_RADAR 3;
BA_ "GenSigStartValue" SG_ 1034 FRONT_SIDE_RADAR 3;
BA_ "GenSigInvalidValue" SG_ 1034 TJA_TYPE 15;
BA_ "GenSigStartValue" SG_ 1034 TJA_TYPE 15;
BA_ "GenSigInvalidValue" SG_ 1034 VIEW_MONITOR_CAMERA 15;
BA_ "GenSigStartValue" SG_ 1034 VIEW_MONITOR_CAMERA 15;
BA_ "GenSigInvalidValue" SG_ 1034 FRONT_REAR_SIDE_SONAR 15;
BA_ "GenSigStartValue" SG_ 1034 FRONT_REAR_SIDE_SONAR 15;
BA_ "GenSigInvalidValue" SG_ 1034 DRIVER_MONITOR 3;
BA_ "GenSigStartValue" SG_ 1034 DRIVER_MONITOR 3;
BA_ "GenSigInvalidValue" SG_ 1034 FRONT_CROSS_TRAFFIC_ALERT 3;
BA_ "GenSigStartValue" SG_ 1034 FRONT_CROSS_TRAFFIC_ALERT 3;
BA_ "GenSigInvalidValue" SG_ 1034 INTERSECTION_BRAKE_TYPE 15;
BA_ "GenSigStartValue" SG_ 1034 INTERSECTION_BRAKE_TYPE 15;
BA_ "GenSigInvalidValue" SG_ 1034 BLIND_SPOT_PREVENTION 3;
BA_ "GenSigStartValue" SG_ 1034 BLIND_SPOT_PREVENTION 3;
BA_ "GenSigInvalidValue" SG_ 1034 Reserved_16_1 3;
BA_ "GenSigStartValue" SG_ 1034 Reserved_16_1 3;
BA_ "GenSigInvalidValue" SG_ 1034 Reserved_15_3 16777215;
BA_ "GenSigStartValue" SG_ 1034 Reserved_15_3 16777215;
BA_ "GenSigInvalidValue" SG_ 1034 SBS_VRU_TYPE 15;
BA_ "GenSigStartValue" SG_ 1034 SBS_VRU_TYPE 15;
BA_ "GenSigInvalidValue" SG_ 1034 ADAS_REGULATION_TYPE 15;
BA_ "GenSigStartValue" SG_ 1034 ADAS_REGULATION_TYPE 15;
BA_ "GenSigInvalidValue" SG_ 1034 REMOTE_PARKING 3;
BA_ "GenSigStartValue" SG_ 1034 REMOTE_PARKING 3;
BA_ "GenSigInvalidValue" SG_ 1034 AUTO_PARKING 3;
BA_ "GenSigStartValue" SG_ 1034 AUTO_PARKING 3;
BA_ "GenSigInvalidValue" SG_ 1034 ACCELERATION_RESTRAINT 15;
BA_ "GenSigStartValue" SG_ 1034 ACCELERATION_RESTRAINT 15;
BA_ "GenSigInvalidValue" SG_ 1034 REAR_SONAR 15;
BA_ "GenSigStartValue" SG_ 1034 REAR_SONAR 15;
BA_ "GenSigInvalidValue" SG_ 1034 FRONT_SONAR 15;
BA_ "GenSigStartValue" SG_ 1034 FRONT_SONAR 15;
BA_ "GenSigInvalidValue" SG_ 1034 PARKING_SENSOR 15;
BA_ "GenSigStartValue" SG_ 1034 PARKING_SENSOR 15;
BA_ "GenSigInvalidValue" SG_ 1034 REAR_DIRECTION_BASE_SAFETY 15;
BA_ "GenSigStartValue" SG_ 1034 REAR_DIRECTION_BASE_SAFETY 15;
BA_ "GenSigInvalidValue" SG_ 1034 Reserved_14_2 15;
BA_ "GenSigStartValue" SG_ 1034 Reserved_14_2 15;
BA_ "GenSigInvalidValue" SG_ 1034 SBS_TARGET_TYPE 15;
BA_ "GenSigStartValue" SG_ 1034 SBS_TARGET_TYPE 15;
BA_ "GenSigInvalidValue" SG_ 1034 IACC_TYPE 15;
BA_ "GenSigStartValue" SG_ 1034 IACC_TYPE 15;
BA_ "GenSigInvalidValue" SG_ 1034 HEAD_ON 15;
BA_ "GenSigStartValue" SG_ 1034 HEAD_ON 15;
BA_ "GenSigInvalidValue" SG_ 1034 LAS_TYPE 15;
BA_ "GenSigStartValue" SG_ 1034 LAS_TYPE 15;
BA_ "GenSigInvalidValue" SG_ 1034 MRCC_TYPE 15;
BA_ "GenSigStartValue" SG_ 1034 MRCC_TYPE 15;
BA_ "GenSigInvalidValue" SG_ 1034 Reserved_14_1 3;
BA_ "GenSigStartValue" SG_ 1034 Reserved_14_1 3;
BA_ "GenSigInvalidValue" SG_ 1034 BLIND_SPOT_MONITORING 3;
BA_ "GenSigStartValue" SG_ 1034 BLIND_SPOT_MONITORING 3;
BA_ "GenSigInvalidValue" SG_ 1034 REAR_SIDE_RADAR 3;
BA_ "GenSigStartValue" SG_ 1034 REAR_SIDE_RADAR 3;
BA_ "GenSigInvalidValue" SG_ 1034 FRONT_RADAR 3;
BA_ "GenSigStartValue" SG_ 1034 FRONT_RADAR 3;
BA_ "GenSigInvalidValue" SG_ 1034 ADJUSTABLE_SPEED_LIMITER 15;
BA_ "GenSigStartValue" SG_ 1034 ADJUSTABLE_SPEED_LIMITER 15;
BA_ "GenSigInvalidValue" SG_ 1034 AUTO_CRUISER 15;
BA_ "GenSigStartValue" SG_ 1034 AUTO_CRUISER 15;
BA_ "GenSigInvalidValue" SG_ 1034 DAS_TYPE 15;
BA_ "GenSigStartValue" SG_ 1034 DAS_TYPE 15;
BA_ "GenSigInvalidValue" SG_ 1034 DRIVER_ATTENTION_ALERT 3;
BA_ "GenSigStartValue" SG_ 1034 DRIVER_ATTENTION_ALERT 3;
BA_ "GenSigInvalidValue" SG_ 1034 TRAFFIC_SIGN_RECOGNITION 3;
BA_ "GenSigStartValue" SG_ 1034 TRAFFIC_SIGN_RECOGNITION 3;
BA_ "GenSigInvalidValue" SG_ 1034 FRONT_DIRECTION_BASE_SAFETY 15;
BA_ "GenSigStartValue" SG_ 1034 FRONT_DIRECTION_BASE_SAFETY 15;
BA_ "GenSigInvalidValue" SG_ 1034 HIGH_BEAM_CONTROL 3;
BA_ "GenSigStartValue" SG_ 1034 HIGH_BEAM_CONTROL 3;
BA_ "GenSigInvalidValue" SG_ 1034 FORWARD_SENSING_CAMERA 3;
BA_ "GenSigStartValue" SG_ 1034 FORWARD_SENSING_CAMERA 3;
BA_ "GenSigInvalidValue" SG_ 1034 Reserved_13_3 16777215;
BA_ "GenSigStartValue" SG_ 1034 Reserved_13_3 16777215;
BA_ "GenSigInvalidValue" SG_ 1034 Reserved_13_2 255;
BA_ "GenSigStartValue" SG_ 1034 Reserved_13_2 255;
BA_ "GenSigInvalidValue" SG_ 1034 Reserved_13_1 15;
BA_ "GenSigStartValue" SG_ 1034 Reserved_13_1 15;
BA_ "GenSigInvalidValue" SG_ 1034 F_TIRE_SIZE 15;
BA_ "GenSigStartValue" SG_ 1034 F_TIRE_SIZE 15;
BA_ "GenSigInvalidValue" SG_ 1034 EPS_Assist_Map 255;
BA_ "GenSigStartValue" SG_ 1034 EPS_Assist_Map 255;
BA_ "GenSigInvalidValue" SG_ 1034 Booster_Failure_Support 3;
BA_ "GenSigStartValue" SG_ 1034 Booster_Failure_Support 3;
BA_ "GenSigInvalidValue" SG_ 1034 DYC 3;
BA_ "GenSigStartValue" SG_ 1034 DYC 3;
BA_ "GenSigInvalidValue" SG_ 1034 Brake_Pad_Material 15;
BA_ "GenSigStartValue" SG_ 1034 Brake_Pad_Material 15;
BA_ "GenSigInvalidValue" SG_ 1034 Rear_Brake_Size 15;
BA_ "GenSigStartValue" SG_ 1034 Rear_Brake_Size 15;
BA_ "GenSigInvalidValue" SG_ 1034 Front_Brake_Size 15;
BA_ "GenSigStartValue" SG_ 1034 Front_Brake_Size 15;
BA_ "GenSigInvalidValue" SG_ 1034 Reserved_11_3 15;
BA_ "GenSigStartValue" SG_ 1034 Reserved_11_3 15;
BA_ "GenSigInvalidValue" SG_ 1034 TIRE_PRESSURE_MONITOR_S 15;
BA_ "GenSigStartValue" SG_ 1034 TIRE_PRESSURE_MONITOR_S 15;
BA_ "GenSigInvalidValue" SG_ 1034 BATTERY_HEATER 15;
BA_ "GenSigStartValue" SG_ 1034 BATTERY_HEATER 15;
BA_ "GenSigInvalidValue" SG_ 1034 Reserved_11_1 3;
BA_ "GenSigStartValue" SG_ 1034 Reserved_11_1 3;
BA_ "GenSigInvalidValue" SG_ 1034 TSA 3;
BA_ "GenSigStartValue" SG_ 1034 TSA 3;
BA_ "GenSigInvalidValue" SG_ 1034 AUTO_HOLD 3;
BA_ "GenSigStartValue" SG_ 1034 AUTO_HOLD 3;
BA_ "GenSigInvalidValue" SG_ 1034 EPB 3;
BA_ "GenSigStartValue" SG_ 1034 EPB 3;
BA_ "GenSigInvalidValue" SG_ 1034 Brake_Control 15;
BA_ "GenSigStartValue" SG_ 1034 Brake_Control 15;
BA_ "GenSigInvalidValue" SG_ 1034 Reserved_10_2 1048575;
BA_ "GenSigStartValue" SG_ 1034 Reserved_10_2 1048575;
BA_ "GenSigInvalidValue" SG_ 1034 CLOSED_FUEL_TANK_SYSTEM 15;
BA_ "GenSigStartValue" SG_ 1034 CLOSED_FUEL_TANK_SYSTEM 15;
BA_ "GenSigInvalidValue" SG_ 1034 BEV_MAINTENANCE_LIMIT 255;
BA_ "GenSigStartValue" SG_ 1034 BEV_MAINTENANCE_LIMIT 255;
BA_ "GenSigInvalidValue" SG_ 1034 Reserved_10_1 4095;
BA_ "GenSigStartValue" SG_ 1034 Reserved_10_1 4095;
BA_ "GenSigInvalidValue" SG_ 1034 E_OIL_MAINTENANCE_LIMIT 15;
BA_ "GenSigStartValue" SG_ 1034 E_OIL_MAINTENANCE_LIMIT 15;
BA_ "GenSigInvalidValue" SG_ 1034 REGENERATION_TYPE 15;
BA_ "GenSigStartValue" SG_ 1034 REGENERATION_TYPE 15;
BA_ "GenSigInvalidValue" SG_ 1034 I_STOP_TYPE 15;
BA_ "GenSigStartValue" SG_ 1034 I_STOP_TYPE 15;
BA_ "GenSigInvalidValue" SG_ 1034 DEVELOPMENT_FUEL 15;
BA_ "GenSigStartValue" SG_ 1034 DEVELOPMENT_FUEL 15;
BA_ "GenSigInvalidValue" SG_ 1034 PLANT 15;
BA_ "GenSigStartValue" SG_ 1034 PLANT 15;
BA_ "GenSigInvalidValue" SG_ 1034 Reserved_06_1 3;
BA_ "GenSigStartValue" SG_ 1034 Reserved_06_1 3;
BA_ "GenSigInvalidValue" SG_ 1034 Steering_Position 3;
BA_ "GenSigStartValue" SG_ 1034 Steering_Position 3;
BA_ "GenSigInvalidValue" SG_ 1034 ROOF 15;
BA_ "GenSigStartValue" SG_ 1034 ROOF 15;
BA_ "GenSigInvalidValue" SG_ 1034 TRANSMISSION 3;
BA_ "GenSigStartValue" SG_ 1034 TRANSMISSION 3;
BA_ "GenSigInvalidValue" SG_ 1034 DRIVE 3;
BA_ "GenSigStartValue" SG_ 1034 DRIVE 3;
BA_ "GenSigInvalidValue" SG_ 1034 ENGINE 15;
BA_ "GenSigStartValue" SG_ 1034 ENGINE 15;
BA_ "GenSigInvalidValue" SG_ 1034 BODY 15;
BA_ "GenSigStartValue" SG_ 1034 BODY 15;
BA_ "GenSigInvalidValue" SG_ 1034 BRAND 15;
BA_ "GenSigStartValue" SG_ 1034 BRAND 15;
BA_ "GenSigInvalidValue" SG_ 1034 MARKET 255;
BA_ "GenSigStartValue" SG_ 1034 MARKET 255;
BA_ "GenSigInvalidValue" SG_ 1034 Reserved_05_1 16777215;
BA_ "GenSigStartValue" SG_ 1034 Reserved_05_1 16777215;
BA_ "GenSigInvalidValue" SG_ 1034 Project_Code_4th 255;
BA_ "GenSigStartValue" SG_ 1034 Project_Code_4th 255;
BA_ "GenSigInvalidValue" SG_ 1034 Project_Code_3rd 255;
BA_ "GenSigStartValue" SG_ 1034 Project_Code_3rd 255;
BA_ "GenSigInvalidValue" SG_ 1034 Project_Code_2nd 255;
BA_ "GenSigStartValue" SG_ 1034 Project_Code_2nd 255;
BA_ "GenSigInvalidValue" SG_ 1034 Project_Code_1st 255;
BA_ "GenSigStartValue" SG_ 1034 Project_Code_1st 255;
BA_ "GenSigInvalidValue" SG_ 1034 Outer_Color_3 255;
BA_ "GenSigStartValue" SG_ 1034 Outer_Color_3 255;
BA_ "GenSigInvalidValue" SG_ 1034 Outer_Color_2 255;
BA_ "GenSigStartValue" SG_ 1034 Outer_Color_2 255;
BA_ "GenSigInvalidValue" SG_ 1034 Outer_Color_1 255;
BA_ "GenSigStartValue" SG_ 1034 Outer_Color_1 255;
BA_ "GenSigInvalidValue" SG_ 1034 Unit_Serial_Number 255;
BA_ "GenSigStartValue" SG_ 1034 Unit_Serial_Number 255;
BA_ "GenSigInvalidValue" SG_ 1034 Unit_Destination 255;
BA_ "GenSigStartValue" SG_ 1034 Unit_Destination 255;
BA_ "GenSigInvalidValue" SG_ 1034 Unit_Series 255;
BA_ "GenSigStartValue" SG_ 1034 Unit_Series 255;
BA_ "GenSigInvalidValue" SG_ 1034 Unit_Car_Line 255;
BA_ "GenSigStartValue" SG_ 1034 Unit_Car_Line 255;
BA_ "GenSigInvalidValue" SG_ 1034 VIN_Character_21 255;
BA_ "GenSigStartValue" SG_ 1034 VIN_Character_21 255;
BA_ "GenSigInvalidValue" SG_ 1034 VIN_Character_20 255;
BA_ "GenSigStartValue" SG_ 1034 VIN_Character_20 255;
BA_ "GenSigInvalidValue" SG_ 1034 VIN_Character_19 255;
BA_ "GenSigStartValue" SG_ 1034 VIN_Character_19 255;
BA_ "GenSigInvalidValue" SG_ 1034 VIN_Character_18 255;
BA_ "GenSigStartValue" SG_ 1034 VIN_Character_18 255;
BA_ "GenSigInvalidValue" SG_ 1034 VIN_Character_17 255;
BA_ "GenSigStartValue" SG_ 1034 VIN_Character_17 255;
BA_ "GenSigInvalidValue" SG_ 1034 VIN_Character_16 255;
BA_ "GenSigStartValue" SG_ 1034 VIN_Character_16 255;
BA_ "GenSigInvalidValue" SG_ 1034 VIN_Character_15 255;
BA_ "GenSigStartValue" SG_ 1034 VIN_Character_15 255;
BA_ "GenSigInvalidValue" SG_ 1034 VIN_Character_14 255;
BA_ "GenSigStartValue" SG_ 1034 VIN_Character_14 255;
BA_ "GenSigInvalidValue" SG_ 1034 VIN_Character_13 255;
BA_ "GenSigStartValue" SG_ 1034 VIN_Character_13 255;
BA_ "GenSigInvalidValue" SG_ 1034 VIN_Character_12 255;
BA_ "GenSigStartValue" SG_ 1034 VIN_Character_12 255;
BA_ "GenSigInvalidValue" SG_ 1034 VIN_Character_11 255;
BA_ "GenSigStartValue" SG_ 1034 VIN_Character_11 255;
BA_ "GenSigInvalidValue" SG_ 1034 VIN_Character_10 255;
BA_ "GenSigStartValue" SG_ 1034 VIN_Character_10 255;
BA_ "GenSigInvalidValue" SG_ 1034 VIN_Character_09 255;
BA_ "GenSigStartValue" SG_ 1034 VIN_Character_09 255;
BA_ "GenSigInvalidValue" SG_ 1034 VIN_Character_08 255;
BA_ "GenSigStartValue" SG_ 1034 VIN_Character_08 255;
BA_ "GenSigInvalidValue" SG_ 1034 VIN_Character_07 255;
BA_ "GenSigStartValue" SG_ 1034 VIN_Character_07 255;
BA_ "GenSigInvalidValue" SG_ 1034 VIN_Character_06 255;
BA_ "GenSigStartValue" SG_ 1034 VIN_Character_06 255;
BA_ "GenSigInvalidValue" SG_ 1034 VIN_Character_05 255;
BA_ "GenSigStartValue" SG_ 1034 VIN_Character_05 255;
BA_ "GenSigInvalidValue" SG_ 1034 VIN_Character_04 255;
BA_ "GenSigStartValue" SG_ 1034 VIN_Character_04 255;
BA_ "GenSigInvalidValue" SG_ 1034 VIN_Character_03 255;
BA_ "GenSigStartValue" SG_ 1034 VIN_Character_03 255;
BA_ "GenSigInvalidValue" SG_ 1034 VIN_Character_02 255;
BA_ "GenSigStartValue" SG_ 1034 VIN_Character_02 255;
BA_ "GenSigInvalidValue" SG_ 1034 VIN_Character_01 255;
BA_ "GenSigStartValue" SG_ 1034 VIN_Character_01 255;
BA_REL_ "SC_Verification" BU_SG_REL_ DSC SG_ 1066 Hvac_Control_Information2_MACTx 0;
BA_REL_ "SC_Verification" BU_SG_REL_ RCM SG_ 1066 Hvac_Control_Information2_MACTx 0;
BA_REL_ "SC_Verification" BU_SG_REL_ DSC SG_ 1066 Hvac_Control_Information2_FVTx 0;
BA_REL_ "SC_Verification" BU_SG_REL_ RCM SG_ 1066 Hvac_Control_Information2_FVTx 0;
BA_REL_ "SC_Verification" BU_SG_REL_ CGW SG_ 1046 BrakeSysFeatures2_MACTx 0;
BA_REL_ "SC_Verification" BU_SG_REL_ CGW SG_ 1046 BrakeSysFeatures2_FVTx 0;
BA_REL_ "SC_Verification" BU_SG_REL_ CGW SG_ 1044 BrakeSysFeatures_MACTx 0;
BA_REL_ "SC_Verification" BU_SG_REL_ RCM SG_ 1044 BrakeSysFeatures_MACTx 0;
BA_REL_ "SC_Verification" BU_SG_REL_ CGW SG_ 1044 BrakeSysFeatures_FVTx 0;
BA_REL_ "SC_Verification" BU_SG_REL_ RCM SG_ 1044 BrakeSysFeatures_FVTx 0;
VAL_ 1450 ECB_NM_RptMsgRequest 0 "RepeatMessageState_not_request" 1 "RepeatMessageState_request" ;
VAL_ 1430 DSC_NM_RptMsgRequest 0 "RepeatMessageState_not_request" 1 "RepeatMessageState_request" ;
VAL_ 1409 CGW_NM_RptMsgRequest 0 "RepeatMessageState_not_request" 1 "RepeatMessageState_request" ;
VAL_ 1329 DiagSupt_Status_ECB 0 "NotSupported_GDDS" 1 "Supported_GGDS" ;
VAL_ 1329 TrigReq_ECB 0 "No" 1 "Yes" ;
VAL_ 1329 DataNumber_ECB 0 "Data1" 1 "Data2" ;
VAL_ 1325 DiagSupt_Status_RCM 0 "NotSupported_GDDS" 1 "Supported_GGDS" ;
VAL_ 1325 TrigReq_RCM 0 "No" 1 "Yes" ;
VAL_ 1325 DataNumber_RCM 0 "Data1" 1 "Data2" ;
VAL_ 1324 DiagSupt_Status_EPAS 0 "NotSupported_GDDS" 1 "Supported_GGDS" ;
VAL_ 1324 TrigReq_EPAS 0 "No" 1 "Yes" ;
VAL_ 1324 DataNumber_EPAS 0 "Data1" 1 "Data2" ;
VAL_ 1307 DiagSupt_Status_DSC 0 "NotSupported_GDDS" 1 "Supported_GGDS" ;
VAL_ 1307 TrigReq_DSC 0 "No" 1 "Yes" ;
VAL_ 1307 DataNumber_DSC 0 "Data1" 1 "Data2" ;
VAL_ 1264 SCR_Variants 0 "None" 1 "SCR" ;
VAL_ 1264 Filter_Variants 0 "None" 1 "GPF" 2 "DPF" ;
VAL_ 1264 Turbo_Variants 0 "without Turbo" 1 "with Turbo" ;
VAL_ 1264 EngCltFlow_Cnt_Vlv_Variants 0 "without EngCltFlow_Cnt_Vlv" 1 "with EngCltFlow_Cnt_Vlv" ;
VAL_ 1264 CylinderDeactivation_Variants 0 "without Cylinder Deactivation" 1 "with Cylinder Deactivation" ;
VAL_ 1264 OLS_Monitor_Variants 0 "OFF" 1 "ON" 2 "Reserved" 3 "Reserved" ;
VAL_ 1264 EngineType_Calibration 0 "unkown" 1 "Gasoline_Engine_G1" 2 "Diesel_Engine_D1" 3 "Reserved" 4 "Gasoline_Engine_G2" 5 "Diesel_Engine_D2" 6 "Reserved" 7 "Reserved" 8 "Reserved" 9 "Reserved" 10 "Reserved" 11 "Reserved" 12 "Reserved" 13 "Reserved" 14 "Reserved" 15 "Reserved" ;
VAL_ 1264 TransmissionType 0 "Unknown" 1 "Manual Transmission" 2 "SSM_PCM_incl" 3 "SSM_alone" 4 "ASM_PCM_incl" 5 "ASM_alone" 6 "PSM_PCM_incl" 7 "PSM_alone" 8 "CVT_PCM_incl" 9 "CVT_alone" 10 "ATX_PCM_incl" 11 "ATX_alone" 12 "i-stop_MT" 13 "i-stop_AT" 15 "Invalid" ;
VAL_ 1264 FuelType_Delivery 0 "Unknown" 1 "Gasoline_DISI" 2 "Gasoline_EFI" 3 "Diesel_DI" 4 "Diesel_IDI" 5 "EV_HEV" 6 "Natural Gas_CFI" 7 "Natural Gas_EFI" 8 "Flexible Fuel_CFI" 9 "Flexible Fuel_EFI" 10 "Gasoline_i-stop" 11 "Diesel_i-stop" ;
VAL_ 1254 VDT_INV_ODR2_ReqTCU 0 "OFF" 1 "ON" ;
VAL_ 1254 VDT_INV_ODR2_Rq 0 "OFF" 1 "ON" ;
VAL_ 1254 VDT_ECM_ODR1_ReqTCU 0 "OFF" 1 "ON" ;
VAL_ 1254 VDT_ECM_ODR1_Rq 0 "OFF" 1 "ON" ;
VAL_ 1254 VDT_RCM_ODR1_ReqTCU 0 "OFF" 1 "ON" ;
VAL_ 1254 VDT_RCM_ODR1_Rq 0 "OFF" 1 "ON" ;
VAL_ 1254 TCU_SW_Update_Resp 0 "NormalMode" 1 "TCU_LimitMode" ;
VAL_ 1254 VDT_Cancel_PreAC_Resp 0 "NoReq" 1 "SOC" 2 "System Error" 3 "Performance_Door_LG" 4 "Completed" 5 "DCCharge_ExternalFactor" 6 "Reserved" 7 "Reserved" ;
VAL_ 1254 VDT_PreAC_Resp 0 "NoReq" 1 "SOC" 2 "System Error" 3 "Performance_Door_LG" 4 "DCCharge_ExternalFactor" 5 "Reserved" 6 "Reserved" 7 "Reserved" ;
VAL_ 1254 VDT_Cancel_Charge_Resp 0 "reserved" 1 "System Error" 2 "reserved" 3 "reserved" 4 "not P" 5 "reserved" 6 "reserved" 7 "completed" 8 "connector_Nondetection" ;
VAL_ 1254 VDT_Charge_Resp 0 "reserved" 1 "System Error" 2 "reserved" 3 "reserved" 4 "not P" 5 "reserved" 6 "charging" 7 "completed" 8 "connector_Nondetection" ;
VAL_ 1170 CstmzStat_CTS_HighWay 0 "Not Adopted" 1 "OFF" 2 "ON" ;
VAL_ 1170 CstmzStat_FCTA_ONOFF 0 "Not Adopted" 1 "OFF" 2 "Sign only" 3 "Sign + Buzzer" ;
VAL_ 1170 CstmzStat_FCTA_Sens 0 "Not Adopted" 1 "Sensitivity_1(HI)" 2 "Sensitivity_2(Mid)" 3 "Sensitivity_3(LO)" ;
VAL_ 1170 CstmzStat_TAP_ONOFF 0 "Not Adopted" 1 "OFF" 2 "ON" ;
VAL_ 1170 CstmzStat_ELK_ONOFF 0 "Not Adopted" 1 "OFF" 2 "ON" ;
VAL_ 1170 CstmzStat_RAEB_ONOFF 0 "Not Adopted" 1 "OFF" 2 "ON" ;
VAL_ 1170 CstmzStat_FAEB_Sens 0 "Not Adopted" 1 "Sensitivity_1(HI)" 2 "Sensitivity_2(Mid)" 3 "Sensitivity_3(LO)" ;
VAL_ 1170 CstmzStat_FAEB_ONOFF 0 "Not Adopted" 1 "OFF" 2 "ON" ;
VAL_ 1170 CstmzStat_CTB_ONOFF 0 "Not Adopted" 1 "OFF" 2 "ON" ;
VAL_ 1170 CstmzStat_LDP_ONOFF 0 "Not Adopted" 1 "OFF" 2 "ON" ;
VAL_ 1170 CstmzStat_DAS_ONOFF 0 "Not Adopted" 1 "OFF" 2 "ON" ;
VAL_ 1170 CstmzStat_LDP_RDP_Warn 0 "Not Adopted" 1 "Vibration" 2 "Buzzer" 3 "Vibration + Buzzer" ;
VAL_ 1170 CstmzStat_BSM_Sens 0 "Not Adopted" 1 "Sensitivity_1(HI)" 2 "Sensitivity_2(Mid)" 3 "Sensitivity_3(LO)" ;
VAL_ 1170 CstmzStat_BSM_ONOFF 0 "Not Adopted" 1 "OFF" 2 "Sign only" 3 "Sign + Warning" ;
VAL_ 1170 CstmzStat_LDW_ONOFF 0 "Not Adopted" 1 "OFF" 2 "ON" ;
VAL_ 1170 CstmzStat_RCTB_ONOFF 0 "Not Adopted" 1 "OFF" 2 "ON" ;
VAL_ 1170 CstmzStat_FCTB_Disp_ONOFF 0 "Not Adopted" 1 "OFF" 2 "ON" ;
VAL_ 1170 CstmzStat_FCTB_ONOFF 0 "Not Adopted" 1 "OFF" 2 "ON" ;
VAL_ 1170 CstmzStat_SpLmt_Warn_Thres 0 "Not Adopted" 1 "0km/h(0mph)" 2 "5km/h(3mph)" 3 "10km/h(5mph)" 4 "TBD" ;
VAL_ 1170 CstmzStat_SpLmt_Warn 0 "Not Adopted" 1 "OFF" 2 "Sign only" 3 "Sign + Buzzer" ;
VAL_ 1170 CstmzStat_TSR_Warn_Thres 0 "Not Adopted" 1 "0km/h(0mph)" 2 "5km/h(3mph)" 3 "10km/h(5mph)" 4 "TBD" ;
VAL_ 1170 CstmzStat_TSR_Warn 0 "Not Adopted" 1 "OFF" 2 "Sign only" 3 "Sign + Buzzer" ;
VAL_ 1170 CstmzStat_MRCC_Bz_ONOFF 0 "Not Adopted" 1 "OFF" 2 "ON" ;
VAL_ 1170 CstmzStat_TSR_Mode 0 "Not Adopted" 1 "OFF" 2 "Manually" 3 "Automatically" ;
VAL_ 1170 CstmzStat_MRCC_ASC_Mode 0 "Not Adopted" 1 "OFF(ASC)" 2 "ON(ACC)" ;
VAL_ 1170 CstmzStat_TJA_Mode 0 "Not Adopted" 1 "Confort" 2 "Normal" 3 "Sport" ;
VAL_ 1120 rdL_OCS_Stat_D_Actl 0 "Unknown" 1 "Vacancy" 2 "Occupied" 3 "Malfunction" ;
VAL_ 1120 rdR_OCS_Stat_D_Actl 0 "Unknown" 1 "Vacancy" 2 "Occupied" 3 "Malfunction" ;
VAL_ 1120 DrLock_Message_R_Rsp 0 "Unknown" 1 "NG" 2 "OK" ;
VAL_ 1120 RR_OCS_Stat_D_Actl 0 "Unknown" 1 "Vacancy" 2 "Occupied" 3 "Malfunction" ;
VAL_ 1120 RC_OCS_Stat_D_Actl 0 "Unknown" 1 "Vacancy" 2 "Occupied" 3 "Malfunction" ;
VAL_ 1120 RL_OCS_Stat_D_Actl 0 "Unknown" 1 "Vacancy" 2 "Occupied" 3 "Malfunction" ;
VAL_ 1120 DrStatRl_B_Actl 0 "Door Closed" 1 "Door Ajar" ;
VAL_ 1120 DrStatR_D_Qf 0 "Faulty" 1 "Undefined" 2 "Not within specification" 3 "OK" ;
VAL_ 1120 TrnkLg_Motor_Stat 0 "Not Drive" 1 "Drive" ;
VAL_ 1120 Fuel_Lid_Open_Status 0 "Door Closed" 1 "Door Ajar" ;
VAL_ 1120 StopLampCon_Status 0 "StopLampOff" 1 "StopLampOn" 2 "Hard_Failure" 3 "Communication_Failure" ;
VAL_ 1120 DrStatTrnkLg_B_Actl 0 "Door Closed" 1 "Door Ajar" ;
VAL_ 1120 ParkBrkActv_D_Actl2 0 "Off" 1 "ON" 2 "Reserved" 3 "Unknown" ;
VAL_ 1120 AutoHoldSw_B_Actl 0 "Off" 1 "On" ;
VAL_ 1106 CBDA_target_lh 0 "none" 1 "Detect" 2 "Warn" 3 "none" ;
VAL_ 1106 CBDA_target_rh 0 "none" 1 "Detect" 2 "Warn" 3 "none" ;
VAL_ 1106 CBDA_EV_failure 0 "no event" 1 "failure event" ;
VAL_ 1106 CBDA_EV_tmp_failure 0 "no event" 1 "temporary failure event" ;
VAL_ 1106 CBDA_EV_fallback 0 "no event" 1 "fallback event" ;
VAL_ 1106 CBDA_fallback 0 "normal" 1 "fallback" ;
VAL_ 1106 CBDA_state 0 "not adopted" 1 "off" 2 "inactive" 3 "active" 13 "temporary failure" 14 "initialization" 15 "failure" ;
VAL_ 1106 LDW_lane_lh 0 "none" 1 "Detect" 2 "Warn" 3 "none" ;
VAL_ 1106 LDW_lane_rh 0 "none" 1 "Detect" 2 "Warn" 3 "none" ;
VAL_ 1106 LDW_EV_failure 0 "no event" 1 "failure event" ;
VAL_ 1106 LDW_EV_tmp_failure 0 "no event" 1 "temporary failure event" ;
VAL_ 1106 LDW_EV_warning_rh 0 "no event" 1 "right warning event" ;
VAL_ 1106 LDW_EV_warning_lh 0 "no event" 1 "left warning event" ;
VAL_ 1106 LDW_fallback 0 "normal" 1 "fallback" ;
VAL_ 1106 LDW_state 0 "not adopted" 1 "off" 2 "inactive" 3 "active" 13 "temporary failure" 14 "initialization" 15 "failure" ;
VAL_ 1106 OCP_opp_lh 0 "none" 1 "Detect" 2 "Warn" 3 "none" ;
VAL_ 1106 OCP_opp_rh 0 "none" 1 "Detect" 2 "Warn" 3 "none" ;
VAL_ 1106 OCP_lane_lh 0 "none" 1 "Detect" 2 "Warn" 3 "none" ;
VAL_ 1106 OCP_lane_rh 0 "none" 1 "Detect" 2 "Warn" 3 "none" ;
VAL_ 1106 OCP_EV_failure 0 "no event" 1 "failure event" ;
VAL_ 1106 OCP_EV_tmp_failure 0 "no event" 1 "temporary failure event" ;
VAL_ 1106 OCP_alarm 0 "no alarm" 1 "alarm" ;
VAL_ 1106 OCP_fallback 0 "normal" 1 "fallback" ;
VAL_ 1106 OCP_state 0 "not adopted" 1 "off" 2 "inactive" 3 "active" 4 "control" 13 "temporary failure" 14 "initialization" 15 "failure" ;
VAL_ 1106 BSP_alarm 0 "no alarm" 1 "alarm" ;
VAL_ 1106 BSP_target_lh 0 "none" 1 "Detect" 2 "Warn" 3 "none" ;
VAL_ 1106 BSP_target_rh 0 "none" 1 "Detect" 2 "Warn" 3 "none" ;
VAL_ 1106 BSP_lane_lh 0 "none" 1 "Detect" 2 "Warn" 3 "none" ;
VAL_ 1106 BSP_lane_rh 0 "none" 1 "Detect" 2 "Warn" 3 "none" ;
VAL_ 1106 BSP_EV_failure 0 "no event" 1 "failure event" ;
VAL_ 1106 BSP_EV_tmp_failure 0 "no event" 1 "temporary failure event" ;
VAL_ 1106 BSP_fallback 0 "normal" 1 "fallback" ;
VAL_ 1106 BSP_state 0 "not adopted" 1 "off" 2 "inactive" 3 "active" 4 "control" 12 "towing off" 13 "temporary failure" 14 "initialization" 15 "failure" ;
VAL_ 1099 REDKEY_EV_on 0 "no event" 1 "on event" ;
VAL_ 1099 REDKEY_state 0 "not adopted" 1 "off" 2 "on" 14 "initialization" 15 "failure" ;
VAL_ 1099 ISA_EV_failure 0 "no event" 1 "failure event" ;
VAL_ 1099 ISA_EV_fallback 0 "no event" 1 "fallback1 event" ;
VAL_ 1099 ISA_EV_kickdown 0 "no event" 1 "kickdown event" ;
VAL_ 1099 ISA_EV_reject 0 "no event" 1 "reject event" ;
VAL_ 1099 ISA_EV_spd_autoset 0 "no event" 1 "autoset event" ;
VAL_ 1099 ISA_overspeed 0 "normal" 1 "over speed1" 2 "over speed2" ;
VAL_ 1099 ISA_sign 0 "no sign" 1 "sign" 2 "offer_sign" ;
VAL_ 1099 ISA_state 0 "not adopted" 1 "off" 2 "inactive" 3 "active" 4 "kickdown" 14 "initialization" 15 "failure" ;
VAL_ 1099 ISA_fallback 0 "normal range" 1 "fallback" 2 "fallback2" ;
VAL_ 1099 ASC_EV_failure 0 "no event" 1 "failure event" ;
VAL_ 1099 ASC_EV_fallback 0 "no event" 1 "fallback event" ;
VAL_ 1099 ASC_EV_suspended 0 "no event" 1 "suspended event" ;
VAL_ 1099 ASC_EV_reject 0 "no event" 1 "reject event" ;
VAL_ 1099 ASC_EV_accept 0 "no event" 1 "accept event" ;
VAL_ 1099 ASC_state 0 "not adopted" 1 "off" 2 "inactive" 3 "active" 4 "override" 14 "initialization" 15 "failure" ;
VAL_ 1098 LKA_target 0 "no target" 1 "forward target" 2 "right" 3 "left" 4 "both" ;
VAL_ 1098 LKA_EV_dassw_reject 0 "no event" 1 "dassw reject event" ;
VAL_ 1098 LKA_EV_failure 0 "no event" 1 "failure event" ;
VAL_ 1098 LKA_EV_tmp_failure 0 "no event" 1 "temporary failure event" ;
VAL_ 1098 LKA_EV_fallback 0 "no event" 1 "fallback event" ;
VAL_ 1098 LKA_EV_suspended 0 "no event" 1 "suspended event" ;
VAL_ 1098 LKA_handsfree 0 "no event" 1 "handsfree1 event" 2 "handsfree2 event" 3 "handsfree3 event" 4 "handsfree4 event" 5 "handsfree5 event" 6 "handsfree6 event" 7 "handsfree7 event" ;
VAL_ 1098 LKA_EV_reject 0 "no event" 1 "reject event" ;
VAL_ 1098 LKA_control_limit_rh 0 "no event" 1 "control limit event" ;
VAL_ 1098 LKA_control_limit_lh 0 "no event" 1 "control limit event" ;
VAL_ 1098 LKA_fallback 0 "normal range" 1 "fallback1" ;
VAL_ 1098 LKA_EV_inactive_handsfree 0 "no event" 1 "handsfree event" ;
VAL_ 1098 LKA_EV_inactive_handson 0 "no event" 1 "handson event" ;
VAL_ 1098 LKA_state 0 "not adopted" 1 "off" 2 "inactive" 3 "active" 4 "override" 13 "temporary failure" 14 "initialization" 15 "failure" ;
VAL_ 1098 ACC_target_distance 0 "not detected" 1 "long" 2 "middle" 3 "short" 4 "very short" 5 "long start" 6 "middle start" 7 "short start" 8 "very short start" ;
VAL_ 1098 ACC_set_distance 0 "off" 1 "Distance 1" 2 "Distance 2" 3 "Distance 3" 4 "Distance 4" ;
VAL_ 1098 ACC_EV_dassw_reject 0 "no event" 1 "dassw reject event" ;
VAL_ 1098 ACC_EV_set_dist 0 "no event" 1 "set dist event" ;
VAL_ 1098 ACC_EV_failure 0 "no event" 1 "failure event" ;
VAL_ 1098 ACC_EV_tmp_failure 0 "no event" 1 "temporary failure event" ;
VAL_ 1098 ACC_EV_fallback2 0 "no event" 1 "fallback2 event" ;
VAL_ 1098 ACC_EV_fallback1 0 "no event" 1 "fallback1 event" ;
VAL_ 1098 ACC_EV_suspended 0 "no event" 1 "suspended event" ;
VAL_ 1098 ACC_EV_start 0 "no event" 1 "start1 event" ;
VAL_ 1098 ACC_shift_position 0 "no event" 1 "shift ok" 2 "shift up" 3 "shift down" ;
VAL_ 1098 ACC_warning 0 "no event" 1 "warning event" ;
VAL_ 1098 ACC_EV_reject 0 "no event" 1 "reject event" ;
VAL_ 1098 ACC_EV_accept 0 "no event" 1 "accept event" ;
VAL_ 1098 ACC_fallback 0 "normal range" 1 "fallback1" 2 "fallback2" ;
VAL_ 1098 ACC_target 0 "no target" 1 "vehicle" 2 "bike" ;
VAL_ 1098 ACC_stop 0 "not stop" 1 "stop" ;
VAL_ 1098 ACC_sign 0 "no sign" 1 "sign" 2 "offer sign" 3 "offer sign next" 4 "sign auto" 5 "notice sign" 6 "notice sign next" ;
VAL_ 1098 ACC_state 0 "not adopted" 1 "off" 2 "inactive" 3 "active" 4 "override" 13 "temporary failure" 14 "initialization" 15 "failure" ;
VAL_ 1096 LDP_alarm 0 "no event" 1 "alarm event" ;
VAL_ 1096 LDP_fallback 0 "no event" 1 "fallback event" ;
VAL_ 1096 LDP_EV_failure 0 "no event" 1 "failure event" ;
VAL_ 1096 LDP_EV_tmp_failure 0 "no event" 1 "temporary failure event" ;
VAL_ 1096 LDP_EV_warning_rh 0 "no event" 1 "right warning event" ;
VAL_ 1096 LDP_EV_warning_lh 0 "no event" 1 "left warning event" ;
VAL_ 1096 LDP_lane_lh 0 "none" 1 "Detect" 2 "Warn" 3 "none" ;
VAL_ 1096 LDP_lane_rh 0 "none" 1 "Detect" 2 "Warn" 3 "none" ;
VAL_ 1096 LDP_state 0 "not adopted" 1 "off" 2 "inactive" 3 "active" 4 "control" 13 "temporary failure" 14 "initialization" 15 "failure" ;
VAL_ 1096 BSM_EV_failure 0 "no event" 1 "failure event" ;
VAL_ 1096 BSM_EV_tmp_failure 0 "no event" 1 "temporary failure event" ;
VAL_ 1096 BSM_EV_warning_rh 0 "no event" 1 "right warning event" ;
VAL_ 1096 BSM_EV_warning_lh 0 "no event" 1 "left warning event" ;
VAL_ 1096 BSM_fallback 0 "normal" 1 "fallback" ;
VAL_ 1096 BSM_target_lh 0 "none" 1 "Detect" 2 "Warn" 3 "none" ;
VAL_ 1096 BSM_target_rh 0 "none" 1 "Detect" 2 "Warn" 3 "none" ;
VAL_ 1096 BSM_state 0 "not adopted" 1 "off" 2 "inactive" 3 "active" 12 "towing off" 13 "temporary failure" 14 "initialization" 15 "failure" ;
VAL_ 1096 RDP_alarm 0 "no event" 1 "alarm event" ;
VAL_ 1096 RDP_fallback 0 "no event" 1 "fallback" ;
VAL_ 1096 RDP_EV_failure 0 "no event" 1 "failure event" ;
VAL_ 1096 RDP_EV_tmp_failure 0 "no event" 1 "temporary failure event" ;
VAL_ 1096 RDP_roadedge_lh 0 "none" 1 "Detect" 2 "Warn" 3 "none" ;
VAL_ 1096 RDP_roadedge_rh 0 "none" 1 "Detect" 2 "Warn" 3 "none" ;
VAL_ 1096 RDP_state 0 "not adopted" 1 "off" 2 "inactive" 3 "active" 4 "control" 13 "temporary failure" 14 "initialization" 15 "failure" ;
VAL_ 1095 CTB_target_lh 0 "none" 1 "Detect" 2 "Warn" 3 "none" ;
VAL_ 1095 CTB_target_rh 0 "none" 1 "Detect" 2 "Warn" 3 "none" ;
VAL_ 1095 CTB_EV_failure 0 "no event" 1 "failure event" ;
VAL_ 1095 CTB_EV_tmp_failure 0 "no event" 1 "temporary failure event" ;
VAL_ 1095 CTB_EV_fallback 0 "no event" 1 "fallback event" ;
VAL_ 1095 CTB_EV_notification 0 "no event" 1 "notification event" ;
VAL_ 1095 CTB_EV_warning 0 "no event" 1 "warning event" ;
VAL_ 1095 CTB_EV_off 0 "no event" 1 "off event" ;
VAL_ 1095 CTB_fallback 0 "normal range" 1 "fallback1" ;
VAL_ 1095 CTB_state 0 "not adopted" 1 "off" 2 "inactive" 3 "active" 4 "control" 5 "notification" 12 "towing off" 13 "temporary failure" 14 "initialization" 15 "failure" ;
VAL_ 1095 FCTA_target_lh 0 "none" 1 "Detect" 2 "Warn" 3 "none" ;
VAL_ 1095 FCTA_target_rh 0 "none" 1 "Detect" 2 "Warn" 3 "none" ;
VAL_ 1095 FCTA_EV_failure 0 "no event" 1 "failure event" ;
VAL_ 1095 FCTA_EV_tmp_failure 0 "no event" 1 "temporary failure event" ;
VAL_ 1095 FCTA_EV_fallback 0 "no event" 1 "fallback event" ;
VAL_ 1095 FCTA_EV_warning2_rh 0 "no event" 1 "warning event" ;
VAL_ 1095 FCTA_EV_warning2_lh 0 "no event" 1 "warning event" ;
VAL_ 1095 FCTA_fallback 0 "normal range" 1 "fallback1" ;
VAL_ 1095 FCTA_state 0 "not adopted" 1 "off" 2 "inactive" 3 "active" 13 "temporary failure" 14 "initialization" 15 "failure" ;
VAL_ 1095 PTC_EV_off 0 "no event" 1 "off event" ;
VAL_ 1095 PTC_EV_notification 0 "no event" 1 "notification event" ;
VAL_ 1095 PTC_fallback 0 "normal range" 1 "fallback1" ;
VAL_ 1095 PTC_state 0 "not adopted" 1 "off" 2 "inactive" 3 "active" 4 "control" 5 "notification" 12 "towing off" 13 "temporary failure" 14 "initialization" 15 "failure" ;
VAL_ 1095 AEB_EV_notification 0 "no event" 1 "notification event" ;
VAL_ 1095 AEB_EV_off 0 "no event" 1 "off event" ;
VAL_ 1095 AEB_fallback 0 "normal range" 1 "fallback1" ;
VAL_ 1095 AEB_state 0 "not adopted" 1 "off" 2 "inactive" 3 "active" 4 "control" 5 "notification" 12 "towing off" 13 "temporary failure" 14 "initialization" 15 "failure" ;
VAL_ 1088 Move_AutoDposMirror_Res 0 "No Action" 1 "AutoDpos Complete" 2 "AutoDpos Reject" 3 "(Reserve)" ;
VAL_ 1088 MirrorLED1_status 0 "Normal" 1 "Abnormal" ;
VAL_ 1088 DrLock_Message_D_Rsp 0 "Unknown" 1 "NG" 2 "OK" ;
VAL_ 1088 DrivingPositionRequest 0 "No Action" 1 "Record Request" 2 "Erase Request" 3 "Recall Request" ;
VAL_ 1088 Mirror_AjustSelSW_Status 0 "OFF" 1 "Right ON" 2 "Left ON" 3 "Reserved" ;
VAL_ 1088 MirrorFoldRequest 0 "OFF" 1 "Fold" 2 "Unfold" 3 "Reserved" ;
VAL_ 1088 MirrorAdjustRequest 0 "OFF" 1 "Up" 2 "Down" 3 "Right" 4 "Left" 5 "Reserved" 6 "Reserved" 7 "Reserved" ;
VAL_ 1088 MirrorAdjst_Manual_Status 0 "OFF" 1 "ON" ;
VAL_ 1088 MirrorAdjst_Status 0 "Stop" 1 "Moving" ;
VAL_ 1088 Erase_MirrorMem_Res 0 "No Action" 1 "Complete" 2 "Reject" 3 "(Reserve)" ;
VAL_ 1088 Recall_MirrorMem_Res 0 "No Action" 1 "Complete" 2 "Reject" 3 "NoNeed" ;
VAL_ 1088 Record_MirrorMem_Res 0 "No Action" 1 "Complete" 2 "Reject" 3 "(Reserve)" ;
VAL_ 1088 PW_Move_R 0 "OFF" 1 "ManualOpen" 2 "ManualClose" 3 "AutoOpen" 4 "AutoClose" 5 "Stop" 6 "Reserved" 7 "Reserved" ;
VAL_ 1088 PW_Move_P 0 "OFF" 1 "ManualOpen" 2 "ManualClose" 3 "AutoOpen" 4 "AutoClose" 5 "Stop" 6 "Reserved" 7 "Reserved" ;
VAL_ 1088 PWcut_D_Actl 0 "Unknown" 1 "OFF" 2 "ON" 3 "Reserve" ;
VAL_ 1088 DrvDLMotorDriveStat 0 "Not Drive" 1 "All LockDrive" 2 "All SuperLockDrive" 3 "All UnLockDrive" 4 "Only DrvUnLockDrive" 5 "Return All LockDrive" 6 "Reserve" 7 "Reserve" ;
VAL_ 1088 Ctrl_DLSw_Drv_Stat 0 "Neutral" 1 "Lock" 2 "Unlock" ;
VAL_ 1088 LockLinkSwDrv_D_Actl 0 "Unlock" 1 "Neutral" 2 "Lock" 3 "Failure" ;
VAL_ 1088 DrStatDrv_D_Qf 0 "Faulty" 1 "Undefined" 2 "Not within specification" 3 "OK" ;
VAL_ 1088 DrStatDrv_B_Actl 0 "Door Closed" 1 "Door Ajar" ;
VAL_ 1081 LocateTime_Info_Data_Number 0 "Data1" 1 "Data2" 2 "Data3" 3 "Data4" ;
VAL_ 1078 SteerHeatIndic_D_Req 0 "Off" 1 "On" 2 "Auto" 3 "Reserve" ;
VAL_ 1078 SteerHeat_Elm_Enable 0 "ELM Enable" 1 "ELM Disable1" 2 "ELM Disable2" 3 "ELM Disable3" ;
VAL_ 1078 SeatHeat_Elm_Enable 0 "ELM Enable" 1 "ELM Disable1" 2 "ELM Disable2" 3 "ELM Disable3" ;
VAL_ 1078 Charge_Mode_Enabled_SW 0 "Off" 1 "On" 2 "Unknown" ;
VAL_ 1078 Drive_Mode_Enabled_Switch 0 "Off" 1 "SW-Up" 2 "SW-Down" 3 "Unknown" ;
VAL_ 1078 atcControlStatus 0 "NotDefined" 1 "Initialize" 2 "Normal" 3 "FailSafe" ;
VAL_ 1078 SeatVentIndicFr_D_Req 0 "Off" 1 "Low" 2 "Mid" 3 "High" 4 "Auto" 5 "Grayout" 6 "Reserved" 7 "Reserved" ;
VAL_ 1078 SeatVentIndicFl_D_Req 0 "Off" 1 "Low" 2 "Mid" 3 "High" 4 "Auto" 5 "Grayout" 6 "Reserved" 7 "Reserved" ;
VAL_ 1078 SeatHeatIndicFr_D_Req 0 "Off" 1 "Low" 2 "Mid" 3 "High" 4 "Auto" 5 "Grayout" 6 "Reserved" 7 "Reserved" ;
VAL_ 1078 SeatHeatIndicFl_D_Req 0 "Off" 1 "Low" 2 "Mid" 3 "High" 4 "Auto" 5 "Grayout" 6 "Reserved" 7 "Reserved" ;
VAL_ 1078 atcACmodeDisp 0 "NotDefined" 1 "(Reserved)" 2 "OFF" 3 "AC" 4 "AC-ECO" ;
VAL_ 1078 atcAImodeDisp 0 "NotDefined" 1 "(Reserved)" 2 "FRS" 3 "REC" 4 "REC025" 5 "REC050" 6 "REC075" 7 "Variable" ;
VAL_ 1078 atcADmodeDisp 0 "NotDefined" 1 "(Reserved)" 2 "PANEL" 3 "B/L" 4 "FLOOR" 5 "D/F" 6 "DEF" ;
VAL_ 1078 atcBlwLvlDisp 0 "NotDefined" 1 "Level 0(Relay OPEN)" 2 "Level 0(OFF)" 3 "Level 1" 4 "Level 2" 5 "Level 3" 6 "Level 4" 7 "Level 5" 8 "Level 6" 9 "Level 7" ;
VAL_ 1078 HvacEngStopCtrl_D_Actl 0 "Prohibit_Condition" 1 "Cooling" 2 "Heating" 3 "Cooling_Heating" ;
VAL_ 1078 BlowerSpeed 0 "inactive" 1 "Speed 0" 2 "Speed 1" 3 "Speed 2" 4 "Speed 3" 5 "Speed 4" 6 "Speed 5" 7 "Speed 6" 8 "Speed 7" ;
VAL_ 1078 HvacEngStopInputFail_D_Rq 0 "Normal" 1 "IS Input Fail" 2 "IS Input Fail manual DEF" 3 "Reserved" 4 "Reserved" 5 "Reserved" 6 "Reserved" 7 "Reserved" ;
VAL_ 1078 HvacAirCond_B_Rq 0 "No" 1 "Yes" ;
VAL_ 1078 HvacEngStopDis_B_Rq_exceptTEva 0 "IS Off" 1 "IS On" ;
VAL_ 1078 HvacEngStopDis_B_Rq 0 "IS Off" 1 "IS On" ;
VAL_ 1077 MntOilLvl_AtFlg 0 "oil maintenance not available" 1 "oil maintenance available" ;
VAL_ 1077 MntTyre_AtFlg 0 "Display Inhibitted" 1 "Display Allowed" ;
VAL_ 1077 RR_TyrePressWarn 0 "Normal" 1 "Low" 2 "not Available" 3 "Reserved" ;
VAL_ 1077 RL_TyrePressWarn 0 "Normal" 1 "Low" 2 "not Available" 3 "Reserved" ;
VAL_ 1077 FR_TyrePressWarn 0 "Normal" 1 "Low" 2 "not Available" 3 "Reserved" ;
VAL_ 1077 FL_TyrePressWarn 0 "Normal" 1 "Low" 2 "not Available" 3 "Reserved" ;
VAL_ 1077 TPMS_SystemFlt 0 "No Failure" 1 "CAN missing" 2 "D missing&error" 3 "WU battery low" 4 "ECU internal failure" 5 "10 times error" 6 "Reserved" 7 "Reserved" ;
VAL_ 1077 TPMS_Status 0 "normal" 1 "fail" 2 "Reserved" 3 "Reserved" ;
VAL_ 1077 RunflatWarnLamp_B_Rq 0 "off" 1 "on" ;
VAL_ 1077 TPMSCtlLamp_D_Rq 0 "OFF" 1 "ON" 2 "blink(slow)" 3 "blink(fast)" ;
VAL_ 1077 Data_Number 0 "Data1" 1 "Data2" 2 "Data3" 3 "Data4" 4 "Data5" 5 "Data6" ;
VAL_ 1068 TCU_ComFail_MsgType 0 "Nomal" 1 "Fail_Only_ConnectedService" 2 "Fail_ECall_and_ConnectedService" 3 "Fail_Only_Ecall" ;
VAL_ 1068 TCU_Service_Flag 0 "Unknown" 1 "OFF" 2 "ON" 3 "Reserved" ;
VAL_ 1068 TCU_ComStatus_Notification 0 "NormalMode" 1 "StopMode(CMU)" 2 "StopMode(Center)" 3 "StopMode(CMU/Center)" ;
VAL_ 1068 TCU_SW_Update_Req 0 "NormalMode" 1 "TCU_LimitMode" ;
VAL_ 1068 VDT_BECM_ODR2_ResTCU 0 "reserve" 1 "Accept" 2 "Reject" 3 "Completed" ;
VAL_ 1068 Audio_mute_request_result 0 "reserved" 1 "Only_CAN" 2 "CAN_and_MOST" 3 "Only_MOST" ;
VAL_ 1068 Crash_output_relay_result 0 "Sent" 1 "NotSent" ;
VAL_ 1068 Fialure_reason 0 "Network Not Found" 1 "Network Busy" 2 "Buckup Battery Low Voltage" 3 "Switch Not Pressed Enough Period" 4 "System Error" 5 "reserved" 6 "reserved" 7 "No Failure" ;
VAL_ 1068 Voice_Communication_result 0 "Connected" 1 "NotConnected" ;
VAL_ 1068 Data_Transmission_result 0 "Sent" 1 "NotSent" ;
VAL_ 1068 Call_Trigger_Type 0 "Automatic" 1 "Manual" 2 "Test(Automatic)" 3 "Test(Manual)" 4 "Driver Abnomality" 5 "reserved" 6 "reserved" 7 "reserved" ;
VAL_ 1068 Recording_Trigger 0 "Normal" 1 "Record_request" ;
VAL_ 1068 VDT_Recall_Req 0 "NoReq" 1 "RecallA (report)" 2 "RecallB (report)" 3 "RecallC (report)" 4 "RecallD (report)" 5 "RecallA (Clear)" 6 "RecallB (Clear)" 7 "RecallC (Clear)" 8 "RecallD (Clear)" 9 "RecallE (report)" 10 "RecallE (Clear)" 11 "RecallF (report)" 12 "RecallF (Clear)" 13 "reserved" 14 "reserved" 15 "All Clear" ;
VAL_ 1068 TCU_ComFail_B_Actl 0 "Normal" 1 "Fail" ;
VAL_ 1068 VDT_BCM_Std3_ResTCU 0 "reserve" 1 "Accept" 2 "Reject" 3 "Completed" ;
VAL_ 1068 VDT_VCM_ODR2_ResTCU 0 "reserve" 1 "Accept" 2 "Reject" 3 "Completed" ;
VAL_ 1068 VDT_TCM_ODR2_ResTCU 0 "reserve" 1 "Accept" 2 "Reject" 3 "Completed" ;
VAL_ 1068 VDT_PCM_ODR2_ResTCU 0 "reserve" 1 "Accept" 2 "Reject" 3 "Completed" ;
VAL_ 1068 VDT_BCM_Std2_ResTCU 0 "reserve" 1 "Accept" 2 "Reject" 3 "Completed" ;
VAL_ 1068 VDT_VCM_ODR1_ResTCU 0 "reserve" 1 "Accept" 2 "Reject" 3 "Completed" ;
VAL_ 1068 VDT_PCM_ODR1_ResTCU 0 "reserve" 1 "Accept" 2 "Reject" 3 "Completed" ;
VAL_ 1068 VDT_BCM_Std1_ResTCU 0 "reserve" 1 "Accept" 2 "Reject" 3 "Completed" ;
VAL_ 1068 CallMute_B_Actl 0 "Reserved" 1 "Mute_Request" 2 "Unmute_Request" 3 "reserved" ;
VAL_ 1066 View_RPC_APS_Sw_D_Qf 0 "Faulty" 1 "Undefined" 2 "Not within Specification" 3 "OK" ;
VAL_ 1066 View_RPC_APS_Sw_B_Actl 0 "Off" 1 "On" ;
VAL_ 1066 HdcSw_D_Actl 0 "OFF" 1 "ON" 2 "UNKNOWN" 3 "reserved" ;
VAL_ 1066 FirstRowBuckleDriver 0 "driver belt not used" 1 "driver belt used" 2 "fault(hole IC switch)/resrve(mec" 3 "reserve" ;
VAL_ 1046 EBB_DisplayRequestB_ECB 0 "Off" 1 "On" ;
VAL_ 1046 EBB_DisplayRequestA_ECB 0 "Off" 1 "On" ;
VAL_ 1046 BrkCtlLamp_D_Rq_ECB 0 "Off" 1 "On" 2 "Slow_Flash(0.5Hz)" 3 "Fast_Flash(2.0Hz)" ;
VAL_ 1046 BrkLamp_B_Rq_ECB 0 "No" 1 "Yes" ;
VAL_ 1045 Hdc_DisplayRequest_1 0 "Off" 1 "canceled by fail" 2 "canceled by high temp" 3 "canceled by speed" 4 "rejected by fail" 5 "rejected by high temp" 6 "rejected by speed" 7 "rejected by ADAS" ;
VAL_ 1045 EPB_TrqRequire 0 "Not Require" 1 "Require" ;
VAL_ 1045 EPB_IGoff_Apply_Inhibit 0 "Not Inhibit" 1 "Inhibit" ;
VAL_ 1045 RGN_StpLmp_Fail_Flag 0 "No" 1 "Yes" ;
VAL_ 1045 LDA_B_Falt 0 "Off" 1 "On" ;
VAL_ 1045 BrkFluidLvl_D_Actl 0 "Normal" 1 "Low" 2 "Reserved" 3 "Unknown" ;
VAL_ 1045 DSC_OnOff_status 0 "ON" 1 "OFF" ;
VAL_ 1045 TCS_ENG_FAILD 0 "No" 1 "Yes" ;
VAL_ 1045 TCS_BRK_FAILD 0 "No" 1 "Yes" ;
VAL_ 1045 Dsc_B_Falt 0 "No" 1 "Yes" ;
VAL_ 1045 EPB_Status 0 "Released" 1 "Applied" 2 "In operation (applying/releasing" 3 "Waiting for operating" 4 "Unknown" ;
VAL_ 1045 EPB_SwitchPosition 0 "No request" 1 "Release request" 2 "Apply request" 3 "Error" ;
VAL_ 1045 EPB_EnableExternalApply_TCM 0 "Not enable" 1 "Enable" ;
VAL_ 1045 EPB_EnableDecelRequest 0 "Not enable" 1 "Enable" ;
VAL_ 1045 EPB_EnableExternalApply_VCM 0 "Not enable" 1 "Enable" ;
VAL_ 1045 Hdc_ActLamp_D_Rq 0 "off" 1 "standby" 2 "active" 3 "inactive" ;
VAL_ 1045 OffSwitch_Info 0 "DSC_Off_Equipped" 1 "TCS_Off_Equipped" 2 "None" 3 "OFF_ROAD_Equipped" ;
VAL_ 1045 AutoHoldStdbyLamp_D_Rq 0 "Off" 1 "On" 2 "Slow Flash (1.4Hz)" 3 "Slow Flash (1.4Hz)" ;
VAL_ 1045 EPB_IGoff_Apply_Buzzer 0 "Off" 1 "On" ;
VAL_ 1045 EBB_DisplayRequestB 0 "Off" 1 "On" ;
VAL_ 1045 EBB_DisplayRequestA 0 "Off" 1 "On" ;
VAL_ 1045 EPB_DisplayRequest5 0 "EPB is in maitenance mode OFF" 1 "EPB is in maitenance mode ON" ;
VAL_ 1045 EPB_DisplayRequest4 0 "P brake is not available OFF" 1 "P brake is not available ON" ;
VAL_ 1045 EPB_DisplayRequest3 0 "System inspection rq OFF" 1 "System inspection rq ON" ;
VAL_ 1045 EPB_DisplayRequest2 0 "Parking Brake is applied OFF" 1 "Parking Brake is applied ON" ;
VAL_ 1045 EPB_DisplayRequest1 0 "Depress Brake Pedal OFF" 1 "Depress Brake Pedal ON" ;
VAL_ 1045 HydraulicHoldDis_B_Rq4 0 "Off" 1 "On" ;
VAL_ 1045 HydraulicHoldDis_B_Rq3 0 "Off" 1 "On" ;
VAL_ 1045 HydraulicHoldDis_B_Rq2 0 "Off" 1 "On" ;
VAL_ 1045 HydraulicHoldDis_B_Rq1 0 "Off" 1 "On" ;
VAL_ 1045 HydraulicHoldActLamp_D_Rq 0 "Off" 1 "On" ;
VAL_ 1045 DrvSlipCtlGuid_D_Rq 0 "Off" 1 "On" ;
VAL_ 1045 DrvAntiLckGuid_D_Rq 0 "Off" 1 "On" ;
VAL_ 1045 DrvEBDGuid_D_Rq 0 "Off" 1 "On" ;
VAL_ 1044 PrkBrkActv_D_Actl 0 "Off" 1 "ON" 2 "Reserved" 3 "Unknown" ;
VAL_ 1044 DrvSlipCtlMde_D_Ind 0 "Default_Mode" 1 "App_Specific_Off_Mode1" 2 "App_Specific_Off_Mode2" 3 "App_Specific_Off_Mode3" ;
VAL_ 1044 DrvSlipCtlLamp_D_Rq 0 "Off" 1 "On" 2 "Slow_Flash" 3 "Fast_Flash" ;
VAL_ 1044 DrvAntiLckLamp_D_Rq 0 "Off" 1 "On" 2 "Slow_Flash" 3 "Fast_Flash" ;
VAL_ 1044 BrkCtlLamp_D_Rq 0 "Off" 1 "On" 2 "Slow_Flash(0.5Hz)" 3 "Fast_Flash(2.0Hz)" ;
VAL_ 1044 ParkBrkTelltale_B_Actl 0 "Off" 1 "On" 2 "Flash(1.0Hz)" 3 "Not Used" ;
VAL_ 1044 BrkLamp_B_Rq 0 "No" 1 "Yes" ;
VAL_ 1034 GCC_CfgParam 240 "BlockNoF0" 241 "BlockNoF1" 242 "BlockNoF2" 243 "BlockNoF3" 1 "BlockNo01" 2 "BlockNo02" 3 "BlockNo03" 4 "BlockNo04" 5 "BlockNo05" 6 "BlockNo06" 16 "BlockNo10" 17 "BlockNo11" 18 "BlockNo12" 19 "BlockNo13" 20 "BlockNo14" 21 "BlockNo15" 22 "BlockNo16" 32 "BlockNo20" 37 "BlockNo25" 48 "BlockNo30" 64 "BlockNo40" 80 "BlockNo50" 82 "BlockNo52" 96 "BlockNo60" 98 "BlockNo62" 99 "BlockNo63" 112 "BlockNo70" 114 "BlockNo72" 128 "BlockNo80" 130 "BlockNo82" 144 "BlockNo90" 145 "BlockNo91" 146 "BlockNo92" 147 "BlockNo93" 148 "BlockNo94" 149 "BlockNo95" 224 "BlockNoE0" ;
